[part 20 of 22: package /ComponentTypes]
AUTOSAR XML (schema 4-3-0)
package /ComponentTypes  (continued)
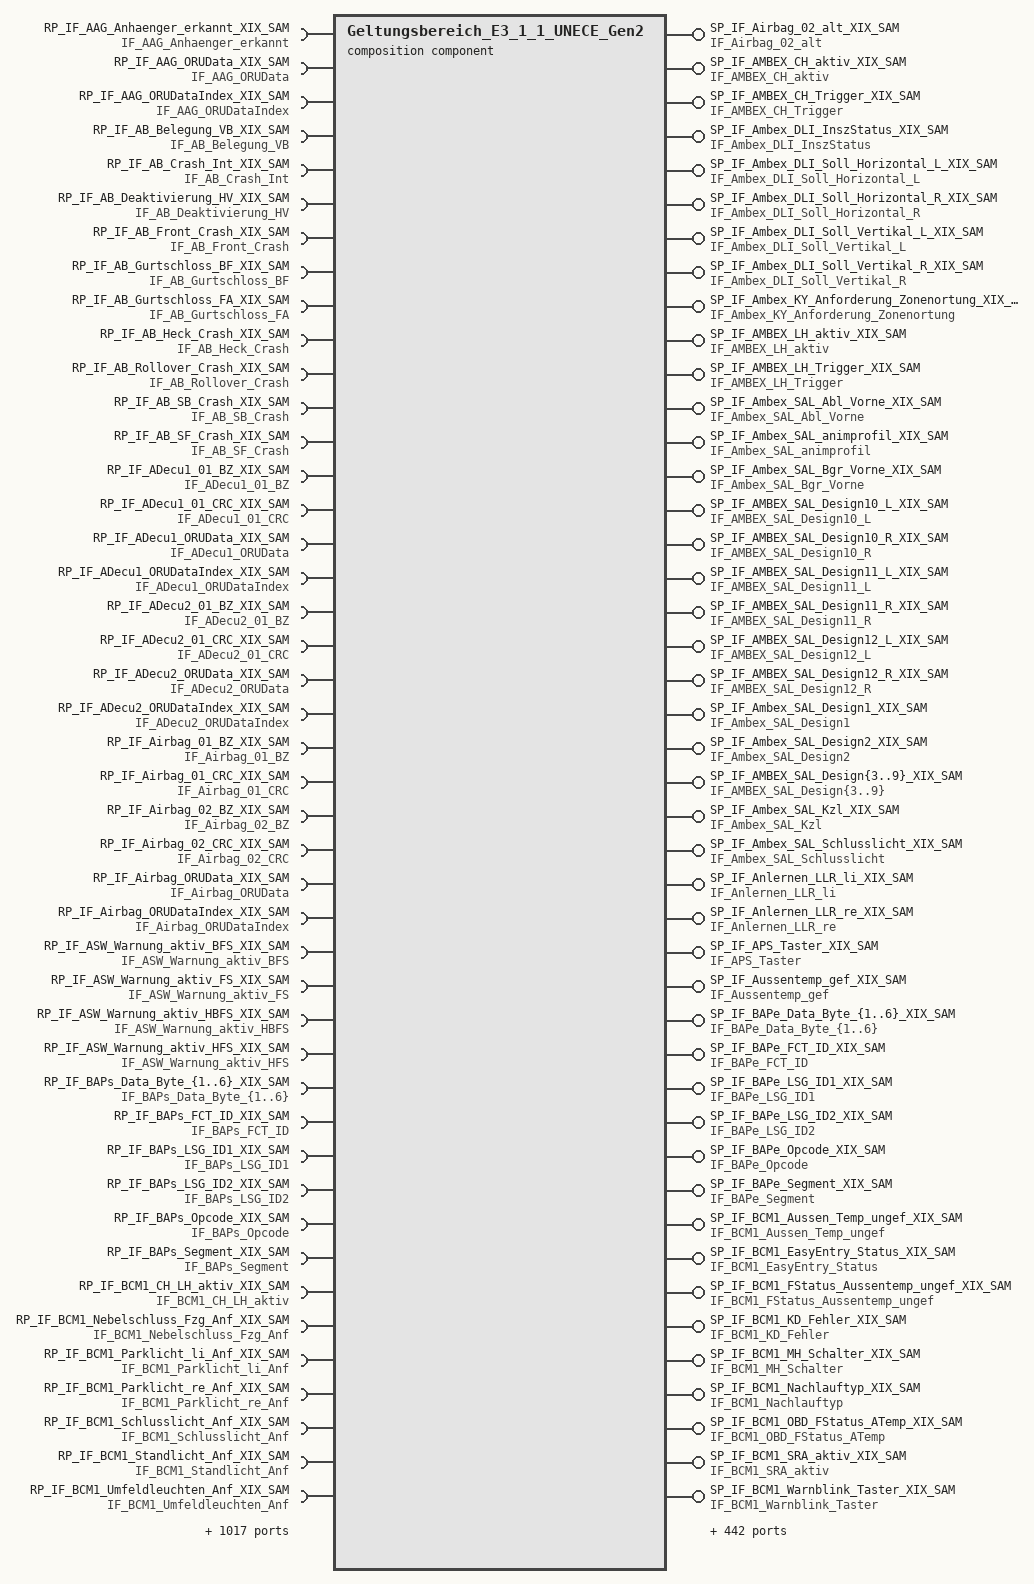
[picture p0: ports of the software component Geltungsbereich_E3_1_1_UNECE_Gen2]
  composition sw component type Geltungsbereich_E3_1_1_UNECE_Gen2
    540 x provide port:
      SP_IF_Airbag_02_alt_XIX_SAM: provided-interface=IF_Airbag_02_alt
      SP_IF_AMBEX_CH_aktiv_XIX_SAM: provided-interface=IF_AMBEX_CH_aktiv
      SP_IF_AMBEX_CH_Trigger_XIX_SAM: provided-interface=IF_AMBEX_CH_Trigger
      SP_IF_Ambex_DLI_InszStatus_XIX_SAM: provided-interface=IF_Ambex_DLI_InszStatus
      SP_IF_Ambex_DLI_Soll_Horizontal_L_XIX_SAM: provided-interface=IF_Ambex_DLI_Soll_Horizontal_L
      SP_IF_Ambex_DLI_Soll_Horizontal_R_XIX_SAM: provided-interface=IF_Ambex_DLI_Soll_Horizontal_R
      SP_IF_Ambex_DLI_Soll_Vertikal_L_XIX_SAM: provided-interface=IF_Ambex_DLI_Soll_Vertikal_L
      SP_IF_Ambex_DLI_Soll_Vertikal_R_XIX_SAM: provided-interface=IF_Ambex_DLI_Soll_Vertikal_R
      SP_IF_Ambex_KY_Anforderung_Zonenortung_XIX_SAM: provided-interface=IF_Ambex_KY_Anforderung_Zonenortung
      SP_IF_AMBEX_LH_aktiv_XIX_SAM: provided-interface=IF_AMBEX_LH_aktiv
      SP_IF_AMBEX_LH_Trigger_XIX_SAM: provided-interface=IF_AMBEX_LH_Trigger
      SP_IF_Ambex_SAL_Abl_Vorne_XIX_SAM: provided-interface=IF_Ambex_SAL_Abl_Vorne
      SP_IF_Ambex_SAL_animprofil_XIX_SAM: provided-interface=IF_Ambex_SAL_animprofil
      SP_IF_Ambex_SAL_Bgr_Vorne_XIX_SAM: provided-interface=IF_Ambex_SAL_Bgr_Vorne
      SP_IF_AMBEX_SAL_Design10_L_XIX_SAM: provided-interface=IF_AMBEX_SAL_Design10_L
      SP_IF_AMBEX_SAL_Design10_R_XIX_SAM: provided-interface=IF_AMBEX_SAL_Design10_R
      SP_IF_AMBEX_SAL_Design11_L_XIX_SAM: provided-interface=IF_AMBEX_SAL_Design11_L
      SP_IF_AMBEX_SAL_Design11_R_XIX_SAM: provided-interface=IF_AMBEX_SAL_Design11_R
      SP_IF_AMBEX_SAL_Design12_L_XIX_SAM: provided-interface=IF_AMBEX_SAL_Design12_L
      SP_IF_AMBEX_SAL_Design12_R_XIX_SAM: provided-interface=IF_AMBEX_SAL_Design12_R
      SP_IF_Ambex_SAL_Design1_XIX_SAM: provided-interface=IF_Ambex_SAL_Design1
      SP_IF_Ambex_SAL_Design2_XIX_SAM: provided-interface=IF_Ambex_SAL_Design2
      SP_IF_AMBEX_SAL_Design{3..9}_XIX_SAM: provided-interface=IF_AMBEX_SAL_Design{3..9}
      SP_IF_Ambex_SAL_Kzl_XIX_SAM: provided-interface=IF_Ambex_SAL_Kzl
      SP_IF_Ambex_SAL_Schlusslicht_XIX_SAM: provided-interface=IF_Ambex_SAL_Schlusslicht
      SP_IF_Anlernen_LLR_li_XIX_SAM: provided-interface=IF_Anlernen_LLR_li
      SP_IF_Anlernen_LLR_re_XIX_SAM: provided-interface=IF_Anlernen_LLR_re
      SP_IF_APS_Taster_XIX_SAM: provided-interface=IF_APS_Taster
      SP_IF_Aussentemp_gef_XIX_SAM: provided-interface=IF_Aussentemp_gef
      SP_IF_BAPe_Data_Byte_{1..6}_XIX_SAM: provided-interface=IF_BAPe_Data_Byte_{1..6}
      SP_IF_BAPe_FCT_ID_XIX_SAM: provided-interface=IF_BAPe_FCT_ID
      SP_IF_BAPe_LSG_ID1_XIX_SAM: provided-interface=IF_BAPe_LSG_ID1
      SP_IF_BAPe_LSG_ID2_XIX_SAM: provided-interface=IF_BAPe_LSG_ID2
      SP_IF_BAPe_Opcode_XIX_SAM: provided-interface=IF_BAPe_Opcode
      SP_IF_BAPe_Segment_XIX_SAM: provided-interface=IF_BAPe_Segment
      SP_IF_BCM1_Aussen_Temp_ungef_XIX_SAM: provided-interface=IF_BCM1_Aussen_Temp_ungef
      SP_IF_BCM1_EasyEntry_Status_XIX_SAM: provided-interface=IF_BCM1_EasyEntry_Status
      SP_IF_BCM1_FStatus_Aussentemp_ungef_XIX_SAM: provided-interface=IF_BCM1_FStatus_Aussentemp_ungef
      SP_IF_BCM1_KD_Fehler_XIX_SAM: provided-interface=IF_BCM1_KD_Fehler
      SP_IF_BCM1_MH_Schalter_XIX_SAM: provided-interface=IF_BCM1_MH_Schalter
      SP_IF_BCM1_Nachlauftyp_XIX_SAM: provided-interface=IF_BCM1_Nachlauftyp
      SP_IF_BCM1_OBD_FStatus_ATemp_XIX_SAM: provided-interface=IF_BCM1_OBD_FStatus_ATemp
      SP_IF_BCM1_SRA_aktiv_XIX_SAM: provided-interface=IF_BCM1_SRA_aktiv
      SP_IF_BCM1_Warnblink_Taster_XIX_SAM: provided-interface=IF_BCM1_Warnblink_Taster
      SP_IF_BCM_01_BZ_XIX_SAM: provided-interface=IF_BCM_01_BZ
      SP_IF_BCM_01_CRC_XIX_SAM: provided-interface=IF_BCM_01_CRC
      SP_IF_BCM_BFS_aktive_MuFu_Fkt_XIX_SAM: provided-interface=IF_BCM_BFS_aktive_MuFu_Fkt
      SP_IF_BCM_BFS_Fernsteuerung_aktiv_XIX_SAM: provided-interface=IF_BCM_BFS_Fernsteuerung_aktiv
      SP_IF_BCM_BFS_Lordose_ab_XIX_SAM: provided-interface=IF_BCM_BFS_Lordose_ab
      SP_IF_BCM_BFS_Lordose_auf_XIX_SAM: provided-interface=IF_BCM_BFS_Lordose_auf
      SP_IF_BCM_BFS_Lordose_vor_XIX_SAM: provided-interface=IF_BCM_BFS_Lordose_vor
      SP_IF_BCM_BFS_Lordose_zurueck_XIX_SAM: provided-interface=IF_BCM_BFS_Lordose_zurueck
      SP_IF_BCM_BFS_Massage_Dauer_XIX_SAM: provided-interface=IF_BCM_BFS_Massage_Dauer
      SP_IF_BCM_BFS_Massage_Intens_Lehne_XIX_SAM: provided-interface=IF_BCM_BFS_Massage_Intens_Lehne
      SP_IF_BCM_BFS_Massage_Intens_Sitz_XIX_SAM: provided-interface=IF_BCM_BFS_Massage_Intens_Sitz
      SP_IF_BCM_BFS_Massage_Intensitaet_XIX_SAM: provided-interface=IF_BCM_BFS_Massage_Intensitaet
      SP_IF_BCM_BFS_Massage_Prg_erweitert_XIX_SAM: provided-interface=IF_BCM_BFS_Massage_Prg_erweitert
      SP_IF_BCM_BFS_Massage_Prg_XIX_SAM: provided-interface=IF_BCM_BFS_Massage_Prg
      SP_IF_BCM_BFS_Massage_Taster_XIX_SAM: provided-interface=IF_BCM_BFS_Massage_Taster
      SP_IF_BCM_BFS_Memory_Abbruch_XIX_SAM: provided-interface=IF_BCM_BFS_Memory_Abbruch
      SP_IF_BCM_BFS_Memory_Pos_XIX_SAM: provided-interface=IF_BCM_BFS_Memory_Pos
      SP_IF_BCM_BFS_Memory_Save_Recall_XIX_SAM: provided-interface=IF_BCM_BFS_Memory_Save_Recall
      SP_IF_BCM_BFS_MSG_Status_XIX_SAM: provided-interface=IF_BCM_BFS_MSG_Status
      SP_IF_BCM_BFS_Multif_Taster_XIX_SAM: provided-interface=IF_BCM_BFS_Multif_Taster
      SP_IF_BCM_BFS_Pneumatik_Verstellung_XIX_SAM: provided-interface=IF_BCM_BFS_Pneumatik_Verstellung
      SP_IF_BCM_BFS_PreCrash_XIX_SAM: provided-interface=IF_BCM_BFS_PreCrash
      SP_IF_BCM_BFS_Programmwippe_XIX_SAM: provided-interface=IF_BCM_BFS_Programmwippe
      SP_IF_BCM_BFS_SW_eng_XIX_SAM: provided-interface=IF_BCM_BFS_SW_eng
      SP_IF_BCM_BFS_SW_weit_XIX_SAM: provided-interface=IF_BCM_BFS_SW_weit
      SP_IF_BCM_BFS_Wellness_Status_XIX_SAM: provided-interface=IF_BCM_BFS_Wellness_Status
      SP_IF_BCM_BFT_geoeffnet_plaus_XIX_SAM: provided-interface=IF_BCM_BFT_geoeffnet_plaus
      SP_IF_BCM_Bremsbelag_Sensor_CND_XIX_SAM: provided-interface=IF_BCM_Bremsbelag_Sensor_CND
      SP_IF_BCM_Bremsbelag_Sensor_NAR_XIX_SAM: provided-interface=IF_BCM_Bremsbelag_Sensor_NAR
      SP_IF_BCM_Bremsbelag_Sensor_Rdw_XIX_SAM: provided-interface=IF_BCM_Bremsbelag_Sensor_Rdw
      SP_IF_BCM_Bremsbelag_Sensor_XIX_SAM: provided-interface=IF_BCM_Bremsbelag_Sensor
      SP_IF_BCM_Bremsfluessigkeit_Sensor_XIX_SAM: provided-interface=IF_BCM_Bremsfluessigkeit_Sensor
      SP_IF_BCM_Drehwinkel_HL_XIX_SAM: provided-interface=IF_BCM_Drehwinkel_HL
      SP_IF_BCM_Drehwinkel_VL_XIX_SAM: provided-interface=IF_BCM_Drehwinkel_VL
      SP_IF_BCM_Drehwinkelsensortausch_HL_XIX_SAM: provided-interface=IF_BCM_Drehwinkelsensortausch_HL
      SP_IF_BCM_Drehwinkelsensortausch_VL_XIX_SAM: provided-interface=IF_BCM_Drehwinkelsensortausch_VL
      SP_IF_BCM_Eco_Charisma_Taste_XIX_SAM: provided-interface=IF_BCM_Eco_Charisma_Taste
      SP_IF_BCM_Fehlerspeicher_loeschen_XIX_SAM: provided-interface=IF_BCM_Fehlerspeicher_loeschen
      SP_IF_BCM_FH_Freigabe_XIX_SAM: provided-interface=IF_BCM_FH_Freigabe
      SP_IF_BCM_FS_aktive_MuFu_Fkt_XIX_SAM: provided-interface=IF_BCM_FS_aktive_MuFu_Fkt
      SP_IF_BCM_FS_Lordose_ab_XIX_SAM: provided-interface=IF_BCM_FS_Lordose_ab
      SP_IF_BCM_FS_Lordose_auf_XIX_SAM: provided-interface=IF_BCM_FS_Lordose_auf
      SP_IF_BCM_FS_Lordose_vor_XIX_SAM: provided-interface=IF_BCM_FS_Lordose_vor
      SP_IF_BCM_FS_Lordose_zurueck_XIX_SAM: provided-interface=IF_BCM_FS_Lordose_zurueck
      SP_IF_BCM_FS_Massage_Dauer_XIX_SAM: provided-interface=IF_BCM_FS_Massage_Dauer
      SP_IF_BCM_FS_Massage_Intens_Lehne_XIX_SAM: provided-interface=IF_BCM_FS_Massage_Intens_Lehne
      SP_IF_BCM_FS_Massage_Intens_Sitz_XIX_SAM: provided-interface=IF_BCM_FS_Massage_Intens_Sitz
      SP_IF_BCM_FS_Massage_Intensitaet_XIX_SAM: provided-interface=IF_BCM_FS_Massage_Intensitaet
      SP_IF_BCM_FS_Massage_Prg_erweitert_XIX_SAM: provided-interface=IF_BCM_FS_Massage_Prg_erweitert
      SP_IF_BCM_FS_Massage_Prg_XIX_SAM: provided-interface=IF_BCM_FS_Massage_Prg
      SP_IF_BCM_FS_Massage_Taster_XIX_SAM: provided-interface=IF_BCM_FS_Massage_Taster
      SP_IF_BCM_FS_Memory_Abbruch_XIX_SAM: provided-interface=IF_BCM_FS_Memory_Abbruch
      SP_IF_BCM_FS_Memory_Pos_XIX_SAM: provided-interface=IF_BCM_FS_Memory_Pos
      SP_IF_BCM_FS_Memory_Save_Recall_XIX_SAM: provided-interface=IF_BCM_FS_Memory_Save_Recall
      SP_IF_BCM_FS_MSG_Status_XIX_SAM: provided-interface=IF_BCM_FS_MSG_Status
      SP_IF_BCM_FS_Multif_Taster_XIX_SAM: provided-interface=IF_BCM_FS_Multif_Taster
      SP_IF_BCM_FS_Pneumatik_Verstellung_XIX_SAM: provided-interface=IF_BCM_FS_Pneumatik_Verstellung
      SP_IF_BCM_FS_PreCrash_XIX_SAM: provided-interface=IF_BCM_FS_PreCrash
      SP_IF_BCM_FS_Programmwippe_XIX_SAM: provided-interface=IF_BCM_FS_Programmwippe
      SP_IF_BCM_FS_SW_eng_XIX_SAM: provided-interface=IF_BCM_FS_SW_eng
      SP_IF_BCM_FS_SW_weit_XIX_SAM: provided-interface=IF_BCM_FS_SW_weit
      SP_IF_BCM_FS_Wellness_Status_XIX_SAM: provided-interface=IF_BCM_FS_Wellness_Status
      SP_IF_BCM_FT_geoeffnet_plaus_XIX_SAM: provided-interface=IF_BCM_FT_geoeffnet_plaus
      SP_IF_BCM_Kennung_RL_Fzg_XIX_SAM: provided-interface=IF_BCM_Kennung_RL_Fzg
      SP_IF_BCM_KiSi_Umschalt_gesperrt_XIX_SAM: provided-interface=IF_BCM_KiSi_Umschalt_gesperrt
      SP_IF_BCM_Komfortfkt_Freigabe_XIX_SAM: provided-interface=IF_BCM_Komfortfkt_Freigabe
      SP_IF_BCM_Kuehlmittel_Sensor_XIX_SAM: provided-interface=IF_BCM_Kuehlmittel_Sensor
      SP_IF_BCM_LINDa_Toggle_XIX_SAM: provided-interface=IF_BCM_LINDa_Toggle
      SP_IF_BCM_LRH_Taster_XIX_SAM: provided-interface=IF_BCM_LRH_Taster
      SP_IF_BCM_P_Mode_aktiv_XIX_SAM: provided-interface=IF_BCM_P_Mode_aktiv
      SP_IF_BCM_P_Mode_FH_Kl15_aus_aktiv_XIX_SAM: provided-interface=IF_BCM_P_Mode_FH_Kl15_aus_aktiv
      SP_IF_BCM_P_Mode_FH_Reversierschwelle_XIX_SAM: provided-interface=IF_BCM_P_Mode_FH_Reversierschwelle
      SP_IF_BCM_RACE_Mode_aktiv_XIX_SAM: provided-interface=IF_BCM_RACE_Mode_aktiv
      SP_IF_BCM_RGB_Adressierungsart_XIX_SAM: provided-interface=IF_BCM_RGB_Adressierungsart
      SP_IF_BCM_RGB_Bewertung_Dimmzeit_XIX_SAM: provided-interface=IF_BCM_RGB_Bewertung_Dimmzeit
      SP_IF_BCM_RGB_Blau_XIX_SAM: provided-interface=IF_BCM_RGB_Blau
      SP_IF_BCM_RGB_Dimmrampe_XIX_SAM: provided-interface=IF_BCM_RGB_Dimmrampe
      SP_IF_BCM_RGB_Dimmzeit_Zeitbasis_XIX_SAM: provided-interface=IF_BCM_RGB_Dimmzeit_Zeitbasis
      SP_IF_BCM_RGB_Gruen_XIX_SAM: provided-interface=IF_BCM_RGB_Gruen
      SP_IF_BCM_RGB_Gueltigkeit_XIX_SAM: provided-interface=IF_BCM_RGB_Gueltigkeit
      SP_IF_BCM_RGB_Intensitaet_XIX_SAM: provided-interface=IF_BCM_RGB_Intensitaet
      SP_IF_BCM_RGB_Normierung_Intensitaet_XIX_SAM: provided-interface=IF_BCM_RGB_Normierung_Intensitaet
      SP_IF_BCM_RGB_Rot_XIX_SAM: provided-interface=IF_BCM_RGB_Rot
      SP_IF_BCM_RGB_Slave_Adresse_XIX_SAM: provided-interface=IF_BCM_RGB_Slave_Adresse
      SP_IF_BCM_RGB_Sonderfunktion_XIX_SAM: provided-interface=IF_BCM_RGB_Sonderfunktion
      SP_IF_BCM_SBE_XIX_SAM: provided-interface=IF_BCM_SBE
      SP_IF_BCM_SGT_Pumpe_BFS_XIX_SAM: provided-interface=IF_BCM_SGT_Pumpe_BFS
      SP_IF_BCM_SGT_Pumpe_FS_XIX_SAM: provided-interface=IF_BCM_SGT_Pumpe_FS
      SP_IF_BCM_SPR_Nachregelung_Freigabe_XIX_SAM: provided-interface=IF_BCM_SPR_Nachregelung_Freigabe
      SP_IF_BCM_Systemfunkionstest_BFS_XIX_SAM: provided-interface=IF_BCM_Systemfunkionstest_BFS
      SP_IF_BCM_Systemfunkionstest_FS_XIX_SAM: provided-interface=IF_BCM_Systemfunkionstest_FS
      SP_IF_BCM_Tankklappensteller_Fehler_XIX_SAM: provided-interface=IF_BCM_Tankklappensteller_Fehler
      SP_IF_BCM_Waschwasser_Sensor_XIX_SAM: provided-interface=IF_BCM_Waschwasser_Sensor
      SP_IF_BCM_Wischer_Parklage_XIX_SAM: provided-interface=IF_BCM_Wischer_Parklage
      SP_IF_Bel_DiETa_Car_XIX_SAM: provided-interface=IF_Bel_DiETa_Car
      SP_IF_Bel_DiETa_Lock_Unlock_XIX_SAM: provided-interface=IF_Bel_DiETa_Lock_Unlock
      SP_IF_Bel_LiSi_Defrost_XIX_SAM: provided-interface=IF_Bel_LiSi_Defrost
      SP_IF_Bel_LiSi_FSH_XIX_SAM: provided-interface=IF_Bel_LiSi_FSH
      SP_IF_Bel_LiSi_HSH_XIX_SAM: provided-interface=IF_Bel_LiSi_HSH
      SP_IF_BH_Blinker_Fehler_XIX_SAM: provided-interface=IF_BH_Blinker_Fehler
      SP_IF_BH_Blinker_li_XIX_SAM: provided-interface=IF_BH_Blinker_li
      SP_IF_BH_Blinker_re_XIX_SAM: provided-interface=IF_BH_Blinker_re
      SP_IF_BH_Fernlicht_XIX_SAM: provided-interface=IF_BH_Fernlicht
      SP_IF_BH_Lichthupe_XIX_SAM: provided-interface=IF_BH_Lichthupe
      SP_IF_BRL_Bremslicht_Schalter_XIX_SAM: provided-interface=IF_BRL_Bremslicht_Schalter
      SP_IF_Deaktivierung_RS_XIX_SAM: provided-interface=IF_Deaktivierung_RS
      SP_IF_DI_KL_58xd_XIX_SAM: provided-interface=IF_DI_KL_58xd
      SP_IF_DI_KL_58xs_XIX_SAM: provided-interface=IF_DI_KL_58xs
      SP_IF_Empfindlichkeit_LS_XIX_SAM: provided-interface=IF_Empfindlichkeit_LS
      SP_IF_Empfindlichkeit_RS_XIX_SAM: provided-interface=IF_Empfindlichkeit_RS
      SP_IF_ESP_v_Signal_8Bit_XIX_SAM: provided-interface=IF_ESP_v_Signal_8Bit
      SP_IF_ESP_v_Signal_XIX_SAM: provided-interface=IF_ESP_v_Signal
      SP_IF_FAS_Profile_Taster_XIX_SAM: provided-interface=IF_FAS_Profile_Taster
      SP_IF_FAS_Taster_Fehler_XIX_SAM: provided-interface=IF_FAS_Taster_Fehler
      SP_IF_FAS_Taster_XIX_SAM: provided-interface=IF_FAS_Taster
      SP_IF_FHSG_MST_Architektur_XIX_SAM: provided-interface=IF_FHSG_MST_Architektur
      SP_IF_FHSG_MST_Aussentemp_ungefiltert_XIX_SAM: provided-interface=IF_FHSG_MST_Aussentemp_ungefiltert
      SP_IF_FHSG_MST_BT_Blockerwartung_XIX_SAM: provided-interface=IF_FHSG_MST_BT_Blockerwartung
      SP_IF_FHSG_MST_Crashfall_erkannt_XIX_SAM: provided-interface=IF_FHSG_MST_Crashfall_erkannt
      SP_IF_FHSG_MST_FH_HBFS_AutoHoch_XIX_SAM: provided-interface=IF_FHSG_MST_FH_HBFS_AutoHoch
      SP_IF_FHSG_MST_FH_HBFS_AutoTief_XIX_SAM: provided-interface=IF_FHSG_MST_FH_HBFS_AutoTief
      SP_IF_FHSG_MST_FH_HBFS_ManHoch_XIX_SAM: provided-interface=IF_FHSG_MST_FH_HBFS_ManHoch
      SP_IF_FHSG_MST_FH_HBFS_ManTief_XIX_SAM: provided-interface=IF_FHSG_MST_FH_HBFS_ManTief
      SP_IF_FHSG_MST_FH_HFS_AutoHoch_XIX_SAM: provided-interface=IF_FHSG_MST_FH_HFS_AutoHoch
      SP_IF_FHSG_MST_FH_HFS_AutoTief_XIX_SAM: provided-interface=IF_FHSG_MST_FH_HFS_AutoTief
      SP_IF_FHSG_MST_FH_HFS_ManHoch_XIX_SAM: provided-interface=IF_FHSG_MST_FH_HFS_ManHoch
      SP_IF_FHSG_MST_FH_HFS_ManTief_XIX_SAM: provided-interface=IF_FHSG_MST_FH_HFS_ManTief
      SP_IF_FHSG_MST_FH_KomfortHoch_XIX_SAM: provided-interface=IF_FHSG_MST_FH_KomfortHoch
      SP_IF_FHSG_MST_FH_Komforttief_XIX_SAM: provided-interface=IF_FHSG_MST_FH_Komforttief
      SP_IF_FHSG_MST_FT_Blockerwartung_XIX_SAM: provided-interface=IF_FHSG_MST_FT_Blockerwartung
      SP_IF_FHSG_MST_FT_FH_H_Kisi_ein_XIX_SAM: provided-interface=IF_FHSG_MST_FT_FH_H_Kisi_ein
      SP_IF_FHSG_MST_HBFS_Blockerwartung_XIX_SAM: provided-interface=IF_FHSG_MST_HBFS_Blockerwartung
      SP_IF_FHSG_MST_HFS_Blockerwartung_XIX_SAM: provided-interface=IF_FHSG_MST_HFS_Blockerwartung
      SP_IF_FHSG_MST_Lenkigkeit_XIX_SAM: provided-interface=IF_FHSG_MST_Lenkigkeit
      SP_IF_FHSG_MST_Precrash_XIX_SAM: provided-interface=IF_FHSG_MST_Precrash
      SP_IF_Fronthaube_geoeffnet_XIX_SAM: provided-interface=IF_Fronthaube_geoeffnet
      SP_IF_FS_Luftfeuchte_rel_XIX_SAM: provided-interface=IF_FS_Luftfeuchte_rel
      SP_IF_FS_ResponseError_XIX_SAM: provided-interface=IF_FS_ResponseError
      SP_IF_FS_Taupunkt_XIX_SAM: provided-interface=IF_FS_Taupunkt
      SP_IF_FS_Temp_Scheibe_XIX_SAM: provided-interface=IF_FS_Temp_Scheibe
      SP_IF_FS_Temp_Sensor_XIX_SAM: provided-interface=IF_FS_Temp_Sensor
      SP_IF_HBFS_FH_Bew_hoch_XIX_SAM: provided-interface=IF_HBFS_FH_Bew_hoch
      SP_IF_HBFS_FH_Bew_tief_XIX_SAM: provided-interface=IF_HBFS_FH_Bew_tief
      SP_IF_HBFS_FH_Block_XIX_SAM: provided-interface=IF_HBFS_FH_Block
      SP_IF_HBFS_FH_Fang_XIX_SAM: provided-interface=IF_HBFS_FH_Fang
      SP_IF_HBFS_FH_normiert_XIX_SAM: provided-interface=IF_HBFS_FH_normiert
      SP_IF_HBFS_FH_Oeffnung_XIX_SAM: provided-interface=IF_HBFS_FH_Oeffnung
      SP_IF_HBFS_FH_S_AutoHoch_XIX_SAM: provided-interface=IF_HBFS_FH_S_AutoHoch
      SP_IF_HBFS_FH_S_AutoTief_XIX_SAM: provided-interface=IF_HBFS_FH_S_AutoTief
      SP_IF_HBFS_FH_S_ManHoch_XIX_SAM: provided-interface=IF_HBFS_FH_S_ManHoch
      SP_IF_HBFS_FH_S_ManTief_XIX_SAM: provided-interface=IF_HBFS_FH_S_ManTief
      SP_IF_HBFS_FH_Thermo_XIX_SAM: provided-interface=IF_HBFS_FH_Thermo
      SP_IF_HBFS_gesafet_XIX_SAM: provided-interface=IF_HBFS_gesafet
      SP_IF_HBFS_KiSi_Fehler_XIX_SAM: provided-interface=IF_HBFS_KiSi_Fehler
      SP_IF_HBFS_Lock_Taster_inv_XIX_SAM: provided-interface=IF_HBFS_Lock_Taster_inv
      SP_IF_HBFS_Oben_Block_erw_XIX_SAM: provided-interface=IF_HBFS_Oben_Block_erw
      SP_IF_HBFS_Seitenrollo_hoch_XIX_SAM: provided-interface=IF_HBFS_Seitenrollo_hoch
      SP_IF_HBFS_Seitenrollo_tief_XIX_SAM: provided-interface=IF_HBFS_Seitenrollo_tief
      SP_IF_HBFS_SK_betaetigt_XIX_SAM: provided-interface=IF_HBFS_SK_betaetigt
      SP_IF_HBFS_Sperrklinke_XIX_SAM: provided-interface=IF_HBFS_Sperrklinke
      SP_IF_HBFS_Status_KiSi_inv_XIX_SAM: provided-interface=IF_HBFS_Status_KiSi_inv
      SP_IF_HBFS_Status_KiSi_XIX_SAM: provided-interface=IF_HBFS_Status_KiSi
      SP_IF_HBFS_TAG_betaetigt_XIX_SAM: provided-interface=IF_HBFS_TAG_betaetigt
      SP_IF_HBFS_TCR_Mode_aktiv_XIX_SAM: provided-interface=IF_HBFS_TCR_Mode_aktiv
      SP_IF_HBFS_TIG_betaetigt_oeffnen_XIX_SAM: provided-interface=IF_HBFS_TIG_betaetigt_oeffnen
      SP_IF_HBFS_TIG_betaetigt_schliessen_XIX_SAM: provided-interface=IF_HBFS_TIG_betaetigt_schliessen
      SP_IF_HBFS_TIG_betaetigt_XIX_SAM: provided-interface=IF_HBFS_TIG_betaetigt
      SP_IF_HBFS_Tuer_geoeffnet_XIX_SAM: provided-interface=IF_HBFS_Tuer_geoeffnet
      SP_IF_HBFS_Tuer_Status_XIX_SAM: provided-interface=IF_HBFS_Tuer_Status
      SP_IF_HBFS_Tuerschloss_defekt_XIX_SAM: provided-interface=IF_HBFS_Tuerschloss_defekt
      SP_IF_HBFS_UEKB_aktiviert_XIX_SAM: provided-interface=IF_HBFS_UEKB_aktiviert
      SP_IF_HBFS_Unten_Block_erw_XIX_SAM: provided-interface=IF_HBFS_Unten_Block_erw
      SP_IF_HBFS_verriegelt_XIX_SAM: provided-interface=IF_HBFS_verriegelt
      SP_IF_HBFS_Vorraste_betaetigt_XIX_SAM: provided-interface=IF_HBFS_Vorraste_betaetigt
      SP_IF_HD_Hauptraste_Auth_XIX_SAM: provided-interface=IF_HD_Hauptraste_Auth
      SP_IF_HD_Hauptraste_XIX_SAM: provided-interface=IF_HD_Hauptraste
      SP_IF_HD_Vorraste_Auth_XIX_SAM: provided-interface=IF_HD_Vorraste_Auth
      SP_IF_HD_Vorraste_XIX_SAM: provided-interface=IF_HD_Vorraste
      SP_IF_HFS_FH_Bew_hoch_XIX_SAM: provided-interface=IF_HFS_FH_Bew_hoch
      SP_IF_HFS_FH_Bew_tief_XIX_SAM: provided-interface=IF_HFS_FH_Bew_tief
      SP_IF_HFS_FH_Block_XIX_SAM: provided-interface=IF_HFS_FH_Block
      SP_IF_HFS_FH_Fang_XIX_SAM: provided-interface=IF_HFS_FH_Fang
      SP_IF_HFS_FH_normiert_XIX_SAM: provided-interface=IF_HFS_FH_normiert
      SP_IF_HFS_FH_Oeffnung_XIX_SAM: provided-interface=IF_HFS_FH_Oeffnung
      SP_IF_HFS_FH_S_AutoHoch_XIX_SAM: provided-interface=IF_HFS_FH_S_AutoHoch
      SP_IF_HFS_FH_S_AutoTief_XIX_SAM: provided-interface=IF_HFS_FH_S_AutoTief
      SP_IF_HFS_FH_S_ManHoch_XIX_SAM: provided-interface=IF_HFS_FH_S_ManHoch
      SP_IF_HFS_FH_S_ManTief_XIX_SAM: provided-interface=IF_HFS_FH_S_ManTief
      SP_IF_HFS_FH_Thermo_XIX_SAM: provided-interface=IF_HFS_FH_Thermo
      SP_IF_HFS_gesafet_XIX_SAM: provided-interface=IF_HFS_gesafet
      SP_IF_HFS_Heckrollotaster_betaetigt_XIX_SAM: provided-interface=IF_HFS_Heckrollotaster_betaetigt
      SP_IF_HFS_KiSi_Fehler_XIX_SAM: provided-interface=IF_HFS_KiSi_Fehler
      SP_IF_HFS_Lock_Taster_inv_XIX_SAM: provided-interface=IF_HFS_Lock_Taster_inv
      SP_IF_HFS_Oben_Block_erw_XIX_SAM: provided-interface=IF_HFS_Oben_Block_erw
      SP_IF_HFS_Seitenrollo_hoch_XIX_SAM: provided-interface=IF_HFS_Seitenrollo_hoch
      SP_IF_HFS_Seitenrollo_tief_XIX_SAM: provided-interface=IF_HFS_Seitenrollo_tief
      SP_IF_HFS_SK_betaetigt_XIX_SAM: provided-interface=IF_HFS_SK_betaetigt
      SP_IF_HFS_Status_KiSi_XIX_SAM: provided-interface=IF_HFS_Status_KiSi
      SP_IF_HFS_TAG_betaetigt_XIX_SAM: provided-interface=IF_HFS_TAG_betaetigt
      SP_IF_HFS_TCR_Mode_aktiv_XIX_SAM: provided-interface=IF_HFS_TCR_Mode_aktiv
      SP_IF_HFS_TIG_betaetigt_oeffnen_XIX_SAM: provided-interface=IF_HFS_TIG_betaetigt_oeffnen
      SP_IF_HFS_TIG_betaetigt_schliessen_XIX_SAM: provided-interface=IF_HFS_TIG_betaetigt_schliessen
      SP_IF_HFS_TIG_betaetigt_XIX_SAM: provided-interface=IF_HFS_TIG_betaetigt
      SP_IF_HFS_Tuer_geoeffnet_XIX_SAM: provided-interface=IF_HFS_Tuer_geoeffnet
      SP_IF_HFS_Tuer_Status_QBit_XIX_SAM: provided-interface=IF_HFS_Tuer_Status_QBit
      SP_IF_HFS_Tuer_Status_XIX_SAM: provided-interface=IF_HFS_Tuer_Status
      SP_IF_HFS_Tueroeffnen_Warnung_XIX_SAM: provided-interface=IF_HFS_Tueroeffnen_Warnung
      SP_IF_HFS_Tuerschloss_defekt_XIX_SAM: provided-interface=IF_HFS_Tuerschloss_defekt
      SP_IF_HFS_UEKB_aktiviert_XIX_SAM: provided-interface=IF_HFS_UEKB_aktiviert
      SP_IF_HFS_Unten_Block_erw_XIX_SAM: provided-interface=IF_HFS_Unten_Block_erw
      SP_IF_HFS_verriegelt_XIX_SAM: provided-interface=IF_HFS_verriegelt
      SP_IF_HFS_Vorraste_betaetigt_XIX_SAM: provided-interface=IF_HFS_Vorraste_betaetigt
      SP_IF_HLR_LRH_Freigabe_XIX_SAM: provided-interface=IF_HLR_LRH_Freigabe
      SP_IF_HSH_Status_XIX_SAM: provided-interface=IF_HSH_Status
      SP_IF_HW_Drehfalle_Tuer_HL_Auth_XIX_SAM: provided-interface=IF_HW_Drehfalle_Tuer_HL_Auth
      SP_IF_HW_Drehfalle_Tuer_HL_XIX_SAM: provided-interface=IF_HW_Drehfalle_Tuer_HL
      SP_IF_HW_Drehfalle_Tuer_HR_Auth_XIX_SAM: provided-interface=IF_HW_Drehfalle_Tuer_HR_Auth
      SP_IF_HW_Drehfalle_Tuer_HR_XIX_SAM: provided-interface=IF_HW_Drehfalle_Tuer_HR
      SP_IF_HW_HD_Taste_Innenraum_XIX_SAM: provided-interface=IF_HW_HD_Taste_Innenraum
      SP_IF_HW_HSB_erkannt_XIX_SAM: provided-interface=IF_HW_HSB_erkannt
      SP_IF_HW_Softtouch_betaetigt_XIX_SAM: provided-interface=IF_HW_Softtouch_betaetigt
      SP_IF_HW_Status_Schloss_gesafet_HL_XIX_SAM: provided-interface=IF_HW_Status_Schloss_gesafet_HL
      SP_IF_HW_Status_Schloss_gesafet_HR_XIX_SAM: provided-interface=IF_HW_Status_Schloss_gesafet_HR
      SP_IF_HW_Status_Schloss_safed_HL_Auth_XIX_SAM: provided-interface=IF_HW_Status_Schloss_safed_HL_Auth
      SP_IF_HW_Status_Schloss_safed_HR_Auth_XIX_SAM: provided-interface=IF_HW_Status_Schloss_safed_HR_Auth
      SP_IF_HW_Status_Schloss_verr_HL_Auth_XIX_SAM: provided-interface=IF_HW_Status_Schloss_verr_HL_Auth
      SP_IF_HW_Status_Schloss_verr_HR_Auth_XIX_SAM: provided-interface=IF_HW_Status_Schloss_verr_HR_Auth
      SP_IF_HW_Status_Schloss_verriegelt_HL_XIX_SAM: provided-interface=IF_HW_Status_Schloss_verriegelt_HL
      SP_IF_HW_Status_Schloss_verriegelt_HR_XIX_SAM: provided-interface=IF_HW_Status_Schloss_verriegelt_HR
      SP_IF_HW_Tankdeckel_offen_XIX_SAM: provided-interface=IF_HW_Tankdeckel_offen
      SP_IF_IL_Dachkonsole_Adressat_XIX_SAM: provided-interface=IF_IL_Dachkonsole_Adressat
      SP_IF_IL_Dachkonsole_Dimmzeit_XIX_SAM: provided-interface=IF_IL_Dachkonsole_Dimmzeit
      SP_IF_IL_Dachkonsole_Zeitbasis_XIX_SAM: provided-interface=IF_IL_Dachkonsole_Zeitbasis
      SP_IF_IL_Dachkonsole_Zielhelligkeit_XIX_SAM: provided-interface=IF_IL_Dachkonsole_Zielhelligkeit
      SP_IF_IL_Innenlicht_aktiv_XIX_SAM: provided-interface=IF_IL_Innenlicht_aktiv
      SP_IF_IL_Klemme_30G_aktiv_XIX_SAM: provided-interface=IF_IL_Klemme_30G_aktiv
      SP_IF_IL_TSG_BFS_Dimmzeit_{1..4}_XIX_SAM: provided-interface=IF_IL_TSG_BFS_Dimmzeit_{1..4}
      SP_IF_IL_TSG_BFS_Dimmzeit_Basis_{1..4}_XIX_SAM: provided-interface=IF_IL_TSG_BFS_Dimmzeit_Basis_{1..4}
      SP_IF_IL_TSG_BFS_Zielhelligkeit_{1..4}_XIX_SAM: provided-interface=IF_IL_TSG_BFS_Zielhelligkeit_{1..4}
      SP_IF_IL_TSG_FS_Dimmzeit_{1..4}_XIX_SAM: provided-interface=IF_IL_TSG_FS_Dimmzeit_{1..4}
      SP_IF_IL_TSG_FS_Dimmzeit_Basis_{1..4}_XIX_SAM: provided-interface=IF_IL_TSG_FS_Dimmzeit_Basis_{1..4}
      SP_IF_IL_TSG_FS_Zielhelligkeit_{1..4}_XIX_SAM: provided-interface=IF_IL_TSG_FS_Zielhelligkeit_{1..4}
      SP_IF_IL_TSG_HBFS_Dimmzeit_{1..4}_XIX_SAM: provided-interface=IF_IL_TSG_HBFS_Dimmzeit_{1..4}
      SP_IF_IL_TSG_HBFS_Dimmzeit_Basis_{1..4}_XIX_SAM: provided-interface=IF_IL_TSG_HBFS_Dimmzeit_Basis_{1..4}
      SP_IF_IL_TSG_HBFS_Zielhelligkeit_{1..4}_XIX_SAM: provided-interface=IF_IL_TSG_HBFS_Zielhelligkeit_{1..4}
      SP_IF_IL_TSG_HFS_Dimmzeit_{1..4}_XIX_SAM: provided-interface=IF_IL_TSG_HFS_Dimmzeit_{1..4}
      SP_IF_IL_TSG_HFS_Dimmzeit_Basis_{1..4}_XIX_SAM: provided-interface=IF_IL_TSG_HFS_Dimmzeit_Basis_{1..4}
      SP_IF_IL_TSG_HFS_Zielhelligkeit_{1..4}_XIX_SAM: provided-interface=IF_IL_TSG_HFS_Zielhelligkeit_{1..4}
      SP_IF_KL_LRH_Stufe_XIX_SAM: provided-interface=IF_KL_LRH_Stufe
      SP_IF_Klemme_15_XIX_SAM: provided-interface=IF_Klemme_15
      SP_IF_Klemme_X_WWS_XIX_SAM: provided-interface=IF_Klemme_X_WWS
      SP_IF_KN_BCM1_DiagPfad_XIX_SAM: provided-interface=IF_KN_BCM1_DiagPfad
      SP_IF_KST_BSW_Fehlermode2_XIX_SAM: provided-interface=IF_KST_BSW_Fehlermode2
      SP_IF_KST_BSW_Klemme_15_HW_Ist_XIX_SAM: provided-interface=IF_KST_BSW_Klemme_15_HW_Ist
      SP_IF_KST_BSW_Klemmenhochschalten_Sper_XIX_SAM: provided-interface=IF_KST_BSW_Klemmenhochschalten_Sper
      SP_IF_KST_BSW_Not_Taster_betaetigt_XIX_SAM: provided-interface=IF_KST_BSW_Not_Taster_betaetigt
      SP_IF_KST_BSW_ZAT_betaetigt_XIX_SAM: provided-interface=IF_KST_BSW_ZAT_betaetigt
      SP_IF_KY_UHF_aktiver_Scantyp_XIX_SAM: provided-interface=IF_KY_UHF_aktiver_Scantyp
      SP_IF_KY_UHF_Bitrate_XIX_SAM: provided-interface=IF_KY_UHF_Bitrate
      SP_IF_KY_UHF_Telegramm_CRCStatus_XIX_SAM: provided-interface=IF_KY_UHF_Telegramm_CRCStatus
      SP_IF_KY_UHF_Transceiver_Modus_XIX_SAM: provided-interface=IF_KY_UHF_Transceiver_Modus
      SP_IF_LH_S_3_Bremsl_def_XIX_SAM: provided-interface=IF_LH_S_3_Bremsl_def
      SP_IF_LH_S_Aussenlicht_def_XIX_SAM: provided-interface=IF_LH_S_Aussenlicht_def
      SP_IF_LH_S_Blinker_li_def_XIX_SAM: provided-interface=IF_LH_S_Blinker_li_def
      SP_IF_LH_S_Blinker_re_def_XIX_SAM: provided-interface=IF_LH_S_Blinker_re_def
      SP_IF_LH_S_Brems_Blk_li_def_XIX_SAM: provided-interface=IF_LH_S_Brems_Blk_li_def
      SP_IF_LH_S_Brems_Blk_re_def_XIX_SAM: provided-interface=IF_LH_S_Brems_Blk_re_def
      SP_IF_LH_S_Bremsl_li_def_XIX_SAM: provided-interface=IF_LH_S_Bremsl_li_def
      SP_IF_LH_S_Bremsl_li_ges_def_XIX_SAM: provided-interface=IF_LH_S_Bremsl_li_ges_def
      SP_IF_LH_S_Bremsl_re_def_XIX_SAM: provided-interface=IF_LH_S_Bremsl_re_def
      SP_IF_LH_S_Bremsl_re_ges_def_XIX_SAM: provided-interface=IF_LH_S_Bremsl_re_ges_def
      SP_IF_LH_S_Bremslicht_H_aktiv_XIX_SAM: provided-interface=IF_LH_S_Bremslicht_H_aktiv
      SP_IF_LH_S_Kennzl_def_XIX_SAM: provided-interface=IF_LH_S_Kennzl_def
      SP_IF_LH_S_Nebel_li_def_XIX_SAM: provided-interface=IF_LH_S_Nebel_li_def
      SP_IF_LH_S_Nebel_mi_def_XIX_SAM: provided-interface=IF_LH_S_Nebel_mi_def
      SP_IF_LH_S_Nebel_re_def_XIX_SAM: provided-interface=IF_LH_S_Nebel_re_def
      SP_IF_LH_S_Rueckf_li_def_XIX_SAM: provided-interface=IF_LH_S_Rueckf_li_def
      SP_IF_LH_S_Rueckf_mi_def_XIX_SAM: provided-interface=IF_LH_S_Rueckf_mi_def
      SP_IF_LH_S_Rueckf_re_def_XIX_SAM: provided-interface=IF_LH_S_Rueckf_re_def
      SP_IF_LH_S_Schluss_Brems_li_def_XIX_SAM: provided-interface=IF_LH_S_Schluss_Brems_li_def
      SP_IF_LH_S_Schluss_Brems_mi_def_XIX_SAM: provided-interface=IF_LH_S_Schluss_Brems_mi_def
      SP_IF_LH_S_Schluss_Brems_Nebel_li_def_XIX_SAM: provided-interface=IF_LH_S_Schluss_Brems_Nebel_li_def
      SP_IF_LH_S_Schluss_Brems_Nebel_re_def_XIX_SAM: provided-interface=IF_LH_S_Schluss_Brems_Nebel_re_def
      SP_IF_LH_S_Schluss_Brems_re_def_XIX_SAM: provided-interface=IF_LH_S_Schluss_Brems_re_def
      SP_IF_LH_S_Schluss_Nebel_li_def_XIX_SAM: provided-interface=IF_LH_S_Schluss_Nebel_li_def
      SP_IF_LH_S_Schluss_Nebel_re_def_XIX_SAM: provided-interface=IF_LH_S_Schluss_Nebel_re_def
      SP_IF_LH_S_Schlusslicht_li_def_XIX_SAM: provided-interface=IF_LH_S_Schlusslicht_li_def
      SP_IF_LH_S_Schlusslicht_mi_def_XIX_SAM: provided-interface=IF_LH_S_Schlusslicht_mi_def
      SP_IF_LH_S_Schlusslicht_re_def_XIX_SAM: provided-interface=IF_LH_S_Schlusslicht_re_def
      SP_IF_LH_S_SL_BRL_BLK_li_def_XIX_SAM: provided-interface=IF_LH_S_SL_BRL_BLK_li_def
      SP_IF_LH_S_SL_BRL_BLK_re_def_XIX_SAM: provided-interface=IF_LH_S_SL_BRL_BLK_re_def
      SP_IF_LIM_P_Mode_XIX_SAM: provided-interface=IF_LIM_P_Mode
      SP_IF_LIM_S_Rollo_vo_XIX_SAM: provided-interface=IF_LIM_S_Rollo_vo
      SP_IF_LR_HZG_01_alt_XIX_SAM: provided-interface=IF_LR_HZG_01_alt
      SP_IF_LR_HZG_Konfiguration_XIX_SAM: provided-interface=IF_LR_HZG_Konfiguration
      SP_IF_LR_HZG_Temp_Sensor_XIX_SAM: provided-interface=IF_LR_HZG_Temp_Sensor
      SP_IF_LRH_aktiv_XIX_SAM: provided-interface=IF_LRH_aktiv
      SP_IF_LRH_On_Off_XIX_SAM: provided-interface=IF_LRH_On_Off
      SP_IF_LS_defekt_XIX_SAM: provided-interface=IF_LS_defekt
      SP_IF_LS_Dunkel_XIX_SAM: provided-interface=IF_LS_Dunkel
      SP_IF_LS_Error_XIX_SAM: provided-interface=IF_LS_Error
      SP_IF_LS_Helligkeit_FW_XIX_SAM: provided-interface=IF_LS_Helligkeit_FW
      SP_IF_LS_Helligkeit_IR_XIX_SAM: provided-interface=IF_LS_Helligkeit_IR
      SP_IF_LS_Licht_ein_invers_XIX_SAM: provided-interface=IF_LS_Licht_ein_invers
      SP_IF_LS_Licht_ein_XIX_SAM: provided-interface=IF_LS_Licht_ein
      SP_IF_LS_TFL_mit_SL_ein_XIX_SAM: provided-interface=IF_LS_TFL_mit_SL_ein
      SP_IF_LS_Verbau_XIX_SAM: provided-interface=IF_LS_Verbau
      SP_IF_LSS_Tastencode_XIX_SAM: provided-interface=IF_LSS_Tastencode
      SP_IF_Master_Zaehler_XIX_SAM: provided-interface=IF_Master_Zaehler
      SP_IF_MO_Kl_75_XIX_SAM: provided-interface=IF_MO_Kl_75
      SP_IF_NM_BCM1_CAB_V15_XIX_SAM: provided-interface=IF_NM_BCM1_CAB_V15
      SP_IF_NM_BCM1_Car_Wakeup_XIX_SAM: provided-interface=IF_NM_BCM1_Car_Wakeup
      SP_IF_NM_BCM1_CBV_AWB_XIX_SAM: provided-interface=IF_NM_BCM1_CBV_AWB
      SP_IF_NM_BCM1_CBV_CRI_XIX_SAM: provided-interface=IF_NM_BCM1_CBV_CRI
      SP_IF_NM_BCM1_NM_State_XIX_SAM: provided-interface=IF_NM_BCM1_NM_State
      SP_IF_ORU_0009_BZ_XIX_SAM: provided-interface=IF_ORU_0009_BZ
      SP_IF_ORU_0009_CRC_XIX_SAM: provided-interface=IF_ORU_0009_CRC
      SP_IF_ORUG02_01_BZ_XIX_SAM: provided-interface=IF_ORUG02_01_BZ
      SP_IF_ORUG02_01_CRC_XIX_SAM: provided-interface=IF_ORUG02_01_CRC
      SP_IF_ORUG2_GuardInfo_XIX_SAM: provided-interface=IF_ORUG2_GuardInfo
      SP_IF_ORUG2_GuardState_XIX_SAM: provided-interface=IF_ORUG2_GuardState
      SP_IF_ORUG2_TargetRelease_XIX_SAM: provided-interface=IF_ORUG2_TargetRelease
      SP_IF_ORUG2_TorqueLock_XIX_SAM: provided-interface=IF_ORUG2_TorqueLock
      SP_IF_PAO_OFF_Anf_invers_XIX_SAM: provided-interface=IF_PAO_OFF_Anf_invers
      SP_IF_PAO_ON_Anf_invers_XIX_SAM: provided-interface=IF_PAO_ON_Anf_invers
      SP_IF_RLS_02_BZ_XIX_SAM: provided-interface=IF_RLS_02_BZ
      SP_IF_RLS_02_CRC_XIX_SAM: provided-interface=IF_RLS_02_CRC
      SP_IF_RLS_Qualifizierungsbit_XIX_SAM: provided-interface=IF_RLS_Qualifizierungsbit
      SP_IF_RLS_ResponseError_XIX_SAM: provided-interface=IF_RLS_ResponseError
      SP_IF_RLS_Vorfeldhelligkeit_Boost_XIX_SAM: provided-interface=IF_RLS_Vorfeldhelligkeit_Boost
      SP_IF_RS_AdaptierungError_XIX_SAM: provided-interface=IF_RS_AdaptierungError
      SP_IF_RS_defekt_XIX_SAM: provided-interface=IF_RS_defekt
      SP_IF_RS_Error_XIX_SAM: provided-interface=IF_RS_Error
      SP_IF_RS_Regenfahrlicht_XIX_SAM: provided-interface=IF_RS_Regenfahrlicht
      SP_IF_RS_Regenmenge_XIX_SAM: provided-interface=IF_RS_Regenmenge
      SP_IF_RS_Schwall_XIX_SAM: provided-interface=IF_RS_Schwall
      SP_IF_RS_Verbau_XIX_SAM: provided-interface=IF_RS_Verbau
      SP_IF_RS_Verglasung_schliessen_XIX_SAM: provided-interface=IF_RS_Verglasung_schliessen
      SP_IF_RS_versParklage_Wischer_XIX_SAM: provided-interface=IF_RS_versParklage_Wischer
      SP_IF_RS_Wischergeschwindigkeit_XIX_SAM: provided-interface=IF_RS_Wischergeschwindigkeit
      SP_IF_SAL_li1_Blinker_Status_XIX_SAM: provided-interface=IF_SAL_li1_Blinker_Status
      SP_IF_SAL_re1_Blinker_Status_XIX_SAM: provided-interface=IF_SAL_re1_Blinker_Status
      SP_IF_SAM_01_BZ_XIX_SAM: provided-interface=IF_SAM_01_BZ
      SP_IF_SAM_01_CRC_XIX_SAM: provided-interface=IF_SAM_01_CRC
      SP_IF_SAM_Fehler_DC_LWR_XIX_SAM: provided-interface=IF_SAM_Fehler_DC_LWR
      SP_IF_SAM_ORUData_XIX_SAM: provided-interface=IF_SAM_ORUData
      SP_IF_SAM_ORUDataIndex_XIX_SAM: provided-interface=IF_SAM_ORUDataIndex
      SP_IF_SC_PAO_OFF_Anf_XIX_SAM: provided-interface=IF_SC_PAO_OFF_Anf
      SP_IF_SC_PAO_ON_Anf_XIX_SAM: provided-interface=IF_SC_PAO_ON_Anf
      SP_IF_Schluesselnr_Personalisierung_XIX_SAM: provided-interface=IF_Schluesselnr_Personalisierung
      SP_IF_Servicestellung_Wischer_XIX_SAM: provided-interface=IF_Servicestellung_Wischer
      SP_IF_SIL_Stufe_LED_li_XIX_SAM: provided-interface=IF_SIL_Stufe_LED_li
      SP_IF_SIL_Stufe_LED_re_XIX_SAM: provided-interface=IF_SIL_Stufe_LED_re
      SP_IF_SMLS_01_BZ_XIX_SAM: provided-interface=IF_SMLS_01_BZ
      SP_IF_SMLS_01_CRC_XIX_SAM: provided-interface=IF_SMLS_01_CRC
      SP_IF_SMLS_alt_XIX_SAM: provided-interface=IF_SMLS_alt
      SP_IF_SMLS_Hupe_XIX_SAM: provided-interface=IF_SMLS_Hupe
      SP_IF_SOK_FoD_BCM1_Req_Challenge_XIX_SAM: provided-interface=IF_SOK_FoD_BCM1_Req_Challenge
      SP_IF_SOK_KST_Challenge_XIX_SAM: provided-interface=IF_SOK_KST_Challenge
      SP_IF_SOK_ZV_HBFS_Challenge_XIX_SAM: provided-interface=IF_SOK_ZV_HBFS_Challenge
      SP_IF_SOK_ZV_HFS_Challenge_XIX_SAM: provided-interface=IF_SOK_ZV_HFS_Challenge
      SP_IF_SOK_ZV_HW_Challenge_XIX_SAM: provided-interface=IF_SOK_ZV_HW_Challenge
      SP_IF_Soll_Lehne_LLR_li_1_XIX_SAM: provided-interface=IF_Soll_Lehne_LLR_li_1
      SP_IF_Soll_Lehne_LLR_li_2_XIX_SAM: provided-interface=IF_Soll_Lehne_LLR_li_2
      SP_IF_Soll_Lehne_LLR_re_1_XIX_SAM: provided-interface=IF_Soll_Lehne_LLR_re_1
      SP_IF_Soll_Lehne_LLR_re_2_XIX_SAM: provided-interface=IF_Soll_Lehne_LLR_re_2
      SP_IF_Soll_Sitz_LLR_li_1_XIX_SAM: provided-interface=IF_Soll_Sitz_LLR_li_1
      SP_IF_Soll_Sitz_LLR_li_2_XIX_SAM: provided-interface=IF_Soll_Sitz_LLR_li_2
      SP_IF_Soll_Sitz_LLR_re_1_XIX_SAM: provided-interface=IF_Soll_Sitz_LLR_re_1
      SP_IF_Soll_Sitz_LLR_re_2_XIX_SAM: provided-interface=IF_Soll_Sitz_LLR_re_2
      SP_IF_SPR_Abschaltstufe_XIX_SAM: provided-interface=IF_SPR_Abschaltstufe
      SP_IF_SRA_Sequenz_Status_XIX_SAM: provided-interface=IF_SRA_Sequenz_Status
      SP_IF_Stellgliedtest_LRH_XIX_SAM: provided-interface=IF_Stellgliedtest_LRH
      SP_IF_TSG_FHSG_MST_Jahr_k_XIX_SAM: provided-interface=IF_TSG_FHSG_MST_Jahr_k
      SP_IF_TSG_FHSG_MST_KM_Stand_1_XIX_SAM: provided-interface=IF_TSG_FHSG_MST_KM_Stand_1
      SP_IF_TSG_FHSG_MST_KM_Stand_2_XIX_SAM: provided-interface=IF_TSG_FHSG_MST_KM_Stand_2
      SP_IF_TSG_FHSG_MST_Minute_k_XIX_SAM: provided-interface=IF_TSG_FHSG_MST_Minute_k
      SP_IF_TSG_FHSG_MST_Monat_k_XIX_SAM: provided-interface=IF_TSG_FHSG_MST_Monat_k
      SP_IF_TSG_FHSG_MST_Sekunde_k_XIX_SAM: provided-interface=IF_TSG_FHSG_MST_Sekunde_k
      SP_IF_TSG_FHSG_MST_Stunde_k_XIX_SAM: provided-interface=IF_TSG_FHSG_MST_Stunde_k
      SP_IF_TSG_FHSG_MST_Tag_k_XIX_SAM: provided-interface=IF_TSG_FHSG_MST_Tag_k
      SP_IF_TSG_FHSG_MST_Time_Indication_Bit_XIX_SAM: provided-interface=IF_TSG_FHSG_MST_Time_Indication_Bit
      SP_IF_TSG_FHSG_MST_TSG_Seite_XIX_SAM: provided-interface=IF_TSG_FHSG_MST_TSG_Seite
      SP_IF_TSG_FHSG_MST_Verlernzaehler_k_XIX_SAM: provided-interface=IF_TSG_FHSG_MST_Verlernzaehler_k
      SP_IF_TSG_HBFS_02_BZ_XIX_SAM: provided-interface=IF_TSG_HBFS_02_BZ
      SP_IF_TSG_HBFS_02_CRC_XIX_SAM: provided-interface=IF_TSG_HBFS_02_CRC
      SP_IF_TSG_HFS_02_BZ_XIX_SAM: provided-interface=IF_TSG_HFS_02_BZ
      SP_IF_TSG_HFS_02_CRC_XIX_SAM: provided-interface=IF_TSG_HFS_02_CRC
      SP_IF_Tuerkontakt_Innenlicht_Status_XIX_SAM: provided-interface=IF_Tuerkontakt_Innenlicht_Status
      SP_IF_UGDO_Buttons_XIX_SAM: provided-interface=IF_UGDO_Buttons
      SP_IF_UGDO_Switchboard_XIX_SAM: provided-interface=IF_UGDO_Switchboard
      SP_IF_UHF_Sensor_01_Data_XIX_SAM: provided-interface=IF_UHF_Sensor_01_Data
      SP_IF_UHF_Sensor_01_Datenlaenge_XIX_SAM: provided-interface=IF_UHF_Sensor_01_Datenlaenge
      SP_IF_UHF_Sensor_01_Status_XIX_SAM: provided-interface=IF_UHF_Sensor_01_Status
      SP_IF_UHF_Sensor_01_Typ_XIX_SAM: provided-interface=IF_UHF_Sensor_01_Typ
      SP_IF_UHF_Sensor_01_Zaehler_XIX_SAM: provided-interface=IF_UHF_Sensor_01_Zaehler
      SP_IF_UHF_Sensor_02_Data_XIX_SAM: provided-interface=IF_UHF_Sensor_02_Data
      SP_IF_UHF_Sensor_02_Zaehler_XIX_SAM: provided-interface=IF_UHF_Sensor_02_Zaehler
      SP_IF_UHF_Sensor_03_Data_XIX_SAM: provided-interface=IF_UHF_Sensor_03_Data
      SP_IF_UHF_Sensor_03_Zaehler_XIX_SAM: provided-interface=IF_UHF_Sensor_03_Zaehler
      SP_IF_UHF_Sensor_04_Data_XIX_SAM: provided-interface=IF_UHF_Sensor_04_Data
      SP_IF_UHF_Sensor_04_Zaehler_XIX_SAM: provided-interface=IF_UHF_Sensor_04_Zaehler
      SP_IF_UHF_Sensor_05_Data_XIX_SAM: provided-interface=IF_UHF_Sensor_05_Data
      SP_IF_UHF_Sensor_05_Zaehler_XIX_SAM: provided-interface=IF_UHF_Sensor_05_Zaehler
      SP_IF_UHF_Sensor_06_Data_XIX_SAM: provided-interface=IF_UHF_Sensor_06_Data
      SP_IF_UHF_Sensor_06_Zaehler_XIX_SAM: provided-interface=IF_UHF_Sensor_06_Zaehler
      SP_IF_UHF_Sensor_07_Data_XIX_SAM: provided-interface=IF_UHF_Sensor_07_Data
      SP_IF_UHF_Sensor_07_Zaehler_XIX_SAM: provided-interface=IF_UHF_Sensor_07_Zaehler
      SP_IF_UHF_Sensor_08_Data_XIX_SAM: provided-interface=IF_UHF_Sensor_08_Data
      SP_IF_UHF_Sensor_08_Zaehler_XIX_SAM: provided-interface=IF_UHF_Sensor_08_Zaehler
      SP_IF_UHF_Sensor_RSSI_Wert_IDGeber{1..8}_XIX_SAM: provided-interface=IF_UHF_Sensor_RSSI_Wert_IDGeber{1..8}
      SP_IF_Verbauposition_LLR_li_XIX_SAM: provided-interface=IF_Verbauposition_LLR_li
      SP_IF_Verbauposition_LLR_re_XIX_SAM: provided-interface=IF_Verbauposition_LLR_re
      SP_IF_Verglasung_offen_XIX_SAM: provided-interface=IF_Verglasung_offen
      SP_IF_Waschen_vorne_aktiv_XIX_SAM: provided-interface=IF_Waschen_vorne_aktiv
      SP_IF_Wendelage_oben_Wischer_XIX_SAM: provided-interface=IF_Wendelage_oben_Wischer
      SP_IF_Wendelage_unten_Wischer_XIX_SAM: provided-interface=IF_Wendelage_unten_Wischer
      SP_IF_WH_Frontwaschen_XIX_SAM: provided-interface=IF_WH_Frontwaschen
      SP_IF_WH_Heckintervall_XIX_SAM: provided-interface=IF_WH_Heckintervall
      SP_IF_WH_Heckwaschen_XIX_SAM: provided-interface=IF_WH_Heckwaschen
      SP_IF_WH_Intervall_XIX_SAM: provided-interface=IF_WH_Intervall
      SP_IF_WH_Intervallstufen_XIX_SAM: provided-interface=IF_WH_Intervallstufen
      SP_IF_WH_Tippwischen_XIX_SAM: provided-interface=IF_WH_Tippwischen
      SP_IF_WH_Tipwischen_XIX_SAM: provided-interface=IF_WH_Tipwischen
      SP_IF_WH_Wischer_Fehler_XIX_SAM: provided-interface=IF_WH_Wischer_Fehler
      SP_IF_WH_WischerStufe1_XIX_SAM: provided-interface=IF_WH_WischerStufe1
      SP_IF_WH_WischerStufe2_XIX_SAM: provided-interface=IF_WH_WischerStufe2
      SP_IF_Wischer1_Wischgeschwindigkeit_XIX_SAM: provided-interface=IF_Wischer1_Wischgeschwindigkeit
      SP_IF_Wischer_vorne_aktiv_XIX_SAM: provided-interface=IF_Wischer_vorne_aktiv
      SP_IF_Wischer_vorne_blockiert_XIX_SAM: provided-interface=IF_Wischer_vorne_blockiert
      SP_IF_Wischer_vorne_defekt_XIX_SAM: provided-interface=IF_Wischer_vorne_defekt
      SP_IF_Wischer_vorne_Normal_XIX_SAM: provided-interface=IF_Wischer_vorne_Normal
      SP_IF_Wischer_vorne_Parklage_XIX_SAM: provided-interface=IF_Wischer_vorne_Parklage
      SP_IF_Wischer_vorne_Schnell_XIX_SAM: provided-interface=IF_Wischer_vorne_Schnell
      SP_IF_Wischer_WH_PopUp_Anf_XIX_SAM: provided-interface=IF_Wischer_WH_PopUp_Anf
      SP_IF_Wischer_WH_Typ_XIX_SAM: provided-interface=IF_Wischer_WH_Typ
      SP_IF_WWS_Produktionsmodus_XIX_SAM: provided-interface=IF_WWS_Produktionsmodus
      SP_IF_WWSs_01_alt_XIX_SAM: provided-interface=IF_WWSs_01_alt
      SP_IF_ZAS_Kl_15_XIX_SAM: provided-interface=IF_ZAS_Kl_15
      SP_IF_ZAS_Kl_S_XIX_SAM: provided-interface=IF_ZAS_Kl_S
      SP_IF_ZV_Ladeklappe_VerEntriegeln_XIX_SAM: provided-interface=IF_ZV_Ladeklappe_VerEntriegeln
      SP_IF_ZV_LadeklappenStatus_XIX_SAM: provided-interface=IF_ZV_LadeklappenStatus
    1118 x require port:
      RP_IF_AAG_Anhaenger_erkannt_XIX_SAM: required-interface=IF_AAG_Anhaenger_erkannt
      RP_IF_AAG_ORUData_XIX_SAM: required-interface=IF_AAG_ORUData
      RP_IF_AAG_ORUDataIndex_XIX_SAM: required-interface=IF_AAG_ORUDataIndex
      RP_IF_AB_Belegung_VB_XIX_SAM: required-interface=IF_AB_Belegung_VB
      RP_IF_AB_Crash_Int_XIX_SAM: required-interface=IF_AB_Crash_Int
      RP_IF_AB_Deaktivierung_HV_XIX_SAM: required-interface=IF_AB_Deaktivierung_HV
      RP_IF_AB_Front_Crash_XIX_SAM: required-interface=IF_AB_Front_Crash
      RP_IF_AB_Gurtschloss_BF_XIX_SAM: required-interface=IF_AB_Gurtschloss_BF
      RP_IF_AB_Gurtschloss_FA_XIX_SAM: required-interface=IF_AB_Gurtschloss_FA
      RP_IF_AB_Heck_Crash_XIX_SAM: required-interface=IF_AB_Heck_Crash
      RP_IF_AB_Rollover_Crash_XIX_SAM: required-interface=IF_AB_Rollover_Crash
      RP_IF_AB_SB_Crash_XIX_SAM: required-interface=IF_AB_SB_Crash
      RP_IF_AB_SF_Crash_XIX_SAM: required-interface=IF_AB_SF_Crash
      RP_IF_ADecu1_01_BZ_XIX_SAM: required-interface=IF_ADecu1_01_BZ
      RP_IF_ADecu1_01_CRC_XIX_SAM: required-interface=IF_ADecu1_01_CRC
      RP_IF_ADecu1_ORUData_XIX_SAM: required-interface=IF_ADecu1_ORUData
      RP_IF_ADecu1_ORUDataIndex_XIX_SAM: required-interface=IF_ADecu1_ORUDataIndex
      RP_IF_ADecu2_01_BZ_XIX_SAM: required-interface=IF_ADecu2_01_BZ
      RP_IF_ADecu2_01_CRC_XIX_SAM: required-interface=IF_ADecu2_01_CRC
      RP_IF_ADecu2_ORUData_XIX_SAM: required-interface=IF_ADecu2_ORUData
      RP_IF_ADecu2_ORUDataIndex_XIX_SAM: required-interface=IF_ADecu2_ORUDataIndex
      RP_IF_Airbag_01_BZ_XIX_SAM: required-interface=IF_Airbag_01_BZ
      RP_IF_Airbag_01_CRC_XIX_SAM: required-interface=IF_Airbag_01_CRC
      RP_IF_Airbag_02_BZ_XIX_SAM: required-interface=IF_Airbag_02_BZ
      RP_IF_Airbag_02_CRC_XIX_SAM: required-interface=IF_Airbag_02_CRC
      RP_IF_Airbag_ORUData_XIX_SAM: required-interface=IF_Airbag_ORUData
      RP_IF_Airbag_ORUDataIndex_XIX_SAM: required-interface=IF_Airbag_ORUDataIndex
      RP_IF_ASW_Warnung_aktiv_BFS_XIX_SAM: required-interface=IF_ASW_Warnung_aktiv_BFS
      RP_IF_ASW_Warnung_aktiv_FS_XIX_SAM: required-interface=IF_ASW_Warnung_aktiv_FS
      RP_IF_ASW_Warnung_aktiv_HBFS_XIX_SAM: required-interface=IF_ASW_Warnung_aktiv_HBFS
      RP_IF_ASW_Warnung_aktiv_HFS_XIX_SAM: required-interface=IF_ASW_Warnung_aktiv_HFS
      RP_IF_BAPs_Data_Byte_{1..6}_XIX_SAM: required-interface=IF_BAPs_Data_Byte_{1..6}
      RP_IF_BAPs_FCT_ID_XIX_SAM: required-interface=IF_BAPs_FCT_ID
      RP_IF_BAPs_LSG_ID1_XIX_SAM: required-interface=IF_BAPs_LSG_ID1
      RP_IF_BAPs_LSG_ID2_XIX_SAM: required-interface=IF_BAPs_LSG_ID2
      RP_IF_BAPs_Opcode_XIX_SAM: required-interface=IF_BAPs_Opcode
      RP_IF_BAPs_Segment_XIX_SAM: required-interface=IF_BAPs_Segment
      RP_IF_BCM1_CH_LH_aktiv_XIX_SAM: required-interface=IF_BCM1_CH_LH_aktiv
      RP_IF_BCM1_Nebelschluss_Fzg_Anf_XIX_SAM: required-interface=IF_BCM1_Nebelschluss_Fzg_Anf
      RP_IF_BCM1_Parklicht_li_Anf_XIX_SAM: required-interface=IF_BCM1_Parklicht_li_Anf
      RP_IF_BCM1_Parklicht_re_Anf_XIX_SAM: required-interface=IF_BCM1_Parklicht_re_Anf
      RP_IF_BCM1_Schlusslicht_Anf_XIX_SAM: required-interface=IF_BCM1_Schlusslicht_Anf
      RP_IF_BCM1_Standlicht_Anf_XIX_SAM: required-interface=IF_BCM1_Standlicht_Anf
      RP_IF_BCM1_Umfeldleuchten_Anf_XIX_SAM: required-interface=IF_BCM1_Umfeldleuchten_Anf
      RP_IF_BCM_FH_Freigabe_XIX_SAM: required-interface=IF_BCM_FH_Freigabe
      RP_IF_BCM_Komfortfkt_Freigabe_XIX_SAM: required-interface=IF_BCM_Komfortfkt_Freigabe
      RP_IF_BCM_Rueckfahrlicht_Anf_XIX_SAM: required-interface=IF_BCM_Rueckfahrlicht_Anf
      RP_IF_Bel_DiETa_Mode_XIX_SAM: required-interface=IF_Bel_DiETa_Mode
      RP_IF_Bel_DiETa_Warnblinken_XIX_SAM: required-interface=IF_Bel_DiETa_Warnblinken
      RP_IF_BFS_MMB_glob_stop_XIX_SAM: required-interface=IF_BFS_MMB_glob_stop
      RP_IF_BFS_MMB_storage_XIX_SAM: required-interface=IF_BFS_MMB_storage
      RP_IF_BFS_MMB_tast_XIX_SAM: required-interface=IF_BFS_MMB_tast
      RP_IF_BFS_MMB_tipp_XIX_SAM: required-interface=IF_BFS_MMB_tipp
      RP_IF_BH_Blinker_Fehler_XIX_SAM: required-interface=IF_BH_Blinker_Fehler
      RP_IF_BH_Blinker_li_invers_XIX_SAM: required-interface=IF_BH_Blinker_li_invers
      RP_IF_BH_Blinker_li_XIX_SAM: required-interface=IF_BH_Blinker_li
      RP_IF_BH_Blinker_re_invers_XIX_SAM: required-interface=IF_BH_Blinker_re_invers
      RP_IF_BH_Blinker_re_XIX_SAM: required-interface=IF_BH_Blinker_re
      RP_IF_BH_Fernlicht_XIX_SAM: required-interface=IF_BH_Fernlicht
      RP_IF_BH_Lichthupe_XIX_SAM: required-interface=IF_BH_Lichthupe
      RP_IF_BM_Warnblinken_XIX_SAM: required-interface=IF_BM_Warnblinken
      RP_IF_BM_WBT_Beleuchtung_XIX_SAM: required-interface=IF_BM_WBT_Beleuchtung
      RP_IF_BM_ZV_auf_XIX_SAM: required-interface=IF_BM_ZV_auf
      RP_IF_BM_ZV_zu_XIX_SAM: required-interface=IF_BM_ZV_zu
      RP_IF_BMCe_ORUData_XIX_SAM: required-interface=IF_BMCe_ORUData
      RP_IF_BMCe_ORUDataIndex_XIX_SAM: required-interface=IF_BMCe_ORUDataIndex
      RP_IF_BMS_KundenWarnung_XIX_SAM: required-interface=IF_BMS_KundenWarnung
      RP_IF_BT_FH_Bew_hoch_XIX_SAM: required-interface=IF_BT_FH_Bew_hoch
      RP_IF_BT_FH_Bew_tief_XIX_SAM: required-interface=IF_BT_FH_Bew_tief
      RP_IF_BT_Oben_Block_erw_XIX_SAM: required-interface=IF_BT_Oben_Block_erw
      RP_IF_BT_Sp_Blk_def_XIX_SAM: required-interface=IF_BT_Sp_Blk_def
      RP_IF_BT_Tuer_geoeffnet_XIX_SAM: required-interface=IF_BT_Tuer_geoeffnet
      RP_IF_BT_Unten_Block_erw_XIX_SAM: required-interface=IF_BT_Unten_Block_erw
      RP_IF_CHA_Fahrer_Umschaltung_XIX_SAM: required-interface=IF_CHA_Fahrer_Umschaltung
      RP_IF_CHA_Ziel_FahrPr_AMB_XIX_SAM: required-interface=IF_CHA_Ziel_FahrPr_AMB
      RP_IF_CPDFct_FlashAndHonk_XIX_SAM: required-interface=IF_CPDFct_FlashAndHonk
      RP_IF_DCDC_HR_ORUData_XIX_SAM: required-interface=IF_DCDC_HR_ORUData
      RP_IF_DCDC_HR_ORUDataIndex_XIX_SAM: required-interface=IF_DCDC_HR_ORUDataIndex
      RP_IF_DCDC_NV_ORUDataIndex_XIX_SAM: required-interface=IF_DCDC_NV_ORUDataIndex
      RP_IF_DCDC_ORUData_XIX_SAM: required-interface=IF_DCDC_ORUData
      RP_IF_DGN_Verlernzaehler_XIX_SAM: required-interface=IF_DGN_Verlernzaehler
      RP_IF_DI_KL_58xd_XIX_SAM: required-interface=IF_DI_KL_58xd
      RP_IF_DI_KL_58xs_XIX_SAM: required-interface=IF_DI_KL_58xs
      RP_IF_DI_KL_58xt_XIX_SAM: required-interface=IF_DI_KL_58xt
      RP_IF_DiETa_Car_XIX_SAM: required-interface=IF_DiETa_Car
      RP_IF_DiETa_Defrost_Taste_XIX_SAM: required-interface=IF_DiETa_Defrost_Taste
      RP_IF_DiETa_FAS_Stufe_XIX_SAM: required-interface=IF_DiETa_FAS_Stufe
      RP_IF_DiETa_FSH_Taste_XIX_SAM: required-interface=IF_DiETa_FSH_Taste
      RP_IF_DiETa_HSH_Taste_XIX_SAM: required-interface=IF_DiETa_HSH_Taste
      RP_IF_DiETa_Klima_XIX_SAM: required-interface=IF_DiETa_Klima
      RP_IF_DiETa_Lock_Unlock_Taste_XIX_SAM: required-interface=IF_DiETa_Lock_Unlock_Taste
      RP_IF_DiETa_Mode_XIX_SAM: required-interface=IF_DiETa_Mode
      RP_IF_DiETa_Parken_XIX_SAM: required-interface=IF_DiETa_Parken
      RP_IF_DiETa_ResponseError_XIX_SAM: required-interface=IF_DiETa_ResponseError
      RP_IF_DiETa_Status_XIX_SAM: required-interface=IF_DiETa_Status
      RP_IF_DiETa_Warnblink_Taste_XIX_SAM: required-interface=IF_DiETa_Warnblink_Taste
      RP_IF_DLI_Ambex_RefStatus_XIX_SAM: required-interface=IF_DLI_Ambex_RefStatus
      RP_IF_DRB1_01_BZ_XIX_SAM: required-interface=IF_DRB1_01_BZ
      RP_IF_DRB1_01_CRC_XIX_SAM: required-interface=IF_DRB1_01_CRC
      RP_IF_DRB1_ORUData_XIX_SAM: required-interface=IF_DRB1_ORUData
      RP_IF_DRB1_ORUDataIndex_XIX_SAM: required-interface=IF_DRB1_ORUDataIndex
      RP_IF_DRB2_01_BZ_XIX_SAM: required-interface=IF_DRB2_01_BZ
      RP_IF_DRB2_01_CRC_XIX_SAM: required-interface=IF_DRB2_01_CRC
      RP_IF_DRB2_ORUData_XIX_SAM: required-interface=IF_DRB2_ORUData
      RP_IF_DRB2_ORUDataIndex_XIX_SAM: required-interface=IF_DRB2_ORUDataIndex
      RP_IF_EA_Fahrzeughupe_Anf_XIX_SAM: required-interface=IF_EA_Fahrzeughupe_Anf
      RP_IF_EA_Innenraumlicht_Anf_XIX_SAM: required-interface=IF_EA_Innenraumlicht_Anf
      RP_IF_EBKV_2Box_ORUDataIndex_XIX_SAM: required-interface=IF_EBKV_2Box_ORUDataIndex
      RP_IF_EBKV_ORUData_XIX_SAM: required-interface=IF_EBKV_ORUData
      RP_IF_eFuse1_ORUData_XIX_SAM: required-interface=IF_eFuse1_ORUData
      RP_IF_eFuse1_ORUDataIndex_XIX_SAM: required-interface=IF_eFuse1_ORUDataIndex
      RP_IF_eFuse3_ORUData_XIX_SAM: required-interface=IF_eFuse3_ORUData
      RP_IF_eFuse3_ORUDataIndex_XIX_SAM: required-interface=IF_eFuse3_ORUDataIndex
      RP_IF_EM1_HYB_13_BZ_XIX_SAM: required-interface=IF_EM1_HYB_13_BZ
      RP_IF_EM1_HYB_13_CRC_XIX_SAM: required-interface=IF_EM1_HYB_13_CRC
      RP_IF_EM2_HYB_13_BZ_XIX_SAM: required-interface=IF_EM2_HYB_13_BZ
      RP_IF_EM2_HYB_13_CRC_XIX_SAM: required-interface=IF_EM2_HYB_13_CRC
      RP_IF_EPB_Status_02_XIX_SAM: required-interface=IF_EPB_Status_02
      RP_IF_EPH_ORUData_XIX_SAM: required-interface=IF_EPH_ORUData
      RP_IF_EPH_ORUDataIndex_XIX_SAM: required-interface=IF_EPH_ORUDataIndex
      RP_IF_eRWK_AD_oeffnen_Anf_XIX_SAM: required-interface=IF_eRWK_AD_oeffnen_Anf
      RP_IF_eRWK_AD_schliessen_Anf_XIX_SAM: required-interface=IF_eRWK_AD_schliessen_Anf
      RP_IF_ESC_Bremsfluessigkeits_Sensor_XIX_SAM: required-interface=IF_ESC_Bremsfluessigkeits_Sensor
      RP_IF_ESC_ORUData_XIX_SAM: required-interface=IF_ESC_ORUData
      RP_IF_ESC_ORUDataIndex_XIX_SAM: required-interface=IF_ESC_ORUDataIndex
      RP_IF_ESC_v_Signal_Qualifier_High_Low_XIX_SAM: required-interface=IF_ESC_v_Signal_Qualifier_High_Low
      RP_IF_ESP_21_BZ_XIX_SAM: required-interface=IF_ESP_21_BZ
      RP_IF_ESP_21_CRC_XIX_SAM: required-interface=IF_ESP_21_CRC
      RP_IF_ESP_Laengsbeschl_XIX_SAM: required-interface=IF_ESP_Laengsbeschl
      RP_IF_ESP_m_Raddrehz_XIX_SAM: required-interface=IF_ESP_m_Raddrehz
      RP_IF_ESP_QBit_v_Signal_XIX_SAM: required-interface=IF_ESP_QBit_v_Signal
      RP_IF_ESP_Querbeschleunigung_XIX_SAM: required-interface=IF_ESP_Querbeschleunigung
      RP_IF_ESP_Status_Bremsentemp_02_XIX_SAM: required-interface=IF_ESP_Status_Bremsentemp_02
      RP_IF_ESP_v_Signal_XIX_SAM: required-interface=IF_ESP_v_Signal
      RP_IF_Fahrerdisplay_Kombi_ORUData_XIX_SAM: required-interface=IF_Fahrerdisplay_Kombi_ORUData
      RP_IF_Fahrerdisplay_Kombi_ORUDataIndex_XIX_SAM: required-interface=IF_Fahrerdisplay_Kombi_ORUDataIndex
      RP_IF_FAS_Taster_Fehler_XIX_SAM: required-interface=IF_FAS_Taster_Fehler
      RP_IF_FAS_Taster_XIX_SAM: required-interface=IF_FAS_Taster
      RP_IF_FASFrontradar_ORUData_XIX_SAM: required-interface=IF_FASFrontradar_ORUData
      RP_IF_FASFrontradar_ORUDataIndex_XIX_SAM: required-interface=IF_FASFrontradar_ORUDataIndex
      RP_IF_FFB_HDF_Taste_XIX_SAM: required-interface=IF_FFB_HDF_Taste
      RP_IF_FH_HBFS_hoch_XIX_SAM: required-interface=IF_FH_HBFS_hoch
      RP_IF_FH_HBFS_tief_XIX_SAM: required-interface=IF_FH_HBFS_tief
      RP_IF_FH_HFS_hoch_XIX_SAM: required-interface=IF_FH_HFS_hoch
      RP_IF_FH_HFS_tief_XIX_SAM: required-interface=IF_FH_HFS_tief
      RP_IF_FoD_Transmission_Info_XIX_SAM: required-interface=IF_FoD_Transmission_Info
      RP_IF_FS_Luftfeuchte_rel_XIX_SAM: required-interface=IF_FS_Luftfeuchte_rel
      RP_IF_FS_MMB_glob_stop_XIX_SAM: required-interface=IF_FS_MMB_glob_stop
      RP_IF_FS_MMB_storage_XIX_SAM: required-interface=IF_FS_MMB_storage
      RP_IF_FS_MMB_tast_XIX_SAM: required-interface=IF_FS_MMB_tast
      RP_IF_FS_MMB_tipp_XIX_SAM: required-interface=IF_FS_MMB_tipp
      RP_IF_FS_ResponseError_XIX_SAM: required-interface=IF_FS_ResponseError
      RP_IF_FS_Taupunkt_XIX_SAM: required-interface=IF_FS_Taupunkt
      RP_IF_FS_Temp_Scheibe_XIX_SAM: required-interface=IF_FS_Temp_Scheibe
      RP_IF_FS_Temp_Sensor_XIX_SAM: required-interface=IF_FS_Temp_Sensor
      RP_IF_FT_FH_Bew_hoch_XIX_SAM: required-interface=IF_FT_FH_Bew_hoch
      RP_IF_FT_FH_Bew_tief_XIX_SAM: required-interface=IF_FT_FH_Bew_tief
      RP_IF_FT_Kisi_li_aktiv_XIX_SAM: required-interface=IF_FT_Kisi_li_aktiv
      RP_IF_FT_Kisi_re_aktiv_XIX_SAM: required-interface=IF_FT_Kisi_re_aktiv
      RP_IF_FT_Kisi_Taster_li_02_XIX_SAM: required-interface=IF_FT_Kisi_Taster_li_02
      RP_IF_FT_Kisi_Taster_li_XIX_SAM: required-interface=IF_FT_Kisi_Taster_li
      RP_IF_FT_Kisi_Taster_re_02_XIX_SAM: required-interface=IF_FT_Kisi_Taster_re_02
      RP_IF_FT_Kisi_Taster_re_XIX_SAM: required-interface=IF_FT_Kisi_Taster_re
      RP_IF_FT_Oben_Block_erw_XIX_SAM: required-interface=IF_FT_Oben_Block_erw
      RP_IF_FT_Sp_Blk_def_XIX_SAM: required-interface=IF_FT_Sp_Blk_def
      RP_IF_FT_Tuer_geoeffnet_XIX_SAM: required-interface=IF_FT_Tuer_geoeffnet
      RP_IF_FT_Unten_Block_erw_XIX_SAM: required-interface=IF_FT_Unten_Block_erw
      RP_IF_GE_Fahrstufe_XIX_SAM: required-interface=IF_GE_Fahrstufe
      RP_IF_HBFS_Fehler_Beleuchtung_XIX_SAM: required-interface=IF_HBFS_Fehler_Beleuchtung
      RP_IF_HBFS_Fehler_FH_Normierung_XIX_SAM: required-interface=IF_HBFS_Fehler_FH_Normierung
      RP_IF_HBFS_Fehler_FH_Schalter_XIX_SAM: required-interface=IF_HBFS_Fehler_FH_Schalter
      RP_IF_HBFS_Fehler_Hallsensor_XIX_SAM: required-interface=IF_HBFS_Fehler_Hallsensor
      RP_IF_HBFS_Fehler_Kodierdaten_XIX_SAM: required-interface=IF_HBFS_Fehler_Kodierdaten
      RP_IF_HBFS_Fehler_Parameter_XIX_SAM: required-interface=IF_HBFS_Fehler_Parameter
      RP_IF_HBFS_Fehler_SG_XIX_SAM: required-interface=IF_HBFS_Fehler_SG
      RP_IF_HBFS_FH_Bew_hoch_XIX_SAM: required-interface=IF_HBFS_FH_Bew_hoch
      RP_IF_HBFS_FH_Bew_tief_XIX_SAM: required-interface=IF_HBFS_FH_Bew_tief
      RP_IF_HBFS_FH_Block_XIX_SAM: required-interface=IF_HBFS_FH_Block
      RP_IF_HBFS_FH_Fang_XIX_SAM: required-interface=IF_HBFS_FH_Fang
      RP_IF_HBFS_FH_normiert_XIX_SAM: required-interface=IF_HBFS_FH_normiert
      RP_IF_HBFS_FH_Oeffnung_XIX_SAM: required-interface=IF_HBFS_FH_Oeffnung
      RP_IF_HBFS_FH_S_AutoHoch_XIX_SAM: required-interface=IF_HBFS_FH_S_AutoHoch
      RP_IF_HBFS_FH_S_AutoTief_XIX_SAM: required-interface=IF_HBFS_FH_S_AutoTief
      RP_IF_HBFS_FH_S_ManHoch_XIX_SAM: required-interface=IF_HBFS_FH_S_ManHoch
      RP_IF_HBFS_FH_S_ManTief_XIX_SAM: required-interface=IF_HBFS_FH_S_ManTief
      RP_IF_HBFS_FH_Thermo_XIX_SAM: required-interface=IF_HBFS_FH_Thermo
      RP_IF_HBFS_FH_Ueberspannung_XIX_SAM: required-interface=IF_HBFS_FH_Ueberspannung
      RP_IF_HBFS_FH_Unterspannung_XIX_SAM: required-interface=IF_HBFS_FH_Unterspannung
      RP_IF_HBFS_Oben_Block_erw_XIX_SAM: required-interface=IF_HBFS_Oben_Block_erw
      RP_IF_HBFS_RelaisFehler_XIX_SAM: required-interface=IF_HBFS_RelaisFehler
      RP_IF_HBFS_ResponseError_XIX_SAM: required-interface=IF_HBFS_ResponseError
      RP_IF_HBFS_SleepIndication_XIX_SAM: required-interface=IF_HBFS_SleepIndication
      RP_IF_HBFS_Status_KiSi_XIX_SAM: required-interface=IF_HBFS_Status_KiSi
      RP_IF_HBFS_Status_Routine_XIX_SAM: required-interface=IF_HBFS_Status_Routine
      RP_IF_HBFS_Status_Stellgliedtest_XIX_SAM: required-interface=IF_HBFS_Status_Stellgliedtest
      RP_IF_HBFS_TIG_betaetigt_XIX_SAM: required-interface=IF_HBFS_TIG_betaetigt
      RP_IF_HBFS_Tuer_geoeffnet_XIX_SAM: required-interface=IF_HBFS_Tuer_geoeffnet
      RP_IF_HBFS_UEKB_aktiviert_XIX_SAM: required-interface=IF_HBFS_UEKB_aktiviert
      RP_IF_HBFS_Unten_Block_erw_XIX_SAM: required-interface=IF_HBFS_Unten_Block_erw
      RP_IF_HFS_Fehler_Beleuchtung_XIX_SAM: required-interface=IF_HFS_Fehler_Beleuchtung
      RP_IF_HFS_Fehler_FH_Normierung_XIX_SAM: required-interface=IF_HFS_Fehler_FH_Normierung
      RP_IF_HFS_Fehler_FH_Schalter_XIX_SAM: required-interface=IF_HFS_Fehler_FH_Schalter
      RP_IF_HFS_Fehler_Hallsensor_XIX_SAM: required-interface=IF_HFS_Fehler_Hallsensor
      RP_IF_HFS_Fehler_Kodierdaten_XIX_SAM: required-interface=IF_HFS_Fehler_Kodierdaten
      RP_IF_HFS_Fehler_Parameter_XIX_SAM: required-interface=IF_HFS_Fehler_Parameter
      RP_IF_HFS_Fehler_SG_XIX_SAM: required-interface=IF_HFS_Fehler_SG
      RP_IF_HFS_FH_Bew_hoch_XIX_SAM: required-interface=IF_HFS_FH_Bew_hoch
      RP_IF_HFS_FH_Bew_tief_XIX_SAM: required-interface=IF_HFS_FH_Bew_tief
      RP_IF_HFS_FH_Block_XIX_SAM: required-interface=IF_HFS_FH_Block
      RP_IF_HFS_FH_Fang_XIX_SAM: required-interface=IF_HFS_FH_Fang
      RP_IF_HFS_FH_normiert_XIX_SAM: required-interface=IF_HFS_FH_normiert
      RP_IF_HFS_FH_Oeffnung_XIX_SAM: required-interface=IF_HFS_FH_Oeffnung
      RP_IF_HFS_FH_S_AutoHoch_XIX_SAM: required-interface=IF_HFS_FH_S_AutoHoch
      RP_IF_HFS_FH_S_AutoTief_XIX_SAM: required-interface=IF_HFS_FH_S_AutoTief
      RP_IF_HFS_FH_S_ManHoch_XIX_SAM: required-interface=IF_HFS_FH_S_ManHoch
      RP_IF_HFS_FH_S_ManTief_XIX_SAM: required-interface=IF_HFS_FH_S_ManTief
      RP_IF_HFS_FH_Thermo_XIX_SAM: required-interface=IF_HFS_FH_Thermo
      RP_IF_HFS_FH_Ueberspannung_XIX_SAM: required-interface=IF_HFS_FH_Ueberspannung
      RP_IF_HFS_FH_Unterspannung_XIX_SAM: required-interface=IF_HFS_FH_Unterspannung
      RP_IF_HFS_Oben_Block_erw_XIX_SAM: required-interface=IF_HFS_Oben_Block_erw
      RP_IF_HFS_RelaisFehler_XIX_SAM: required-interface=IF_HFS_RelaisFehler
      RP_IF_HFS_ResponseError_XIX_SAM: required-interface=IF_HFS_ResponseError
      RP_IF_HFS_SleepIndication_XIX_SAM: required-interface=IF_HFS_SleepIndication
      RP_IF_HFS_Status_KiSi_XIX_SAM: required-interface=IF_HFS_Status_KiSi
      RP_IF_HFS_Status_Routine_XIX_SAM: required-interface=IF_HFS_Status_Routine
      RP_IF_HFS_Status_Stellgliedtest_XIX_SAM: required-interface=IF_HFS_Status_Stellgliedtest
      RP_IF_HFS_TIG_betaetigt_XIX_SAM: required-interface=IF_HFS_TIG_betaetigt
      RP_IF_HFS_Tuer_geoeffnet_XIX_SAM: required-interface=IF_HFS_Tuer_geoeffnet
      RP_IF_HFS_UEKB_aktiviert_XIX_SAM: required-interface=IF_HFS_UEKB_aktiviert
      RP_IF_HFS_Unten_Block_erw_XIX_SAM: required-interface=IF_HFS_Unten_Block_erw
      RP_IF_HLR_LRH_Freigabe_XIX_SAM: required-interface=IF_HLR_LRH_Freigabe
      RP_IF_HMS_aktives_System_XIX_SAM: required-interface=IF_HMS_aktives_System
      RP_IF_HMS_Fehlerstatus_XIX_SAM: required-interface=IF_HMS_Fehlerstatus
      RP_IF_HMS_parken_nicht_verfuegbar_XIX_SAM: required-interface=IF_HMS_parken_nicht_verfuegbar
      RP_IF_HMS_Stillstand_XIX_SAM: required-interface=IF_HMS_Stillstand
      RP_IF_HMS_Systemstatus_XIX_SAM: required-interface=IF_HMS_Systemstatus
      RP_IF_HSH_Relais_Anf_XIX_SAM: required-interface=IF_HSH_Relais_Anf
      RP_IF_HUD_ORUData_XIX_SAM: required-interface=IF_HUD_ORUData
      RP_IF_HUD_ORUDataIndex_XIX_SAM: required-interface=IF_HUD_ORUDataIndex
      RP_IF_HVL_01_BZ_XIX_SAM: required-interface=IF_HVL_01_BZ
      RP_IF_HVL_01_CRC_XIX_SAM: required-interface=IF_HVL_01_CRC
      RP_IF_HVL_Steckerstatus_XIX_SAM: required-interface=IF_HVL_Steckerstatus
      RP_IF_HVLS_Steckerstatus_SG1_XIX_SAM: required-interface=IF_HVLS_Steckerstatus_SG1
      RP_IF_HVLS_Steckerstatus_SG2_XIX_SAM: required-interface=IF_HVLS_Steckerstatus_SG2
      RP_IF_ICAS1_X_ORUData_XIX_SAM: required-interface=IF_ICAS1_X_ORUData
      RP_IF_ICAS1_X_ORUDataIndex_XIX_SAM: required-interface=IF_ICAS1_X_ORUDataIndex
      RP_IF_ICC_eKiSi_Unterdrueck_XIX_SAM: required-interface=IF_ICC_eKiSi_Unterdrueck
      RP_IF_ICC_Fernbed_ein_XIX_SAM: required-interface=IF_ICC_Fernbed_ein
      RP_IF_ICC_Innenraumbel_Unterdrueck_XIX_SAM: required-interface=IF_ICC_Innenraumbel_Unterdrueck
      RP_IF_KBI_Aussen_Temp_gef_XIX_SAM: required-interface=IF_KBI_Aussen_Temp_gef
      RP_IF_KBI_Kilometerstand_XIX_SAM: required-interface=IF_KBI_Kilometerstand
      RP_IF_KFG_ORUData_XIX_SAM: required-interface=IF_KFG_ORUData
      RP_IF_KFG_ORUDataIndex_XIX_SAM: required-interface=IF_KFG_ORUDataIndex
      RP_IF_KL_AL_HL_Anf_XIX_SAM: required-interface=IF_KL_AL_HL_Anf
      RP_IF_KL_AL_HR_Anf_XIX_SAM: required-interface=IF_KL_AL_HR_Anf
      RP_IF_KL_AL_VL_Anf_XIX_SAM: required-interface=IF_KL_AL_VL_Anf
      RP_IF_KL_AL_VR_Anf_XIX_SAM: required-interface=IF_KL_AL_VR_Anf
      RP_IF_KL_Defrost_LED_XIX_SAM: required-interface=IF_KL_Defrost_LED
      RP_IF_KL_FSH_LED_XIX_SAM: required-interface=IF_KL_FSH_LED
      RP_IF_KL_HSH_LED_XIX_SAM: required-interface=IF_KL_HSH_LED
      RP_IF_KL_LRH_Stufe_XIX_SAM: required-interface=IF_KL_LRH_Stufe
      RP_IF_KL_LRH_Taster_XIX_SAM: required-interface=IF_KL_LRH_Taster
      RP_IF_KL_SIL_Soll_li_XIX_SAM: required-interface=IF_KL_SIL_Soll_li
      RP_IF_KL_SIL_Soll_re_XIX_SAM: required-interface=IF_KL_SIL_Soll_re
      RP_IF_Klemmen_Status_01_BZ_XIX_SAM: required-interface=IF_Klemmen_Status_01_BZ
      RP_IF_Klemmen_Status_01_CRC_XIX_SAM: required-interface=IF_Klemmen_Status_01_CRC
      RP_IF_Klemmen_Steuerung_01_BZ_XIX_SAM: required-interface=IF_Klemmen_Steuerung_01_BZ
      RP_IF_Klemmen_Steuerung_01_CRC_XIX_SAM: required-interface=IF_Klemmen_Steuerung_01_CRC
      RP_IF_KST_Anf_Klemme_15_Auth_XIX_SAM: required-interface=IF_KST_Anf_Klemme_15_Auth
      RP_IF_KST_Anf_Klemme_S_XIX_SAM: required-interface=IF_KST_Anf_Klemme_S
      RP_IF_KST_KL15LockStatus_XIX_SAM: required-interface=IF_KST_KL15LockStatus
      RP_IF_KST_Sonderzustand_Anforderung_XIX_SAM: required-interface=IF_KST_Sonderzustand_Anforderung
      RP_IF_KST_Sonderzustand_Status_XIX_SAM: required-interface=IF_KST_Sonderzustand_Status
      RP_IF_KY_Ambex_Entfernung_Delta_IDG_{01..08}_XIX_SAM: required-interface=IF_KY_Ambex_Entfernung_Delta_IDG_{01..08}
      RP_IF_KY_Ambex_Entfernung_IDG_{01..08}_XIX_SAM: required-interface=IF_KY_Ambex_Entfernung_IDG_{01..08}
      RP_IF_KY_Ambex_Richtung_Delta_IDG_{01..08}_XIX_SAM: required-interface=IF_KY_Ambex_Richtung_Delta_IDG_{01..08}
      RP_IF_KY_Ambex_Richtung_IDG_{01..08}_XIX_SAM: required-interface=IF_KY_Ambex_Richtung_IDG_{01..08}
      RP_IF_LE1_ORUData_XIX_SAM: required-interface=IF_LE1_ORUData
      RP_IF_LE1_ORUDataIndex_XIX_SAM: required-interface=IF_LE1_ORUDataIndex
      RP_IF_LE1_TorqueLockStatus_XIX_SAM: required-interface=IF_LE1_TorqueLockStatus
      RP_IF_LE2_ORUData_XIX_SAM: required-interface=IF_LE2_ORUData
      RP_IF_LE2_ORUDataIndex_XIX_SAM: required-interface=IF_LE2_ORUDataIndex
      RP_IF_LE2_TorqueLockStatus_XIX_SAM: required-interface=IF_LE2_TorqueLockStatus
      RP_IF_Lenkhilfe_EPS_ORUData_XIX_SAM: required-interface=IF_Lenkhilfe_EPS_ORUData
      RP_IF_Lenkhilfe_EPS_ORUDataIndex_XIX_SAM: required-interface=IF_Lenkhilfe_EPS_ORUDataIndex
      RP_IF_Leselicht_hi_li_LED_defekt_XIX_SAM: required-interface=IF_Leselicht_hi_li_LED_defekt
      RP_IF_Leselicht_hi_li_SR3_LED_defekt_XIX_SAM: required-interface=IF_Leselicht_hi_li_SR3_LED_defekt
      RP_IF_Leselicht_hi_li_SR3_Taste_defekt_XIX_SAM: required-interface=IF_Leselicht_hi_li_SR3_Taste_defekt
      RP_IF_Leselicht_hi_li_Taste_defekt_XIX_SAM: required-interface=IF_Leselicht_hi_li_Taste_defekt
      RP_IF_Leselicht_hi_re_LED_defekt_XIX_SAM: required-interface=IF_Leselicht_hi_re_LED_defekt
      RP_IF_Leselicht_hi_re_SR3_LED_defekt_XIX_SAM: required-interface=IF_Leselicht_hi_re_SR3_LED_defekt
      RP_IF_Leselicht_hi_re_SR3_Taste_defekt_XIX_SAM: required-interface=IF_Leselicht_hi_re_SR3_Taste_defekt
      RP_IF_Leselicht_hi_re_Taste_defekt_XIX_SAM: required-interface=IF_Leselicht_hi_re_Taste_defekt
      RP_IF_Leselicht_vo_defekt_XIX_SAM: required-interface=IF_Leselicht_vo_defekt
      RP_IF_LIM_Tasten_Innenlicht_V_def_XIX_SAM: required-interface=IF_LIM_Tasten_Innenlicht_V_def
      RP_IF_LIN_SMLS_ECU_defekt_XIX_SAM: required-interface=IF_LIN_SMLS_ECU_defekt
      RP_IF_LIN_SMLS_elektrischer_Fehler_XIX_SAM: required-interface=IF_LIN_SMLS_elektrischer_Fehler
      RP_IF_LIN_SMLS_mechanischer_Fehler_XIX_SAM: required-interface=IF_LIN_SMLS_mechanischer_Fehler
      RP_IF_LIN_SMLS_RAM_ROM_Fehler_XIX_SAM: required-interface=IF_LIN_SMLS_RAM_ROM_Fehler
      RP_IF_LIN_SMLS_ResponseError_XIX_SAM: required-interface=IF_LIN_SMLS_ResponseError
      RP_IF_LIN_SMLS_Ueberspannung_XIX_SAM: required-interface=IF_LIN_SMLS_Ueberspannung
      RP_IF_LIN_SMLS_Unterspannung_XIX_SAM: required-interface=IF_LIN_SMLS_Unterspannung
      RP_IF_LIN_SMLS_Zaehler_XIX_SAM: required-interface=IF_LIN_SMLS_Zaehler
      RP_IF_LINDa_defekt_XIX_SAM: required-interface=IF_LINDa_defekt
      RP_IF_LINDa_ResponseError_XIX_SAM: required-interface=IF_LINDa_ResponseError
      RP_IF_LINDa_S_Rollo_vo_XIX_SAM: required-interface=IF_LINDa_S_Rollo_vo
      RP_IF_LLP_L_ORUData_XIX_SAM: required-interface=IF_LLP_L_ORUData
      RP_IF_LLP_L_ORUDataIndex_XIX_SAM: required-interface=IF_LLP_L_ORUDataIndex
      RP_IF_LLP_R_ORUData_XIX_SAM: required-interface=IF_LLP_R_ORUData
      RP_IF_LLP_R_ORUDataIndex_XIX_SAM: required-interface=IF_LLP_R_ORUDataIndex
      RP_IF_LLR_LL1_Blockierung_XIX_SAM: required-interface=IF_LLR_LL1_Blockierung
      RP_IF_LLR_LL1_CodierPinError_XIX_SAM: required-interface=IF_LLR_LL1_CodierPinError
      RP_IF_LLR_LL1_Ist_Drehzahl_XIX_SAM: required-interface=IF_LLR_LL1_Ist_Drehzahl
      RP_IF_LLR_LL1_Lokalaktiv_XIX_SAM: required-interface=IF_LLR_LL1_Lokalaktiv
      RP_IF_LLR_LL1_Luefter_defekt_XIX_SAM: required-interface=IF_LLR_LL1_Luefter_defekt
      RP_IF_LLR_LL1_ResponseError_XIX_SAM: required-interface=IF_LLR_LL1_ResponseError
      RP_IF_LLR_LL1_Ueberspannung_XIX_SAM: required-interface=IF_LLR_LL1_Ueberspannung
      RP_IF_LLR_LL1_Uebertemperatur_XIX_SAM: required-interface=IF_LLR_LL1_Uebertemperatur
      RP_IF_LLR_LL1_Unterspannung_XIX_SAM: required-interface=IF_LLR_LL1_Unterspannung
      RP_IF_LLR_LS1_Blockierung_XIX_SAM: required-interface=IF_LLR_LS1_Blockierung
      RP_IF_LLR_LS1_CodierPinError_XIX_SAM: required-interface=IF_LLR_LS1_CodierPinError
      RP_IF_LLR_LS1_Ist_Drehzahl_XIX_SAM: required-interface=IF_LLR_LS1_Ist_Drehzahl
      RP_IF_LLR_LS1_Lokalaktiv_XIX_SAM: required-interface=IF_LLR_LS1_Lokalaktiv
      RP_IF_LLR_LS1_Luefter_defekt_XIX_SAM: required-interface=IF_LLR_LS1_Luefter_defekt
      RP_IF_LLR_LS1_ResponseError_XIX_SAM: required-interface=IF_LLR_LS1_ResponseError
      RP_IF_LLR_LS1_Ueberspannung_XIX_SAM: required-interface=IF_LLR_LS1_Ueberspannung
      RP_IF_LLR_LS1_Uebertemperatur_XIX_SAM: required-interface=IF_LLR_LS1_Uebertemperatur
      RP_IF_LLR_LS1_Unterspannung_XIX_SAM: required-interface=IF_LLR_LS1_Unterspannung
      RP_IF_LLR_RL1_Blockierung_XIX_SAM: required-interface=IF_LLR_RL1_Blockierung
      RP_IF_LLR_RL1_CodierPinError_XIX_SAM: required-interface=IF_LLR_RL1_CodierPinError
      RP_IF_LLR_RL1_Ist_Drehzahl_XIX_SAM: required-interface=IF_LLR_RL1_Ist_Drehzahl
      RP_IF_LLR_RL1_Lokalaktiv_XIX_SAM: required-interface=IF_LLR_RL1_Lokalaktiv
      RP_IF_LLR_RL1_Luefter_defekt_XIX_SAM: required-interface=IF_LLR_RL1_Luefter_defekt
      RP_IF_LLR_RL1_ResponseError_XIX_SAM: required-interface=IF_LLR_RL1_ResponseError
      RP_IF_LLR_RL1_Ueberspannung_XIX_SAM: required-interface=IF_LLR_RL1_Ueberspannung
      RP_IF_LLR_RL1_Uebertemperatur_XIX_SAM: required-interface=IF_LLR_RL1_Uebertemperatur
      RP_IF_LLR_RL1_Unterspannung_XIX_SAM: required-interface=IF_LLR_RL1_Unterspannung
      RP_IF_LLR_RS1_Blockierung_XIX_SAM: required-interface=IF_LLR_RS1_Blockierung
      RP_IF_LLR_RS1_CodierPinError_XIX_SAM: required-interface=IF_LLR_RS1_CodierPinError
      RP_IF_LLR_RS1_Ist_Drehzahl_XIX_SAM: required-interface=IF_LLR_RS1_Ist_Drehzahl
      RP_IF_LLR_RS1_Lokalaktiv_XIX_SAM: required-interface=IF_LLR_RS1_Lokalaktiv
      RP_IF_LLR_RS1_Luefter_defekt_XIX_SAM: required-interface=IF_LLR_RS1_Luefter_defekt
      RP_IF_LLR_RS1_ResponseError_XIX_SAM: required-interface=IF_LLR_RS1_ResponseError
      RP_IF_LLR_RS1_Ueberspannung_XIX_SAM: required-interface=IF_LLR_RS1_Ueberspannung
      RP_IF_LLR_RS1_Uebertemperatur_XIX_SAM: required-interface=IF_LLR_RS1_Uebertemperatur
      RP_IF_LLR_RS1_Unterspannung_XIX_SAM: required-interface=IF_LLR_RS1_Unterspannung
      RP_IF_LnchCtl_StReq_XIX_SAM: required-interface=IF_LnchCtl_StReq
      RP_IF_LR_HZG_Konfiguration_XIX_SAM: required-interface=IF_LR_HZG_Konfiguration
      RP_IF_LR_HZG_Taster_on_off_XIX_SAM: required-interface=IF_LR_HZG_Taster_on_off
      RP_IF_LR_HZG_Temp_Sensor_XIX_SAM: required-interface=IF_LR_HZG_Temp_Sensor
      RP_IF_LRH_aktiv_XIX_SAM: required-interface=IF_LRH_aktiv
      RP_IF_LRH_On_Off_XIX_SAM: required-interface=IF_LRH_On_Off
      RP_IF_LRH_Stellglied_aktiv_XIX_SAM: required-interface=IF_LRH_Stellglied_aktiv
      RP_IF_LRL1_ORUData_XIX_SAM: required-interface=IF_LRL1_ORUData
      RP_IF_LRL1_ORUDataIndex_XIX_SAM: required-interface=IF_LRL1_ORUDataIndex
      RP_IF_LRL2_ORUData_XIX_SAM: required-interface=IF_LRL2_ORUData
      RP_IF_LRL2_ORUDataIndex_XIX_SAM: required-interface=IF_LRL2_ORUDataIndex
      RP_IF_LRL3_ORUData_XIX_SAM: required-interface=IF_LRL3_ORUData
      RP_IF_LRL3_ORUDataIndex_XIX_SAM: required-interface=IF_LRL3_ORUDataIndex
      RP_IF_LRL_L_01_BZ_XIX_SAM: required-interface=IF_LRL_L_01_BZ
      RP_IF_LRL_L_01_CRC_XIX_SAM: required-interface=IF_LRL_L_01_CRC
      RP_IF_LRL_M_01_BZ_XIX_SAM: required-interface=IF_LRL_M_01_BZ
      RP_IF_LRL_M_01_CRC_XIX_SAM: required-interface=IF_LRL_M_01_CRC
      RP_IF_LRL_R_01_BZ_XIX_SAM: required-interface=IF_LRL_R_01_BZ
      RP_IF_LRL_R_01_CRC_XIX_SAM: required-interface=IF_LRL_R_01_CRC
      RP_IF_LS_Dunkel_XIX_SAM: required-interface=IF_LS_Dunkel
      RP_IF_LS_Error_XIX_SAM: required-interface=IF_LS_Error
      RP_IF_LS_Helligkeit_FW_XIX_SAM: required-interface=IF_LS_Helligkeit_FW
      RP_IF_LS_Helligkeit_IR_XIX_SAM: required-interface=IF_LS_Helligkeit_IR
      RP_IF_LS_Licht_ein_invers_XIX_SAM: required-interface=IF_LS_Licht_ein_invers
      RP_IF_LS_Licht_ein_XIX_SAM: required-interface=IF_LS_Licht_ein
      RP_IF_LS_TFL_mit_SL_ein_XIX_SAM: required-interface=IF_LS_TFL_mit_SL_ein
      RP_IF_LSS_Tastencode_XIX_SAM: required-interface=IF_LSS_Tastencode
      RP_IF_LTM_ResponseError_XIX_SAM: required-interface=IF_LTM_ResponseError
      RP_IF_LTM_StatusLichttastenmodul_XIX_SAM: required-interface=IF_LTM_StatusLichttastenmodul
      RP_IF_LV_Abblendlicht_Anzeige_XIX_SAM: required-interface=IF_LV_Abblendlicht_Anzeige
      RP_IF_LWR_SollDC_XIX_SAM: required-interface=IF_LWR_SollDC
      RP_IF_MaaSBladeMyc_ORUData_XIX_SAM: required-interface=IF_MaaSBladeMyc_ORUData
      RP_IF_MaaSBladeMyc_ORUDataIndex_XIX_SAM: required-interface=IF_MaaSBladeMyc_ORUDataIndex
      RP_IF_MainBlade_ORUData_XIX_SAM: required-interface=IF_MainBlade_ORUData
      RP_IF_MainBlade_ORUDataIndex_XIX_SAM: required-interface=IF_MainBlade_ORUDataIndex
      RP_IF_MF_DCDC_Istmodus_XIX_SAM: required-interface=IF_MF_DCDC_Istmodus
      RP_IF_MF_Fahrlicht_XIX_SAM: required-interface=IF_MF_Fahrlicht
      RP_IF_MF_Fernbed_ein_XIX_SAM: required-interface=IF_MF_Fernbed_ein
      RP_IF_MF_Frontintervall_XIX_SAM: required-interface=IF_MF_Frontintervall
      RP_IF_MF_Frontwaschen_XIX_SAM: required-interface=IF_MF_Frontwaschen
      RP_IF_MF_Fussraumbel_XIX_SAM: required-interface=IF_MF_Fussraumbel
      RP_IF_MF_Heckintervall_XIX_SAM: required-interface=IF_MF_Heckintervall
      RP_IF_MF_Heckwaschen_XIX_SAM: required-interface=IF_MF_Heckwaschen
      RP_IF_MF_Innenraumbel_Unterdrueck_XIX_SAM: required-interface=IF_MF_Innenraumbel_Unterdrueck
      RP_IF_MF_Innenraumbel_XIX_SAM: required-interface=IF_MF_Innenraumbel
      RP_IF_MF_Motorweiterlauf_XIX_SAM: required-interface=IF_MF_Motorweiterlauf
      RP_IF_MF_Signalhorn_XIX_SAM: required-interface=IF_MF_Signalhorn
      RP_IF_MF_Tippwischen_XIX_SAM: required-interface=IF_MF_Tippwischen
      RP_IF_MF_Variante_XIX_SAM: required-interface=IF_MF_Variante
      RP_IF_MF_Wischerstufe_1_XIX_SAM: required-interface=IF_MF_Wischerstufe_1
      RP_IF_MF_Wischerstufe_2_XIX_SAM: required-interface=IF_MF_Wischerstufe_2
      RP_IF_MFG_01_BZ_XIX_SAM: required-interface=IF_MFG_01_BZ
      RP_IF_MFG_01_CRC_XIX_SAM: required-interface=IF_MFG_01_CRC
      RP_IF_MFK_ORUData_XIX_SAM: required-interface=IF_MFK_ORUData
      RP_IF_MFK_ORUDataIndex_XIX_SAM: required-interface=IF_MFK_ORUDataIndex
      RP_IF_MFL_CAN_ORUData_XIX_SAM: required-interface=IF_MFL_CAN_ORUData
      RP_IF_MFL_CAN_ORUDataIndex_XIX_SAM: required-interface=IF_MFL_CAN_ORUDataIndex
      RP_IF_MFL_Signalhorn_XIX_SAM: required-interface=IF_MFL_Signalhorn
      RP_IF_MO_Fahrbereitschaft_XIX_SAM: required-interface=IF_MO_Fahrbereitschaft
      RP_IF_MO_Fahrpedalrohwert_01_XIX_SAM: required-interface=IF_MO_Fahrpedalrohwert_01
      RP_IF_MO_HYB_Fahrbereitschaft_XIX_SAM: required-interface=IF_MO_HYB_Fahrbereitschaft
      RP_IF_Motor_BEV_ORUData_XIX_SAM: required-interface=IF_Motor_BEV_ORUData
      RP_IF_Motor_BEV_ORUDataIndex_XIX_SAM: required-interface=IF_Motor_BEV_ORUDataIndex
      RP_IF_NM_eCall_NM_State_XIX_SAM: required-interface=IF_NM_eCall_NM_State
      RP_IF_NM_ELV_NM_State_XIX_SAM: required-interface=IF_NM_ELV_NM_State
      RP_IF_NM_Gateway_NM_State_XIX_SAM: required-interface=IF_NM_Gateway_NM_State
      RP_IF_NM_Kessy2_NM_State_XIX_SAM: required-interface=IF_NM_Kessy2_NM_State
      RP_IF_NM_Kessy_NM_State_XIX_SAM: required-interface=IF_NM_Kessy_NM_State
      RP_IF_NM_MFG_NM_State_XIX_SAM: required-interface=IF_NM_MFG_NM_State
      RP_IF_NM_NFC_TGS_NM_State_XIX_SAM: required-interface=IF_NM_NFC_TGS_NM_State
      RP_IF_NM_RSAD_HL_NM_State_XIX_SAM: required-interface=IF_NM_RSAD_HL_NM_State
      RP_IF_NM_RSAD_HR_NM_State_XIX_SAM: required-interface=IF_NM_RSAD_HR_NM_State
      RP_IF_NM_RSAD_IN_NM_State_XIX_SAM: required-interface=IF_NM_RSAD_IN_NM_State
      RP_IF_NM_RSAD_VL_NM_State_XIX_SAM: required-interface=IF_NM_RSAD_VL_NM_State
      RP_IF_NM_RSAD_VR_NM_State_XIX_SAM: required-interface=IF_NM_RSAD_VR_NM_State
      RP_IF_NM_WLC1_NM_State_XIX_SAM: required-interface=IF_NM_WLC1_NM_State
      RP_IF_NR1_ORUData_XIX_SAM: required-interface=IF_NR1_ORUData
      RP_IF_NR1_ORUDataIndex_XIX_SAM: required-interface=IF_NR1_ORUDataIndex
      RP_IF_NR2_ORUData_XIX_SAM: required-interface=IF_NR2_ORUData
      RP_IF_NR2_ORUDataIndex_XIX_SAM: required-interface=IF_NR2_ORUDataIndex
      RP_IF_NR3_ORUData_XIX_SAM: required-interface=IF_NR3_ORUData
      RP_IF_NR3_ORUDataIndex_XIX_SAM: required-interface=IF_NR3_ORUDataIndex
      RP_IF_NR4_ORUData_XIX_SAM: required-interface=IF_NR4_ORUData
      RP_IF_NR4_ORUDataIndex_XIX_SAM: required-interface=IF_NR4_ORUDataIndex
      RP_IF_NVEM_Abschaltstufe_XIX_SAM: required-interface=IF_NVEM_Abschaltstufe
      RP_IF_OBD_Driving_Cycle_XIX_SAM: required-interface=IF_OBD_Driving_Cycle
      RP_IF_OBD_Warm_Up_Cycle_XIX_SAM: required-interface=IF_OBD_Warm_Up_Cycle
      RP_IF_OCC_ORUData_XIX_SAM: required-interface=IF_OCC_ORUData
      RP_IF_OCC_ORUDataIndex_XIX_SAM: required-interface=IF_OCC_ORUDataIndex
      RP_IF_OPS_ComfortReadyStatus_XIX_SAM: required-interface=IF_OPS_ComfortReadyStatus
      RP_IF_OPS_DriverPresenceStatus_XIX_SAM: required-interface=IF_OPS_DriverPresenceStatus
      RP_IF_ORU_0001_BZ_XIX_SAM: required-interface=IF_ORU_0001_BZ
      RP_IF_ORU_0001_CRC_XIX_SAM: required-interface=IF_ORU_0001_CRC
      RP_IF_ORU_0003_BZ_XIX_SAM: required-interface=IF_ORU_0003_BZ
      RP_IF_ORU_0003_CRC_XIX_SAM: required-interface=IF_ORU_0003_CRC
      RP_IF_ORU_0006_BZ_XIX_SAM: required-interface=IF_ORU_0006_BZ
      RP_IF_ORU_0006_CRC_XIX_SAM: required-interface=IF_ORU_0006_CRC
      RP_IF_ORU_0013_BZ_XIX_SAM: required-interface=IF_ORU_0013_BZ
      RP_IF_ORU_0013_CRC_XIX_SAM: required-interface=IF_ORU_0013_CRC
      RP_IF_ORU_0015_BZ_XIX_SAM: required-interface=IF_ORU_0015_BZ
      RP_IF_ORU_0015_CRC_XIX_SAM: required-interface=IF_ORU_0015_CRC
      RP_IF_ORU_0016_BZ_XIX_SAM: required-interface=IF_ORU_0016_BZ
      RP_IF_ORU_0016_CRC_XIX_SAM: required-interface=IF_ORU_0016_CRC
      RP_IF_ORU_0019_BZ_XIX_SAM: required-interface=IF_ORU_0019_BZ
      RP_IF_ORU_0019_CRC_XIX_SAM: required-interface=IF_ORU_0019_CRC
      RP_IF_ORU_0023_BZ_XIX_SAM: required-interface=IF_ORU_0023_BZ
      RP_IF_ORU_0023_CRC_XIX_SAM: required-interface=IF_ORU_0023_CRC
      RP_IF_ORU_0036_BZ_XIX_SAM: required-interface=IF_ORU_0036_BZ
      RP_IF_ORU_0036_CRC_XIX_SAM: required-interface=IF_ORU_0036_CRC
      RP_IF_ORU_003D_BZ_XIX_SAM: required-interface=IF_ORU_003D_BZ
      RP_IF_ORU_003D_CRC_XIX_SAM: required-interface=IF_ORU_003D_CRC
      RP_IF_ORU_0042_BZ_XIX_SAM: required-interface=IF_ORU_0042_BZ
      RP_IF_ORU_0042_CRC_XIX_SAM: required-interface=IF_ORU_0042_CRC
      RP_IF_ORU_0044_BZ_XIX_SAM: required-interface=IF_ORU_0044_BZ
      RP_IF_ORU_0044_CRC_XIX_SAM: required-interface=IF_ORU_0044_CRC
      RP_IF_ORU_0048_BZ_XIX_SAM: required-interface=IF_ORU_0048_BZ
      RP_IF_ORU_0048_CRC_XIX_SAM: required-interface=IF_ORU_0048_CRC
      RP_IF_ORU_0051_BZ_XIX_SAM: required-interface=IF_ORU_0051_BZ
      RP_IF_ORU_0051_CRC_XIX_SAM: required-interface=IF_ORU_0051_CRC
      RP_IF_ORU_0052_BZ_XIX_SAM: required-interface=IF_ORU_0052_BZ
      RP_IF_ORU_0052_CRC_XIX_SAM: required-interface=IF_ORU_0052_CRC
      RP_IF_ORU_005B_BZ_XIX_SAM: required-interface=IF_ORU_005B_BZ
      RP_IF_ORU_005B_CRC_XIX_SAM: required-interface=IF_ORU_005B_CRC
      RP_IF_ORU_0069_BZ_XIX_SAM: required-interface=IF_ORU_0069_BZ
      RP_IF_ORU_0069_CRC_XIX_SAM: required-interface=IF_ORU_0069_CRC
      RP_IF_ORU_006A_BZ_XIX_SAM: required-interface=IF_ORU_006A_BZ
      RP_IF_ORU_006A_CRC_XIX_SAM: required-interface=IF_ORU_006A_CRC
      RP_IF_ORU_0076_BZ_XIX_SAM: required-interface=IF_ORU_0076_BZ
      RP_IF_ORU_0076_CRC_XIX_SAM: required-interface=IF_ORU_0076_CRC
      RP_IF_ORU_007A_BZ_XIX_SAM: required-interface=IF_ORU_007A_BZ
      RP_IF_ORU_007A_CRC_XIX_SAM: required-interface=IF_ORU_007A_CRC
      RP_IF_ORU_007E_BZ_XIX_SAM: required-interface=IF_ORU_007E_BZ
      RP_IF_ORU_007E_CRC_XIX_SAM: required-interface=IF_ORU_007E_CRC
      RP_IF_ORU_0082_BZ_XIX_SAM: required-interface=IF_ORU_0082_BZ
      RP_IF_ORU_0082_CRC_XIX_SAM: required-interface=IF_ORU_0082_CRC
      RP_IF_ORU_008C_BZ_XIX_SAM: required-interface=IF_ORU_008C_BZ
      RP_IF_ORU_008C_CRC_XIX_SAM: required-interface=IF_ORU_008C_CRC
      RP_IF_ORU_00A5_BZ_XIX_SAM: required-interface=IF_ORU_00A5_BZ
      RP_IF_ORU_00A5_CRC_XIX_SAM: required-interface=IF_ORU_00A5_CRC
      RP_IF_ORU_00BB_BZ_XIX_SAM: required-interface=IF_ORU_00BB_BZ
      RP_IF_ORU_00BB_CRC_XIX_SAM: required-interface=IF_ORU_00BB_CRC
      RP_IF_ORU_00BC_BZ_XIX_SAM: required-interface=IF_ORU_00BC_BZ
      RP_IF_ORU_00BC_CRC_XIX_SAM: required-interface=IF_ORU_00BC_CRC
      RP_IF_ORU_00C6_BZ_XIX_SAM: required-interface=IF_ORU_00C6_BZ
      RP_IF_ORU_00C6_CRC_XIX_SAM: required-interface=IF_ORU_00C6_CRC
      RP_IF_ORU_00CE_BZ_XIX_SAM: required-interface=IF_ORU_00CE_BZ
      RP_IF_ORU_00CE_CRC_XIX_SAM: required-interface=IF_ORU_00CE_CRC
      RP_IF_ORU_00D6_BZ_XIX_SAM: required-interface=IF_ORU_00D6_BZ
      RP_IF_ORU_00D6_CRC_XIX_SAM: required-interface=IF_ORU_00D6_CRC
      RP_IF_ORU_00D7_BZ_XIX_SAM: required-interface=IF_ORU_00D7_BZ
      RP_IF_ORU_00D7_CRC_XIX_SAM: required-interface=IF_ORU_00D7_CRC
      RP_IF_ORU_0631_BZ_XIX_SAM: required-interface=IF_ORU_0631_BZ
      RP_IF_ORU_0631_CRC_XIX_SAM: required-interface=IF_ORU_0631_CRC
      RP_IF_ORU_8105_BZ_XIX_SAM: required-interface=IF_ORU_8105_BZ
      RP_IF_ORU_8105_CRC_XIX_SAM: required-interface=IF_ORU_8105_CRC
      RP_IF_ORU_8109_BZ_XIX_SAM: required-interface=IF_ORU_8109_BZ
      RP_IF_ORU_8109_CRC_XIX_SAM: required-interface=IF_ORU_8109_CRC
      RP_IF_ORU_810A_BZ_XIX_SAM: required-interface=IF_ORU_810A_BZ
      RP_IF_ORU_810A_CRC_XIX_SAM: required-interface=IF_ORU_810A_CRC
      RP_IF_ORU_810B_BZ_XIX_SAM: required-interface=IF_ORU_810B_BZ
      RP_IF_ORU_810B_CRC_XIX_SAM: required-interface=IF_ORU_810B_CRC
      RP_IF_ORU_810C_BZ_XIX_SAM: required-interface=IF_ORU_810C_BZ
      RP_IF_ORU_810C_CRC_XIX_SAM: required-interface=IF_ORU_810C_CRC
      RP_IF_ORU_8133_BZ_XIX_SAM: required-interface=IF_ORU_8133_BZ
      RP_IF_ORU_8133_CRC_XIX_SAM: required-interface=IF_ORU_8133_CRC
      RP_IF_ORU_8134_BZ_XIX_SAM: required-interface=IF_ORU_8134_BZ
      RP_IF_ORU_8134_CRC_XIX_SAM: required-interface=IF_ORU_8134_CRC
      RP_IF_ORU_8179_BZ_XIX_SAM: required-interface=IF_ORU_8179_BZ
      RP_IF_ORU_8179_CRC_XIX_SAM: required-interface=IF_ORU_8179_CRC
      RP_IF_ORU_817B_BZ_XIX_SAM: required-interface=IF_ORU_817B_BZ
      RP_IF_ORU_817B_CRC_XIX_SAM: required-interface=IF_ORU_817B_CRC
      RP_IF_ORU_8181_BZ_XIX_SAM: required-interface=IF_ORU_8181_BZ
      RP_IF_ORU_8181_CRC_XIX_SAM: required-interface=IF_ORU_8181_CRC
      RP_IF_ORU_AP_Mode_XIX_SAM: required-interface=IF_ORU_AP_Mode
      RP_IF_ORU_DiagAddress_XIX_SAM: required-interface=IF_ORU_DiagAddress
      RP_IF_ORU_Status_XIX_SAM: required-interface=IF_ORU_Status
      RP_IF_ORUG01_01_BZ_XIX_SAM: required-interface=IF_ORUG01_01_BZ
      RP_IF_ORUG01_01_CRC_XIX_SAM: required-interface=IF_ORUG01_01_CRC
      RP_IF_ORUG1_HVReleased_XIX_SAM: required-interface=IF_ORUG1_HVReleased
      RP_IF_ORUG1_TargetRelease_XIX_SAM: required-interface=IF_ORUG1_TargetRelease
      RP_IF_Parken_aktives_System_02_XIX_SAM: required-interface=IF_Parken_aktives_System_02
      RP_IF_Perso_Kontonummer_XIX_SAM: required-interface=IF_Perso_Kontonummer
      RP_IF_Perso_Status_XIX_SAM: required-interface=IF_Perso_Status
      RP_IF_Perso_Steuerung_XIX_SAM: required-interface=IF_Perso_Steuerung
      RP_IF_Perso_Steuerungsparameter_XIX_SAM: required-interface=IF_Perso_Steuerungsparameter
      RP_IF_PreCrash_BFS_Pneumatik_ansteuern_XIX_SAM: required-interface=IF_PreCrash_BFS_Pneumatik_ansteuern
      RP_IF_PreCrash_Fenster_schliessen_XIX_SAM: required-interface=IF_PreCrash_Fenster_schliessen
      RP_IF_PreCrash_FS_Pneumatik_ansteuern_XIX_SAM: required-interface=IF_PreCrash_FS_Pneumatik_ansteuern
      RP_IF_RCTA_Kritikalitaetslevel_links_XIX_SAM: required-interface=IF_RCTA_Kritikalitaetslevel_links
      RP_IF_RCTA_Kritikalitaetslevel_rechts_XIX_SAM: required-interface=IF_RCTA_Kritikalitaetslevel_rechts
      RP_IF_RGB_Slave_01_IntErrorNvm_XIX_SAM: required-interface=IF_RGB_Slave_01_IntErrorNvm
      RP_IF_RGB_Slave_01_IntErrorRam_XIX_SAM: required-interface=IF_RGB_Slave_01_IntErrorRam
      RP_IF_RGB_Slave_01_IntErrorRom_XIX_SAM: required-interface=IF_RGB_Slave_01_IntErrorRom
      RP_IF_RGB_Slave_01_LedBlauOl_XIX_SAM: required-interface=IF_RGB_Slave_01_LedBlauOl
      RP_IF_RGB_Slave_01_LedBlauStg_XIX_SAM: required-interface=IF_RGB_Slave_01_LedBlauStg
      RP_IF_RGB_Slave_01_LedGruenOl_XIX_SAM: required-interface=IF_RGB_Slave_01_LedGruenOl
      RP_IF_RGB_Slave_01_LedGruenStg_XIX_SAM: required-interface=IF_RGB_Slave_01_LedGruenStg
      RP_IF_RGB_Slave_01_LedRotOl_XIX_SAM: required-interface=IF_RGB_Slave_01_LedRotOl
      RP_IF_RGB_Slave_01_LedRotStg_XIX_SAM: required-interface=IF_RGB_Slave_01_LedRotStg
      RP_IF_RGB_Slave_01_ResponseError_XIX_SAM: required-interface=IF_RGB_Slave_01_ResponseError
      RP_IF_RGB_Slave_01_TempState_XIX_SAM: required-interface=IF_RGB_Slave_01_TempState
      RP_IF_RGB_Slave_02_IntErrorNvm_XIX_SAM: required-interface=IF_RGB_Slave_02_IntErrorNvm
      RP_IF_RGB_Slave_02_IntErrorRam_XIX_SAM: required-interface=IF_RGB_Slave_02_IntErrorRam
      RP_IF_RGB_Slave_02_IntErrorRom_XIX_SAM: required-interface=IF_RGB_Slave_02_IntErrorRom
      RP_IF_RGB_Slave_02_LedBlauOl_XIX_SAM: required-interface=IF_RGB_Slave_02_LedBlauOl
      RP_IF_RGB_Slave_02_LedBlauStg_XIX_SAM: required-interface=IF_RGB_Slave_02_LedBlauStg
      RP_IF_RGB_Slave_02_LedGruenOl_XIX_SAM: required-interface=IF_RGB_Slave_02_LedGruenOl
      RP_IF_RGB_Slave_02_LedGruenStg_XIX_SAM: required-interface=IF_RGB_Slave_02_LedGruenStg
      RP_IF_RGB_Slave_02_LedRotOl_XIX_SAM: required-interface=IF_RGB_Slave_02_LedRotOl
      RP_IF_RGB_Slave_02_LedRotStg_XIX_SAM: required-interface=IF_RGB_Slave_02_LedRotStg
      RP_IF_RGB_Slave_02_ResponseError_XIX_SAM: required-interface=IF_RGB_Slave_02_ResponseError
      RP_IF_RGB_Slave_02_TempState_XIX_SAM: required-interface=IF_RGB_Slave_02_TempState
      RP_IF_RGB_Slave_03_IntErrorNvm_XIX_SAM: required-interface=IF_RGB_Slave_03_IntErrorNvm
      RP_IF_RGB_Slave_03_IntErrorRam_XIX_SAM: required-interface=IF_RGB_Slave_03_IntErrorRam
      RP_IF_RGB_Slave_03_IntErrorRom_XIX_SAM: required-interface=IF_RGB_Slave_03_IntErrorRom
      RP_IF_RGB_Slave_03_LedBlauOl_XIX_SAM: required-interface=IF_RGB_Slave_03_LedBlauOl
      RP_IF_RGB_Slave_03_LedBlauStg_XIX_SAM: required-interface=IF_RGB_Slave_03_LedBlauStg
      RP_IF_RGB_Slave_03_LedGruenOl_XIX_SAM: required-interface=IF_RGB_Slave_03_LedGruenOl
      RP_IF_RGB_Slave_03_LedGruenStg_XIX_SAM: required-interface=IF_RGB_Slave_03_LedGruenStg
      RP_IF_RGB_Slave_03_LedRotOl_XIX_SAM: required-interface=IF_RGB_Slave_03_LedRotOl
      RP_IF_RGB_Slave_03_LedRotStg_XIX_SAM: required-interface=IF_RGB_Slave_03_LedRotStg
      RP_IF_RGB_Slave_03_ResponseError_XIX_SAM: required-interface=IF_RGB_Slave_03_ResponseError
      RP_IF_RGB_Slave_03_TempState_XIX_SAM: required-interface=IF_RGB_Slave_03_TempState
      RP_IF_RGB_Slave_04_IntErrorNvm_XIX_SAM: required-interface=IF_RGB_Slave_04_IntErrorNvm
      RP_IF_RGB_Slave_04_IntErrorRam_XIX_SAM: required-interface=IF_RGB_Slave_04_IntErrorRam
      RP_IF_RGB_Slave_04_IntErrorRom_XIX_SAM: required-interface=IF_RGB_Slave_04_IntErrorRom
      RP_IF_RGB_Slave_04_LedBlauOl_XIX_SAM: required-interface=IF_RGB_Slave_04_LedBlauOl
      RP_IF_RGB_Slave_04_LedBlauStg_XIX_SAM: required-interface=IF_RGB_Slave_04_LedBlauStg
      RP_IF_RGB_Slave_04_LedGruenOl_XIX_SAM: required-interface=IF_RGB_Slave_04_LedGruenOl
      RP_IF_RGB_Slave_04_LedGruenStg_XIX_SAM: required-interface=IF_RGB_Slave_04_LedGruenStg
      RP_IF_RGB_Slave_04_LedRotOl_XIX_SAM: required-interface=IF_RGB_Slave_04_LedRotOl
      RP_IF_RGB_Slave_04_LedRotStg_XIX_SAM: required-interface=IF_RGB_Slave_04_LedRotStg
      RP_IF_RGB_Slave_04_ResponseError_XIX_SAM: required-interface=IF_RGB_Slave_04_ResponseError
      RP_IF_RGB_Slave_04_TempState_XIX_SAM: required-interface=IF_RGB_Slave_04_TempState
      RP_IF_RGB_Slave_05_IntErrorNvm_XIX_SAM: required-interface=IF_RGB_Slave_05_IntErrorNvm
      RP_IF_RGB_Slave_05_IntErrorRam_XIX_SAM: required-interface=IF_RGB_Slave_05_IntErrorRam
      RP_IF_RGB_Slave_05_IntErrorRom_XIX_SAM: required-interface=IF_RGB_Slave_05_IntErrorRom
      RP_IF_RGB_Slave_05_LedBlauOl_XIX_SAM: required-interface=IF_RGB_Slave_05_LedBlauOl
      RP_IF_RGB_Slave_05_LedBlauStg_XIX_SAM: required-interface=IF_RGB_Slave_05_LedBlauStg
      RP_IF_RGB_Slave_05_LedGruenOl_XIX_SAM: required-interface=IF_RGB_Slave_05_LedGruenOl
      RP_IF_RGB_Slave_05_LedGruenStg_XIX_SAM: required-interface=IF_RGB_Slave_05_LedGruenStg
      RP_IF_RGB_Slave_05_LedRotOl_XIX_SAM: required-interface=IF_RGB_Slave_05_LedRotOl
      RP_IF_RGB_Slave_05_LedRotStg_XIX_SAM: required-interface=IF_RGB_Slave_05_LedRotStg
      RP_IF_RGB_Slave_05_ResponseError_XIX_SAM: required-interface=IF_RGB_Slave_05_ResponseError
      RP_IF_RGB_Slave_05_TempState_XIX_SAM: required-interface=IF_RGB_Slave_05_TempState
      RP_IF_RGB_Slave_06_IntErrorNvm_XIX_SAM: required-interface=IF_RGB_Slave_06_IntErrorNvm
      RP_IF_RGB_Slave_06_IntErrorRam_XIX_SAM: required-interface=IF_RGB_Slave_06_IntErrorRam
      RP_IF_RGB_Slave_06_IntErrorRom_XIX_SAM: required-interface=IF_RGB_Slave_06_IntErrorRom
      RP_IF_RGB_Slave_06_LedBlauOl_XIX_SAM: required-interface=IF_RGB_Slave_06_LedBlauOl
      RP_IF_RGB_Slave_06_LedBlauStg_XIX_SAM: required-interface=IF_RGB_Slave_06_LedBlauStg
      RP_IF_RGB_Slave_06_LedGruenOl_XIX_SAM: required-interface=IF_RGB_Slave_06_LedGruenOl
      RP_IF_RGB_Slave_06_LedGruenStg_XIX_SAM: required-interface=IF_RGB_Slave_06_LedGruenStg
      RP_IF_RGB_Slave_06_LedRotOl_XIX_SAM: required-interface=IF_RGB_Slave_06_LedRotOl
      RP_IF_RGB_Slave_06_LedRotStg_XIX_SAM: required-interface=IF_RGB_Slave_06_LedRotStg
      RP_IF_RGB_Slave_06_ResponseError_XIX_SAM: required-interface=IF_RGB_Slave_06_ResponseError
      RP_IF_RGB_Slave_06_TempState_XIX_SAM: required-interface=IF_RGB_Slave_06_TempState
      RP_IF_RGB_Slave_07_IntErrorNvm_XIX_SAM: required-interface=IF_RGB_Slave_07_IntErrorNvm
      RP_IF_RGB_Slave_07_IntErrorRam_XIX_SAM: required-interface=IF_RGB_Slave_07_IntErrorRam
      RP_IF_RGB_Slave_07_IntErrorRom_XIX_SAM: required-interface=IF_RGB_Slave_07_IntErrorRom
      RP_IF_RGB_Slave_07_LedBlauOl_XIX_SAM: required-interface=IF_RGB_Slave_07_LedBlauOl
      RP_IF_RGB_Slave_07_LedBlauStg_XIX_SAM: required-interface=IF_RGB_Slave_07_LedBlauStg
      RP_IF_RGB_Slave_07_LedGruenOl_XIX_SAM: required-interface=IF_RGB_Slave_07_LedGruenOl
      RP_IF_RGB_Slave_07_LedGruenStg_XIX_SAM: required-interface=IF_RGB_Slave_07_LedGruenStg
      RP_IF_RGB_Slave_07_LedRotOl_XIX_SAM: required-interface=IF_RGB_Slave_07_LedRotOl
      RP_IF_RGB_Slave_07_LedRotStg_XIX_SAM: required-interface=IF_RGB_Slave_07_LedRotStg
      RP_IF_RGB_Slave_07_ResponseError_XIX_SAM: required-interface=IF_RGB_Slave_07_ResponseError
      RP_IF_RGB_Slave_07_TempState_XIX_SAM: required-interface=IF_RGB_Slave_07_TempState
      RP_IF_RGB_Slave_08_IntErrorNvm_XIX_SAM: required-interface=IF_RGB_Slave_08_IntErrorNvm
      RP_IF_RGB_Slave_08_IntErrorRam_XIX_SAM: required-interface=IF_RGB_Slave_08_IntErrorRam
      RP_IF_RGB_Slave_08_IntErrorRom_XIX_SAM: required-interface=IF_RGB_Slave_08_IntErrorRom
      RP_IF_RGB_Slave_08_LedBlauOl_XIX_SAM: required-interface=IF_RGB_Slave_08_LedBlauOl
      RP_IF_RGB_Slave_08_LedBlauStg_XIX_SAM: required-interface=IF_RGB_Slave_08_LedBlauStg
      RP_IF_RGB_Slave_08_LedGruenOl_XIX_SAM: required-interface=IF_RGB_Slave_08_LedGruenOl
      RP_IF_RGB_Slave_08_LedGruenStg_XIX_SAM: required-interface=IF_RGB_Slave_08_LedGruenStg
      RP_IF_RGB_Slave_08_LedRotOl_XIX_SAM: required-interface=IF_RGB_Slave_08_LedRotOl
      RP_IF_RGB_Slave_08_LedRotStg_XIX_SAM: required-interface=IF_RGB_Slave_08_LedRotStg
      RP_IF_RGB_Slave_08_ResponseError_XIX_SAM: required-interface=IF_RGB_Slave_08_ResponseError
      RP_IF_RGB_Slave_08_TempState_XIX_SAM: required-interface=IF_RGB_Slave_08_TempState
      RP_IF_RGB_Slave_09_IntErrorNvm_XIX_SAM: required-interface=IF_RGB_Slave_09_IntErrorNvm
      RP_IF_RGB_Slave_09_IntErrorRam_XIX_SAM: required-interface=IF_RGB_Slave_09_IntErrorRam
      RP_IF_RGB_Slave_09_IntErrorRom_XIX_SAM: required-interface=IF_RGB_Slave_09_IntErrorRom
      RP_IF_RGB_Slave_09_LedBlauOl_XIX_SAM: required-interface=IF_RGB_Slave_09_LedBlauOl
      RP_IF_RGB_Slave_09_LedBlauStg_XIX_SAM: required-interface=IF_RGB_Slave_09_LedBlauStg
      RP_IF_RGB_Slave_09_LedGruenOl_XIX_SAM: required-interface=IF_RGB_Slave_09_LedGruenOl
      RP_IF_RGB_Slave_09_LedGruenStg_XIX_SAM: required-interface=IF_RGB_Slave_09_LedGruenStg
      RP_IF_RGB_Slave_09_LedRotOl_XIX_SAM: required-interface=IF_RGB_Slave_09_LedRotOl
      RP_IF_RGB_Slave_09_LedRotStg_XIX_SAM: required-interface=IF_RGB_Slave_09_LedRotStg
      RP_IF_RGB_Slave_09_ResponseError_XIX_SAM: required-interface=IF_RGB_Slave_09_ResponseError
      RP_IF_RGB_Slave_09_TempState_XIX_SAM: required-interface=IF_RGB_Slave_09_TempState
      RP_IF_RGB_Slave_10_IntErrorNvm_XIX_SAM: required-interface=IF_RGB_Slave_10_IntErrorNvm
      RP_IF_RGB_Slave_10_IntErrorRam_XIX_SAM: required-interface=IF_RGB_Slave_10_IntErrorRam
      RP_IF_RGB_Slave_10_IntErrorRom_XIX_SAM: required-interface=IF_RGB_Slave_10_IntErrorRom
      RP_IF_RGB_Slave_10_LedBlauOl_XIX_SAM: required-interface=IF_RGB_Slave_10_LedBlauOl
      RP_IF_RGB_Slave_10_LedBlauStg_XIX_SAM: required-interface=IF_RGB_Slave_10_LedBlauStg
      RP_IF_RGB_Slave_10_LedGruenOl_XIX_SAM: required-interface=IF_RGB_Slave_10_LedGruenOl
      RP_IF_RGB_Slave_10_LedGruenStg_XIX_SAM: required-interface=IF_RGB_Slave_10_LedGruenStg
      RP_IF_RGB_Slave_10_LedRotOl_XIX_SAM: required-interface=IF_RGB_Slave_10_LedRotOl
      RP_IF_RGB_Slave_10_LedRotStg_XIX_SAM: required-interface=IF_RGB_Slave_10_LedRotStg
      RP_IF_RGB_Slave_10_ResponseError_XIX_SAM: required-interface=IF_RGB_Slave_10_ResponseError
      RP_IF_RGB_Slave_10_TempState_XIX_SAM: required-interface=IF_RGB_Slave_10_TempState
      RP_IF_RGB_Slave_11_IntErrorNvm_XIX_SAM: required-interface=IF_RGB_Slave_11_IntErrorNvm
      RP_IF_RGB_Slave_11_IntErrorRam_XIX_SAM: required-interface=IF_RGB_Slave_11_IntErrorRam
      RP_IF_RGB_Slave_11_IntErrorRom_XIX_SAM: required-interface=IF_RGB_Slave_11_IntErrorRom
      RP_IF_RGB_Slave_11_LedBlauOl_XIX_SAM: required-interface=IF_RGB_Slave_11_LedBlauOl
      RP_IF_RGB_Slave_11_LedBlauStg_XIX_SAM: required-interface=IF_RGB_Slave_11_LedBlauStg
      RP_IF_RGB_Slave_11_LedGruenOl_XIX_SAM: required-interface=IF_RGB_Slave_11_LedGruenOl
      RP_IF_RGB_Slave_11_LedGruenStg_XIX_SAM: required-interface=IF_RGB_Slave_11_LedGruenStg
      RP_IF_RGB_Slave_11_LedRotOl_XIX_SAM: required-interface=IF_RGB_Slave_11_LedRotOl
      RP_IF_RGB_Slave_11_LedRotStg_XIX_SAM: required-interface=IF_RGB_Slave_11_LedRotStg
      RP_IF_RGB_Slave_11_ResponseError_XIX_SAM: required-interface=IF_RGB_Slave_11_ResponseError
      RP_IF_RGB_Slave_11_TempState_XIX_SAM: required-interface=IF_RGB_Slave_11_TempState
      RP_IF_RGB_Slave_12_IntErrorNvm_XIX_SAM: required-interface=IF_RGB_Slave_12_IntErrorNvm
      RP_IF_RGB_Slave_12_IntErrorRam_XIX_SAM: required-interface=IF_RGB_Slave_12_IntErrorRam
      RP_IF_RGB_Slave_12_IntErrorRom_XIX_SAM: required-interface=IF_RGB_Slave_12_IntErrorRom
      RP_IF_RGB_Slave_12_LedBlauOl_XIX_SAM: required-interface=IF_RGB_Slave_12_LedBlauOl
      RP_IF_RGB_Slave_12_LedBlauStg_XIX_SAM: required-interface=IF_RGB_Slave_12_LedBlauStg
      RP_IF_RGB_Slave_12_LedGruenOl_XIX_SAM: required-interface=IF_RGB_Slave_12_LedGruenOl
      RP_IF_RGB_Slave_12_LedGruenStg_XIX_SAM: required-interface=IF_RGB_Slave_12_LedGruenStg
      RP_IF_RGB_Slave_12_LedRotOl_XIX_SAM: required-interface=IF_RGB_Slave_12_LedRotOl
      RP_IF_RGB_Slave_12_LedRotStg_XIX_SAM: required-interface=IF_RGB_Slave_12_LedRotStg
      RP_IF_RGB_Slave_12_ResponseError_XIX_SAM: required-interface=IF_RGB_Slave_12_ResponseError
      RP_IF_RGB_Slave_12_TempState_XIX_SAM: required-interface=IF_RGB_Slave_12_TempState
      RP_IF_RGB_Slave_13_IntErrorNvm_XIX_SAM: required-interface=IF_RGB_Slave_13_IntErrorNvm
      RP_IF_RGB_Slave_13_IntErrorRam_XIX_SAM: required-interface=IF_RGB_Slave_13_IntErrorRam
      RP_IF_RGB_Slave_13_IntErrorRom_XIX_SAM: required-interface=IF_RGB_Slave_13_IntErrorRom
      RP_IF_RGB_Slave_13_LedBlauOl_XIX_SAM: required-interface=IF_RGB_Slave_13_LedBlauOl
      RP_IF_RGB_Slave_13_LedBlauStg_XIX_SAM: required-interface=IF_RGB_Slave_13_LedBlauStg
      RP_IF_RGB_Slave_13_LedGruenOl_XIX_SAM: required-interface=IF_RGB_Slave_13_LedGruenOl
      RP_IF_RGB_Slave_13_LedGruenStg_XIX_SAM: required-interface=IF_RGB_Slave_13_LedGruenStg
      RP_IF_RGB_Slave_13_LedRotOl_XIX_SAM: required-interface=IF_RGB_Slave_13_LedRotOl
      RP_IF_RGB_Slave_13_LedRotStg_XIX_SAM: required-interface=IF_RGB_Slave_13_LedRotStg
      RP_IF_RGB_Slave_13_ResponseError_XIX_SAM: required-interface=IF_RGB_Slave_13_ResponseError
      RP_IF_RGB_Slave_13_TempState_XIX_SAM: required-interface=IF_RGB_Slave_13_TempState
      RP_IF_RGB_Slave_14_IntErrorNvm_XIX_SAM: required-interface=IF_RGB_Slave_14_IntErrorNvm
      RP_IF_RGB_Slave_14_IntErrorRam_XIX_SAM: required-interface=IF_RGB_Slave_14_IntErrorRam
      RP_IF_RGB_Slave_14_IntErrorRom_XIX_SAM: required-interface=IF_RGB_Slave_14_IntErrorRom
      RP_IF_RGB_Slave_14_LedBlauOl_XIX_SAM: required-interface=IF_RGB_Slave_14_LedBlauOl
      RP_IF_RGB_Slave_14_LedBlauStg_XIX_SAM: required-interface=IF_RGB_Slave_14_LedBlauStg
      RP_IF_RGB_Slave_14_LedGruenOl_XIX_SAM: required-interface=IF_RGB_Slave_14_LedGruenOl
      RP_IF_RGB_Slave_14_LedGruenStg_XIX_SAM: required-interface=IF_RGB_Slave_14_LedGruenStg
      RP_IF_RGB_Slave_14_LedRotOl_XIX_SAM: required-interface=IF_RGB_Slave_14_LedRotOl
      RP_IF_RGB_Slave_14_LedRotStg_XIX_SAM: required-interface=IF_RGB_Slave_14_LedRotStg
      RP_IF_RGB_Slave_14_ResponseError_XIX_SAM: required-interface=IF_RGB_Slave_14_ResponseError
      RP_IF_RGB_Slave_14_TempState_XIX_SAM: required-interface=IF_RGB_Slave_14_TempState
      RP_IF_RGB_Slave_15_IntErrorNvm_XIX_SAM: required-interface=IF_RGB_Slave_15_IntErrorNvm
      RP_IF_RGB_Slave_15_IntErrorRam_XIX_SAM: required-interface=IF_RGB_Slave_15_IntErrorRam
      RP_IF_RGB_Slave_15_IntErrorRom_XIX_SAM: required-interface=IF_RGB_Slave_15_IntErrorRom
      RP_IF_RGB_Slave_15_LedBlauOl_XIX_SAM: required-interface=IF_RGB_Slave_15_LedBlauOl
      RP_IF_RGB_Slave_15_LedBlauStg_XIX_SAM: required-interface=IF_RGB_Slave_15_LedBlauStg
      RP_IF_RGB_Slave_15_LedGruenOl_XIX_SAM: required-interface=IF_RGB_Slave_15_LedGruenOl
      RP_IF_RGB_Slave_15_LedGruenStg_XIX_SAM: required-interface=IF_RGB_Slave_15_LedGruenStg
      RP_IF_RGB_Slave_15_LedRotOl_XIX_SAM: required-interface=IF_RGB_Slave_15_LedRotOl
      RP_IF_RGB_Slave_15_LedRotStg_XIX_SAM: required-interface=IF_RGB_Slave_15_LedRotStg
      RP_IF_RGB_Slave_15_ResponseError_XIX_SAM: required-interface=IF_RGB_Slave_15_ResponseError
      RP_IF_RGB_Slave_15_TempState_XIX_SAM: required-interface=IF_RGB_Slave_15_TempState
      RP_IF_RHP_Fahrzeughupe_Anf_XIX_SAM: required-interface=IF_RHP_Fahrzeughupe_Anf
      RP_IF_RLS_CRC_XIX_SAM: required-interface=IF_RLS_CRC
      RP_IF_RLS_Qualifizierungsbit_XIX_SAM: required-interface=IF_RLS_Qualifizierungsbit
      RP_IF_RLS_ResponseError_XIX_SAM: required-interface=IF_RLS_ResponseError
      RP_IF_RLS_Vorfeldhelligkeit_Boost_XIX_SAM: required-interface=IF_RLS_Vorfeldhelligkeit_Boost
      RP_IF_RLS_Zaehler_XIX_SAM: required-interface=IF_RLS_Zaehler
      RP_IF_RS_AdaptierungError_XIX_SAM: required-interface=IF_RS_AdaptierungError
      RP_IF_RS_Error_XIX_SAM: required-interface=IF_RS_Error
      RP_IF_RS_Regenfahrlicht_XIX_SAM: required-interface=IF_RS_Regenfahrlicht
      RP_IF_RS_Regenmenge_XIX_SAM: required-interface=IF_RS_Regenmenge
      RP_IF_RS_Schwall_XIX_SAM: required-interface=IF_RS_Schwall
      RP_IF_RS_Verglasung_schliessen_XIX_SAM: required-interface=IF_RS_Verglasung_schliessen
      RP_IF_RS_versParklage_Wischer_XIX_SAM: required-interface=IF_RS_versParklage_Wischer
      RP_IF_RS_Wischergeschwindigkeit_XIX_SAM: required-interface=IF_RS_Wischergeschwindigkeit
      RP_IF_RV_Reinigung_Anf_XIX_SAM: required-interface=IF_RV_Reinigung_Anf
      RP_IF_SAL_01_BZ_XIX_SAM: required-interface=IF_SAL_01_BZ
      RP_IF_SAL_01_CRC_XIX_SAM: required-interface=IF_SAL_01_CRC
      RP_IF_SAL_Ambex_CH_state_XIX_SAM: required-interface=IF_SAL_Ambex_CH_state
      RP_IF_SAL_Ambex_CH_time_XIX_SAM: required-interface=IF_SAL_Ambex_CH_time
      RP_IF_SAL_Ambex_LH_state_XIX_SAM: required-interface=IF_SAL_Ambex_LH_state
      RP_IF_SAL_Ambex_LH_time_XIX_SAM: required-interface=IF_SAL_Ambex_LH_time
      RP_IF_SAL_Ambex_Lichtsensor_ch_lh_ein_XIX_SAM: required-interface=IF_SAL_Ambex_Lichtsensor_ch_lh_ein
      RP_IF_SAL_Blinkerzyklus_L_XIX_SAM: required-interface=IF_SAL_Blinkerzyklus_L
      RP_IF_SAL_Blinkerzyklus_R_XIX_SAM: required-interface=IF_SAL_Blinkerzyklus_R
      RP_IF_SAL_BLK_L_Anf_XIX_SAM: required-interface=IF_SAL_BLK_L_Anf
      RP_IF_SAL_BLK_R_Anf_XIX_SAM: required-interface=IF_SAL_BLK_R_Anf
      RP_IF_SAL_Bremszyklus_XIX_SAM: required-interface=IF_SAL_Bremszyklus
      RP_IF_SAL_BRL_Anf_XIX_SAM: required-interface=IF_SAL_BRL_Anf
      RP_IF_SAL_CH_Anf_XIX_SAM: required-interface=IF_SAL_CH_Anf
      RP_IF_SAL_HGB_Anf_XIX_SAM: required-interface=IF_SAL_HGB_Anf
      RP_IF_SAL_Kl_15_vFzg_S_XIX_SAM: required-interface=IF_SAL_Kl_15_vFzg_S
      RP_IF_SAL_Kl_15_vFzg_XIX_SAM: required-interface=IF_SAL_Kl_15_vFzg
      RP_IF_SAL_Kl_15_XIX_SAM: required-interface=IF_SAL_Kl_15
      RP_IF_SAL_KL_50_5s_XIX_SAM: required-interface=IF_SAL_KL_50_5s
      RP_IF_SAL_KL_50_XIX_SAM: required-interface=IF_SAL_KL_50
      RP_IF_SAL_KL_75_vFzg_XIX_SAM: required-interface=IF_SAL_KL_75_vFzg
      RP_IF_SAL_Kl_75_XIX_SAM: required-interface=IF_SAL_Kl_75
      RP_IF_SAL_KL_75a_vFzg_XIX_SAM: required-interface=IF_SAL_KL_75a_vFzg
      RP_IF_SAL_KL_75a_XIX_SAM: required-interface=IF_SAL_KL_75a
      RP_IF_SAL_KZL_Anf_XIX_SAM: required-interface=IF_SAL_KZL_Anf
      RP_IF_SAL_LDS_Abblendlicht_Anf_XIX_SAM: required-interface=IF_SAL_LDS_Abblendlicht_Anf
      RP_IF_SAL_LDS_Assistenzfahrlicht_Anf_XIX_SAM: required-interface=IF_SAL_LDS_Assistenzfahrlicht_Anf
      RP_IF_SAL_LDS_Nullstellung_Anf_XIX_SAM: required-interface=IF_SAL_LDS_Nullstellung_Anf
      RP_IF_SAL_LDS_Standlicht_Anf_XIX_SAM: required-interface=IF_SAL_LDS_Standlicht_Anf
      RP_IF_SAL_LH_Anf_XIX_SAM: required-interface=IF_SAL_LH_Anf
      RP_IF_SAL_NSL_Anf_XIX_SAM: required-interface=IF_SAL_NSL_Anf
      RP_IF_SAL_PL_L_Anf_XIX_SAM: required-interface=IF_SAL_PL_L_Anf
      RP_IF_SAL_PL_R_Anf_XIX_SAM: required-interface=IF_SAL_PL_R_Anf
      RP_IF_SAL_RFL_Anf_XIX_SAM: required-interface=IF_SAL_RFL_Anf
      RP_IF_SAL_SL_Anf_XIX_SAM: required-interface=IF_SAL_SL_Anf
      RP_IF_SAL_WBT_Bel_XIX_SAM: required-interface=IF_SAL_WBT_Bel
      RP_IF_SC_PAO_OFF_Anf_XIX_SAM: required-interface=IF_SC_PAO_OFF_Anf
      RP_IF_SC_PAO_ON_Anf_XIX_SAM: required-interface=IF_SC_PAO_ON_Anf
      RP_IF_SI_BUS_{01..03}_XIX_SAM: required-interface=IF_SI_BUS_{01..03}
      RP_IF_SI_BUS_05_XIX_SAM: required-interface=IF_SI_BUS_05
      RP_IF_SI_BUS_06_XIX_SAM: required-interface=IF_SI_BUS_06
      RP_IF_SI_BUS_09_XIX_SAM: required-interface=IF_SI_BUS_09
      RP_IF_SI_BUS_10_XIX_SAM: required-interface=IF_SI_BUS_10
      RP_IF_SI_BUS_13_XIX_SAM: required-interface=IF_SI_BUS_13
      RP_IF_SI_BUS_14_XIX_SAM: required-interface=IF_SI_BUS_14
      RP_IF_SI_Bus_Identifikation_XIX_SAM: required-interface=IF_SI_Bus_Identifikation
      RP_IF_SI_NWDF_gueltig_XIX_SAM: required-interface=IF_SI_NWDF_gueltig
      RP_IF_SI_NWDF_XIX_SAM: required-interface=IF_SI_NWDF
      RP_IF_SI_P_Mode_gueltig_XIX_SAM: required-interface=IF_SI_P_Mode_gueltig
      RP_IF_SI_P_Mode_XIX_SAM: required-interface=IF_SI_P_Mode
      RP_IF_SI_QRS_Mode_XIX_SAM: required-interface=IF_SI_QRS_Mode
      RP_IF_SI_T_Mode_XIX_SAM: required-interface=IF_SI_T_Mode
      RP_IF_SI_T_Schutz_XIX_SAM: required-interface=IF_SI_T_Schutz
      RP_IF_SitzMem_HBFS_ORUData_XIX_SAM: required-interface=IF_SitzMem_HBFS_ORUData
      RP_IF_SitzMem_HBFS_ORUDataIndex_XIX_SAM: required-interface=IF_SitzMem_HBFS_ORUDataIndex
      RP_IF_SitzMem_HFS_ORUData_XIX_SAM: required-interface=IF_SitzMem_HFS_ORUData
      RP_IF_SitzMem_HFS_ORUDataIndex_XIX_SAM: required-interface=IF_SitzMem_HFS_ORUDataIndex
      RP_IF_SitzMemo_BFS_ORUData_XIX_SAM: required-interface=IF_SitzMemo_BFS_ORUData
      RP_IF_SitzMemo_BFS_ORUDataIndex_XIX_SAM: required-interface=IF_SitzMemo_BFS_ORUDataIndex
      RP_IF_SitzMemo_FS_ORUData_XIX_SAM: required-interface=IF_SitzMemo_FS_ORUData
      RP_IF_SitzMemo_FS_ORUDataIndex_XIX_SAM: required-interface=IF_SitzMemo_FS_ORUDataIndex
      RP_IF_SL2_APS_Taster_XIX_SAM: required-interface=IF_SL2_APS_Taster
      RP_IF_SL2_FAS_Profile_Taster_XIX_SAM: required-interface=IF_SL2_FAS_Profile_Taster
      RP_IF_SL2_ResponseError_XIX_SAM: required-interface=IF_SL2_ResponseError
      RP_IF_SL2_StatusSchalterleiste_XIX_SAM: required-interface=IF_SL2_StatusSchalterleiste
      RP_IF_SMLS_01_BZ_XIX_SAM: required-interface=IF_SMLS_01_BZ
      RP_IF_SMLS_01_CRC_XIX_SAM: required-interface=IF_SMLS_01_CRC
      RP_IF_SMLS_Hupe_XIX_SAM: required-interface=IF_SMLS_Hupe
      RP_IF_SMLS_ORUData_XIX_SAM: required-interface=IF_SMLS_ORUData
      RP_IF_SMLS_ORUDataIndex_XIX_SAM: required-interface=IF_SMLS_ORUDataIndex
      RP_IF_SOK_FoD_BCM1_Resp_Challenge_XIX_SAM: required-interface=IF_SOK_FoD_BCM1_Resp_Challenge
      RP_IF_SOK_ungeschuetzte_Zeit_XIX_SAM: required-interface=IF_SOK_ungeschuetzte_Zeit
      RP_IF_SOK_ZV_Rueck_HW_Challenge_XIX_SAM: required-interface=IF_SOK_ZV_Rueck_HW_Challenge
      RP_IF_SoSe_SunInt_2D_Li_XIX_SAM: required-interface=IF_SoSe_SunInt_2D_Li
      RP_IF_SoSe_SunInt_2D_Re_XIX_SAM: required-interface=IF_SoSe_SunInt_2D_Re
      RP_IF_SPR_BFS_CodierPinError_XIX_SAM: required-interface=IF_SPR_BFS_CodierPinError
      RP_IF_SPR_BFS_Kompressor_elFehler_XIX_SAM: required-interface=IF_SPR_BFS_Kompressor_elFehler
      RP_IF_SPR_BFS_Leck_erkannt_XIX_SAM: required-interface=IF_SPR_BFS_Leck_erkannt
      RP_IF_SPR_BFS_Lokal_aktiv_XIX_SAM: required-interface=IF_SPR_BFS_Lokal_aktiv
      RP_IF_SPR_BFS_Lordose_hoch_XIX_SAM: required-interface=IF_SPR_BFS_Lordose_hoch
      RP_IF_SPR_BFS_Lordose_runter_XIX_SAM: required-interface=IF_SPR_BFS_Lordose_runter
      RP_IF_SPR_BFS_Lordose_vor_XIX_SAM: required-interface=IF_SPR_BFS_Lordose_vor
      RP_IF_SPR_BFS_Lordose_zurueck_XIX_SAM: required-interface=IF_SPR_BFS_Lordose_zurueck
      RP_IF_SPR_BFS_Massage_Dauer_XIX_SAM: required-interface=IF_SPR_BFS_Massage_Dauer
      RP_IF_SPR_BFS_Massage_Int_XIX_SAM: required-interface=IF_SPR_BFS_Massage_Int
      RP_IF_SPR_BFS_Massage_Intens_Lehne_XIX_SAM: required-interface=IF_SPR_BFS_Massage_Intens_Lehne
      RP_IF_SPR_BFS_Massage_Intens_Sitz_XIX_SAM: required-interface=IF_SPR_BFS_Massage_Intens_Sitz
      RP_IF_SPR_BFS_Massage_Prg_erweitert_XIX_SAM: required-interface=IF_SPR_BFS_Massage_Prg_erweitert
      RP_IF_SPR_BFS_Massage_Prg_XIX_SAM: required-interface=IF_SPR_BFS_Massage_Prg
      RP_IF_SPR_BFS_MassageStatus_XIX_SAM: required-interface=IF_SPR_BFS_MassageStatus
      RP_IF_SPR_BFS_Massagetaster_inv_XIX_SAM: required-interface=IF_SPR_BFS_Massagetaster_inv
      RP_IF_SPR_BFS_MuFu_Fkt_vor_XIX_SAM: required-interface=IF_SPR_BFS_MuFu_Fkt_vor
      RP_IF_SPR_BFS_MuFu_Fkt_zurueck_XIX_SAM: required-interface=IF_SPR_BFS_MuFu_Fkt_zurueck
      RP_IF_SPR_BFS_PopUp_Request_XIX_SAM: required-interface=IF_SPR_BFS_PopUp_Request
      RP_IF_SPR_BFS_ResponseError_XIX_SAM: required-interface=IF_SPR_BFS_ResponseError
      RP_IF_SPR_BFS_SG_defekt_XIX_SAM: required-interface=IF_SPR_BFS_SG_defekt
      RP_IF_SPR_BFS_SWL_vor_XIX_SAM: required-interface=IF_SPR_BFS_SWL_vor
      RP_IF_SPR_BFS_SWL_zurueck_XIX_SAM: required-interface=IF_SPR_BFS_SWL_zurueck
      RP_IF_SPR_BFS_Systemtest_Status_XIX_SAM: required-interface=IF_SPR_BFS_Systemtest_Status
      RP_IF_SPR_BFS_Tasterfehler_Massage_XIX_SAM: required-interface=IF_SPR_BFS_Tasterfehler_Massage
      RP_IF_SPR_BFS_Tasterfehler_Mufu_auf_ab_XIX_SAM: required-interface=IF_SPR_BFS_Tasterfehler_Mufu_auf_ab
      RP_IF_SPR_BFS_Tasterfehler_Mufu_Ring_XIX_SAM: required-interface=IF_SPR_BFS_Tasterfehler_Mufu_Ring
      RP_IF_SPR_BFS_Tasterfehler_Mufu_v_z_XIX_SAM: required-interface=IF_SPR_BFS_Tasterfehler_Mufu_v_z
      RP_IF_SPR_BFS_Teller_inv_XIX_SAM: required-interface=IF_SPR_BFS_Teller_inv
      RP_IF_SPR_BFS_Ueberspannung_XIX_SAM: required-interface=IF_SPR_BFS_Ueberspannung
      RP_IF_SPR_BFS_Unterspannung_XIX_SAM: required-interface=IF_SPR_BFS_Unterspannung
      RP_IF_SPR_BFS_Verstellung_aktiv_XIX_SAM: required-interface=IF_SPR_BFS_Verstellung_aktiv
      RP_IF_SPR_BFS_Wellness_Status_XIX_SAM: required-interface=IF_SPR_BFS_Wellness_Status
      RP_IF_SPR_BFS_Wippe_inv_XIX_SAM: required-interface=IF_SPR_BFS_Wippe_inv
      RP_IF_SPR_FS_CodierPinError_XIX_SAM: required-interface=IF_SPR_FS_CodierPinError
      RP_IF_SPR_FS_Kompressor_elFehler_XIX_SAM: required-interface=IF_SPR_FS_Kompressor_elFehler
      RP_IF_SPR_FS_Leck_erkannt_XIX_SAM: required-interface=IF_SPR_FS_Leck_erkannt
      RP_IF_SPR_FS_Lokal_aktiv_XIX_SAM: required-interface=IF_SPR_FS_Lokal_aktiv
      RP_IF_SPR_FS_Lordose_hoch_XIX_SAM: required-interface=IF_SPR_FS_Lordose_hoch
      RP_IF_SPR_FS_Lordose_runter_XIX_SAM: required-interface=IF_SPR_FS_Lordose_runter
      RP_IF_SPR_FS_Lordose_vor_XIX_SAM: required-interface=IF_SPR_FS_Lordose_vor
      RP_IF_SPR_FS_Lordose_zurueck_XIX_SAM: required-interface=IF_SPR_FS_Lordose_zurueck
      RP_IF_SPR_FS_Massage_Dauer_XIX_SAM: required-interface=IF_SPR_FS_Massage_Dauer
      RP_IF_SPR_FS_Massage_Int_XIX_SAM: required-interface=IF_SPR_FS_Massage_Int
      RP_IF_SPR_FS_Massage_Intens_Lehne_XIX_SAM: required-interface=IF_SPR_FS_Massage_Intens_Lehne
      RP_IF_SPR_FS_Massage_Intens_Sitz_XIX_SAM: required-interface=IF_SPR_FS_Massage_Intens_Sitz
      RP_IF_SPR_FS_Massage_Prg_erweitert_XIX_SAM: required-interface=IF_SPR_FS_Massage_Prg_erweitert
      RP_IF_SPR_FS_Massage_Prg_XIX_SAM: required-interface=IF_SPR_FS_Massage_Prg
      RP_IF_SPR_FS_MassageStatus_XIX_SAM: required-interface=IF_SPR_FS_MassageStatus
      RP_IF_SPR_FS_Massagetaster_inv_XIX_SAM: required-interface=IF_SPR_FS_Massagetaster_inv
      RP_IF_SPR_FS_MuFu_Fkt_vor_XIX_SAM: required-interface=IF_SPR_FS_MuFu_Fkt_vor
      RP_IF_SPR_FS_MuFu_Fkt_zurueck_XIX_SAM: required-interface=IF_SPR_FS_MuFu_Fkt_zurueck
      RP_IF_SPR_FS_PopUp_Request_XIX_SAM: required-interface=IF_SPR_FS_PopUp_Request
      RP_IF_SPR_FS_ResponseError_XIX_SAM: required-interface=IF_SPR_FS_ResponseError
      RP_IF_SPR_FS_SG_defekt_XIX_SAM: required-interface=IF_SPR_FS_SG_defekt
      RP_IF_SPR_FS_SWL_vor_XIX_SAM: required-interface=IF_SPR_FS_SWL_vor
      RP_IF_SPR_FS_SWL_zurueck_XIX_SAM: required-interface=IF_SPR_FS_SWL_zurueck
      RP_IF_SPR_FS_Systemtest_Status_XIX_SAM: required-interface=IF_SPR_FS_Systemtest_Status
      RP_IF_SPR_FS_Tasterfehler_Massage_XIX_SAM: required-interface=IF_SPR_FS_Tasterfehler_Massage
      RP_IF_SPR_FS_Tasterfehler_Mufu_auf_ab_XIX_SAM: required-interface=IF_SPR_FS_Tasterfehler_Mufu_auf_ab
      RP_IF_SPR_FS_Tasterfehler_Mufu_Ring_XIX_SAM: required-interface=IF_SPR_FS_Tasterfehler_Mufu_Ring
      RP_IF_SPR_FS_Tasterfehler_Mufu_v_z_XIX_SAM: required-interface=IF_SPR_FS_Tasterfehler_Mufu_v_z
      RP_IF_SPR_FS_Teller_inv_XIX_SAM: required-interface=IF_SPR_FS_Teller_inv
      RP_IF_SPR_FS_Ueberspannung_XIX_SAM: required-interface=IF_SPR_FS_Ueberspannung
      RP_IF_SPR_FS_Unterspannung_XIX_SAM: required-interface=IF_SPR_FS_Unterspannung
      RP_IF_SPR_FS_Verstellung_aktiv_XIX_SAM: required-interface=IF_SPR_FS_Verstellung_aktiv
      RP_IF_SPR_FS_Wellness_Status_XIX_SAM: required-interface=IF_SPR_FS_Wellness_Status
      RP_IF_SPR_FS_Wippe_inv_XIX_SAM: required-interface=IF_SPR_FS_Wippe_inv
      RP_IF_SRL1_ORUData_XIX_SAM: required-interface=IF_SRL1_ORUData
      RP_IF_SRL1_ORUDataIndex_XIX_SAM: required-interface=IF_SRL1_ORUDataIndex
      RP_IF_SRL2_ORUData_XIX_SAM: required-interface=IF_SRL2_ORUData
      RP_IF_SRL2_ORUDataIndex_XIX_SAM: required-interface=IF_SRL2_ORUDataIndex
      RP_IF_SRL3_ORUData_XIX_SAM: required-interface=IF_SRL3_ORUData
      RP_IF_SRL3_ORUDataIndex_XIX_SAM: required-interface=IF_SRL3_ORUDataIndex
      RP_IF_SRL4_ORUData_XIX_SAM: required-interface=IF_SRL4_ORUData
      RP_IF_SRL4_ORUDataIndex_XIX_SAM: required-interface=IF_SRL4_ORUDataIndex
      RP_IF_SRL5_ORUData_XIX_SAM: required-interface=IF_SRL5_ORUData
      RP_IF_SRL5_ORUDataIndex_XIX_SAM: required-interface=IF_SRL5_ORUDataIndex
      RP_IF_SRL6_ORUData_XIX_SAM: required-interface=IF_SRL6_ORUData
      RP_IF_SRL6_ORUDataIndex_XIX_SAM: required-interface=IF_SRL6_ORUDataIndex
      RP_IF_SRL_HL_01_BZ_XIX_SAM: required-interface=IF_SRL_HL_01_BZ
      RP_IF_SRL_HL_01_CRC_XIX_SAM: required-interface=IF_SRL_HL_01_CRC
      RP_IF_SRL_HR_01_BZ_XIX_SAM: required-interface=IF_SRL_HR_01_BZ
      RP_IF_SRL_HR_01_CRC_XIX_SAM: required-interface=IF_SRL_HR_01_CRC
      RP_IF_SRL_SL_01_BZ_XIX_SAM: required-interface=IF_SRL_SL_01_BZ
      RP_IF_SRL_SL_01_CRC_XIX_SAM: required-interface=IF_SRL_SL_01_CRC
      RP_IF_SRL_SR_01_BZ_XIX_SAM: required-interface=IF_SRL_SR_01_BZ
      RP_IF_SRL_SR_01_CRC_XIX_SAM: required-interface=IF_SRL_SR_01_CRC
      RP_IF_SRL_VL_01_BZ_XIX_SAM: required-interface=IF_SRL_VL_01_BZ
      RP_IF_SRL_VL_01_CRC_XIX_SAM: required-interface=IF_SRL_VL_01_CRC
      RP_IF_SRL_VR_01_BZ_XIX_SAM: required-interface=IF_SRL_VR_01_BZ
      RP_IF_SRL_VR_01_CRC_XIX_SAM: required-interface=IF_SRL_VR_01_CRC
      RP_IF_STSG_HBFS_AD_oeffnen_Anf_XIX_SAM: required-interface=IF_STSG_HBFS_AD_oeffnen_Anf
      RP_IF_STSG_HBFS_Bew_auf_XIX_SAM: required-interface=IF_STSG_HBFS_Bew_auf
      RP_IF_STSG_HBFS_Bew_zu_XIX_SAM: required-interface=IF_STSG_HBFS_Bew_zu
      RP_IF_STSG_HBFS_BTF_XIX_SAM: required-interface=IF_STSG_HBFS_BTF
      RP_IF_STSG_HBFS_entriegeln_anfordern_XIX_SAM: required-interface=IF_STSG_HBFS_entriegeln_anfordern
      RP_IF_STSG_HBFS_LKKS_Bereich_XIX_SAM: required-interface=IF_STSG_HBFS_LKKS_Bereich
      RP_IF_STSG_HBFS_ORUData_XIX_SAM: required-interface=IF_STSG_HBFS_ORUData
      RP_IF_STSG_HBFS_ORUDataIndex_XIX_SAM: required-interface=IF_STSG_HBFS_ORUDataIndex
      RP_IF_STSG_HBFS_ST_deaktivieren_XIX_SAM: required-interface=IF_STSG_HBFS_ST_deaktivieren
      RP_IF_STSG_HBFS_TAT_XIX_SAM: required-interface=IF_STSG_HBFS_TAT
      RP_IF_STSG_HFS_AD_oeffnen_Anf_XIX_SAM: required-interface=IF_STSG_HFS_AD_oeffnen_Anf
      RP_IF_STSG_HFS_Bew_auf_XIX_SAM: required-interface=IF_STSG_HFS_Bew_auf
      RP_IF_STSG_HFS_Bew_zu_XIX_SAM: required-interface=IF_STSG_HFS_Bew_zu
      RP_IF_STSG_HFS_BTF_XIX_SAM: required-interface=IF_STSG_HFS_BTF
      RP_IF_STSG_HFS_entriegeln_anforderen_XIX_SAM: required-interface=IF_STSG_HFS_entriegeln_anforderen
      RP_IF_STSG_HFS_LKKS_Bereich_XIX_SAM: required-interface=IF_STSG_HFS_LKKS_Bereich
      RP_IF_STSG_HFS_ORUData_XIX_SAM: required-interface=IF_STSG_HFS_ORUData
      RP_IF_STSG_HFS_ORUDataIndex_XIX_SAM: required-interface=IF_STSG_HFS_ORUDataIndex
      RP_IF_STSG_HFS_ST_deaktivieren_XIX_SAM: required-interface=IF_STSG_HFS_ST_deaktivieren
      RP_IF_STSG_HFS_TAT_XIX_SAM: required-interface=IF_STSG_HFS_TAT
      RP_IF_TSG_BFS_ORUData_XIX_SAM: required-interface=IF_TSG_BFS_ORUData
      RP_IF_TSG_BFS_ORUDataIndex_XIX_SAM: required-interface=IF_TSG_BFS_ORUDataIndex
      RP_IF_TSG_FS_ORUData_XIX_SAM: required-interface=IF_TSG_FS_ORUData
      RP_IF_TSG_FS_ORUDataIndex_XIX_SAM: required-interface=IF_TSG_FS_ORUDataIndex
      RP_IF_TSG_FT_02_BZ_XIX_SAM: required-interface=IF_TSG_FT_02_BZ
      RP_IF_TSG_FT_02_CRC_XIX_SAM: required-interface=IF_TSG_FT_02_CRC
      RP_IF_TSG_HBFS_ORUData_XIX_SAM: required-interface=IF_TSG_HBFS_ORUData
      RP_IF_TSG_HBFS_ORUDataIndex_XIX_SAM: required-interface=IF_TSG_HBFS_ORUDataIndex
      RP_IF_TSG_HFS_ORUData_XIX_SAM: required-interface=IF_TSG_HFS_ORUData
      RP_IF_TSG_HFS_ORUDataIndex_XIX_SAM: required-interface=IF_TSG_HFS_ORUDataIndex
      RP_IF_Tuerkontakt_Innenlicht_Taste_XIX_SAM: required-interface=IF_Tuerkontakt_Innenlicht_Taste
      RP_IF_UGDO_Failure_Antenne_XIX_SAM: required-interface=IF_UGDO_Failure_Antenne
      RP_IF_UGDO_Failure_Codierung_XIX_SAM: required-interface=IF_UGDO_Failure_Codierung
      RP_IF_UGDO_Failure_Hardware_XIX_SAM: required-interface=IF_UGDO_Failure_Hardware
      RP_IF_UGDO_Function_01_XIX_SAM: required-interface=IF_UGDO_Function_01
      RP_IF_UGDO_LED_Code_01_XIX_SAM: required-interface=IF_UGDO_LED_Code_01
      RP_IF_UGDO_ResponseError_XIX_SAM: required-interface=IF_UGDO_ResponseError
      RP_IF_UH_Jahr_XIX_SAM: required-interface=IF_UH_Jahr
      RP_IF_UH_Minute_XIX_SAM: required-interface=IF_UH_Minute
      RP_IF_UH_Monat_XIX_SAM: required-interface=IF_UH_Monat
      RP_IF_UH_Sekunde_XIX_SAM: required-interface=IF_UH_Sekunde
      RP_IF_UH_Stunde_XIX_SAM: required-interface=IF_UH_Stunde
      RP_IF_UH_Tag_XIX_SAM: required-interface=IF_UH_Tag
      RP_IF_UHF_01_Data_XIX_SAM: required-interface=IF_UHF_01_Data
      RP_IF_UHF_01_Datenlaenge_XIX_SAM: required-interface=IF_UHF_01_Datenlaenge
      RP_IF_UHF_01_Status_XIX_SAM: required-interface=IF_UHF_01_Status
      RP_IF_UHF_01_Typ_XIX_SAM: required-interface=IF_UHF_01_Typ
      RP_IF_UHF_01_Zaehler_XIX_SAM: required-interface=IF_UHF_01_Zaehler
      RP_IF_UHF_02_Data_XIX_SAM: required-interface=IF_UHF_02_Data
      RP_IF_UHF_02_Zaehler_XIX_SAM: required-interface=IF_UHF_02_Zaehler
      RP_IF_UHF_03_Data_XIX_SAM: required-interface=IF_UHF_03_Data
      RP_IF_UHF_03_Zaehler_XIX_SAM: required-interface=IF_UHF_03_Zaehler
      RP_IF_UHF_04_Data_XIX_SAM: required-interface=IF_UHF_04_Data
      RP_IF_UHF_04_Zaehler_XIX_SAM: required-interface=IF_UHF_04_Zaehler
      RP_IF_UHF_05_Data_XIX_SAM: required-interface=IF_UHF_05_Data
      RP_IF_UHF_05_Zaehler_XIX_SAM: required-interface=IF_UHF_05_Zaehler
      RP_IF_UHF_06_Data_XIX_SAM: required-interface=IF_UHF_06_Data
      RP_IF_UHF_06_Zaehler_XIX_SAM: required-interface=IF_UHF_06_Zaehler
      RP_IF_UHF_07_Data_XIX_SAM: required-interface=IF_UHF_07_Data
      RP_IF_UHF_07_Zaehler_XIX_SAM: required-interface=IF_UHF_07_Zaehler
      RP_IF_UHF_08_Data_XIX_SAM: required-interface=IF_UHF_08_Data
      RP_IF_UHF_08_Zaehler_XIX_SAM: required-interface=IF_UHF_08_Zaehler
      RP_IF_UHF_FFB_Funkschluesseltyp_XIX_SAM: required-interface=IF_UHF_FFB_Funkschluesseltyp
      RP_IF_UHF_FFB_SKC_anlernen_XIX_SAM: required-interface=IF_UHF_FFB_SKC_anlernen
      RP_IF_UHF_Konfig_Auswahl_Kanal_XIX_SAM: required-interface=IF_UHF_Konfig_Auswahl_Kanal
      RP_IF_UHF_Konfig_Auswahl_Kessymodus_XIX_SAM: required-interface=IF_UHF_Konfig_Auswahl_Kessymodus
      RP_IF_UHF_Konfig_Auswahl_naechst_Kanal_XIX_SAM: required-interface=IF_UHF_Konfig_Auswahl_naechst_Kanal
      RP_IF_UHF_Konfig_FFB_Freigabe_XIX_SAM: required-interface=IF_UHF_Konfig_FFB_Freigabe
      RP_IF_UHF_Konfig_Kanal_Umschaltzeit_XIX_SAM: required-interface=IF_UHF_Konfig_Kanal_Umschaltzeit
      RP_IF_UHF_Konfig_Praeambellaenge_XIX_SAM: required-interface=IF_UHF_Konfig_Praeambellaenge
      RP_IF_UHF_Konfig_Zaehler_XIX_SAM: required-interface=IF_UHF_Konfig_Zaehler
      RP_IF_UHF_TranspID_{01..08}_XIX_SAM: required-interface=IF_UHF_TranspID_{01..08}
      RP_IF_VIN_01_MUX_XIX_SAM: required-interface=IF_VIN_01_MUX
      RP_IF_VIN_{10..17}_XIX_SAM: required-interface=IF_VIN_{10..17}
      RP_IF_VIN_{1..9}_XIX_SAM: required-interface=IF_VIN_{1..9}
      RP_IF_VIP_Sensor_betaetigt_XIX_SAM: required-interface=IF_VIP_Sensor_betaetigt
      RP_IF_VIP_Sensor_STSG_HBFS_betaetigt_XIX_SAM: required-interface=IF_VIP_Sensor_STSG_HBFS_betaetigt
      RP_IF_VIP_Sensor_STSG_HFS_betaetigt_XIX_SAM: required-interface=IF_VIP_Sensor_STSG_HFS_betaetigt
      RP_IF_VMM_02_BZ_XIX_SAM: required-interface=IF_VMM_02_BZ
      RP_IF_VMM_02_CRC_XIX_SAM: required-interface=IF_VMM_02_CRC
      RP_IF_WFS_ID_Geb_autorisiert_in_Kl15_XIX_SAM: required-interface=IF_WFS_ID_Geb_autorisiert_in_Kl15
      RP_IF_WFS_Schluessel_Fahrberecht_XIX_SAM: required-interface=IF_WFS_Schluessel_Fahrberecht
      RP_IF_WH_Frontwaschen_XIX_SAM: required-interface=IF_WH_Frontwaschen
      RP_IF_WH_Heckintervall_XIX_SAM: required-interface=IF_WH_Heckintervall
      RP_IF_WH_Heckwaschen_XIX_SAM: required-interface=IF_WH_Heckwaschen
      RP_IF_WH_Intervall_XIX_SAM: required-interface=IF_WH_Intervall
      RP_IF_WH_Intervallstufen_XIX_SAM: required-interface=IF_WH_Intervallstufen
      RP_IF_WH_MFA_Fehler_XIX_SAM: required-interface=IF_WH_MFA_Fehler
      RP_IF_WH_Tipwischen_XIX_SAM: required-interface=IF_WH_Tipwischen
      RP_IF_WH_Wischer_Fehler_XIX_SAM: required-interface=IF_WH_Wischer_Fehler
      RP_IF_WH_WischerStufe1_invers_XIX_SAM: required-interface=IF_WH_WischerStufe1_invers
      RP_IF_WH_WischerStufe1_XIX_SAM: required-interface=IF_WH_WischerStufe1
      RP_IF_WH_WischerStufe2_invers_XIX_SAM: required-interface=IF_WH_WischerStufe2_invers
      RP_IF_WH_WischerStufe2_XIX_SAM: required-interface=IF_WH_WischerStufe2
      RP_IF_Wischer1_Error_XIX_SAM: required-interface=IF_Wischer1_Error
      RP_IF_Wischer1_ErrorGueltigkeit_XIX_SAM: required-interface=IF_Wischer1_ErrorGueltigkeit
      RP_IF_Wischer1_Ueberlast_XIX_SAM: required-interface=IF_Wischer1_Ueberlast
      RP_IF_Wischer2_Error_XIX_SAM: required-interface=IF_Wischer2_Error
      RP_IF_Wischer2_ErrorGueltigkeit_XIX_SAM: required-interface=IF_Wischer2_ErrorGueltigkeit
      RP_IF_Wischer2_Ueberlast_XIX_SAM: required-interface=IF_Wischer2_Ueberlast
      RP_IF_Wischer_aktiv_XIX_SAM: required-interface=IF_Wischer_aktiv
      RP_IF_Wischer_Parklage_XIX_SAM: required-interface=IF_Wischer_Parklage
      RP_IF_Wischer_ResponseError_XIX_SAM: required-interface=IF_Wischer_ResponseError
      RP_IF_Wischer_Servicestellung_XIX_SAM: required-interface=IF_Wischer_Servicestellung
      RP_IF_Wischer_Wendelage_XIX_SAM: required-interface=IF_Wischer_Wendelage
      RP_IF_Wischzykluszaehler_XIX_SAM: required-interface=IF_Wischzykluszaehler
      RP_IF_WWS2_aktiv_XIX_SAM: required-interface=IF_WWS2_aktiv
      RP_IF_WWS2_Error_XIX_SAM: required-interface=IF_WWS2_Error
      RP_IF_WWS2_ErrorGueltigkeit_XIX_SAM: required-interface=IF_WWS2_ErrorGueltigkeit
      RP_IF_WWS2_Parklage_XIX_SAM: required-interface=IF_WWS2_Parklage
      RP_IF_WWS2_Position_Wischerarm_XIX_SAM: required-interface=IF_WWS2_Position_Wischerarm
      RP_IF_WWS2_ResponseError_XIX_SAM: required-interface=IF_WWS2_ResponseError
      RP_IF_WWS2_Servicestellung_XIX_SAM: required-interface=IF_WWS2_Servicestellung
      RP_IF_WWS2_Ueberlast_XIX_SAM: required-interface=IF_WWS2_Ueberlast
      RP_IF_WWS2_Wendelage_XIX_SAM: required-interface=IF_WWS2_Wendelage
      RP_IF_WWS_DebugData_XIX_SAM: required-interface=IF_WWS_DebugData
      RP_IF_WWS_Position_Wischerarm_XIX_SAM: required-interface=IF_WWS_Position_Wischerarm
      RP_IF_WWS_Produktionsmodus_Status_XIX_SAM: required-interface=IF_WWS_Produktionsmodus_Status
      RP_IF_WWS_Wischgeschwindigkeit_XIX_SAM: required-interface=IF_WWS_Wischgeschwindigkeit
      RP_IF_ZAS_Kl_15_XIX_SAM: required-interface=IF_ZAS_Kl_15
      RP_IF_ZAS_Kl_S_XIX_SAM: required-interface=IF_ZAS_Kl_S
      RP_IF_ZFH_HBFS_AutoHoch_XIX_SAM: required-interface=IF_ZFH_HBFS_AutoHoch
      RP_IF_ZFH_HBFS_AutoTief_XIX_SAM: required-interface=IF_ZFH_HBFS_AutoTief
      RP_IF_ZFH_HBFS_ManHoch_XIX_SAM: required-interface=IF_ZFH_HBFS_ManHoch
      RP_IF_ZFH_HBFS_ManTief_XIX_SAM: required-interface=IF_ZFH_HBFS_ManTief
      RP_IF_ZFH_HFS_AutoHoch_XIX_SAM: required-interface=IF_ZFH_HFS_AutoHoch
      RP_IF_ZFH_HFS_AutoTief_XIX_SAM: required-interface=IF_ZFH_HFS_AutoTief
      RP_IF_ZFH_HFS_ManHoch_XIX_SAM: required-interface=IF_ZFH_HFS_ManHoch
      RP_IF_ZFH_HFS_ManTief_XIX_SAM: required-interface=IF_ZFH_HFS_ManTief
      RP_IF_ZFH_zentral_auf_XIX_SAM: required-interface=IF_ZFH_zentral_auf
      RP_IF_ZFH_zentral_zu_XIX_SAM: required-interface=IF_ZFH_zentral_zu
      RP_IF_ZV_04_BZ_XIX_SAM: required-interface=IF_ZV_04_BZ
      RP_IF_ZV_04_CRC_XIX_SAM: required-interface=IF_ZV_04_CRC
      RP_IF_ZV_Anf_Challenge_Auth_XIX_SAM: required-interface=IF_ZV_Anf_Challenge_Auth
      RP_IF_ZV_auf_BT_XIX_SAM: required-interface=IF_ZV_auf_BT
      RP_IF_ZV_auf_FT_XIX_SAM: required-interface=IF_ZV_auf_FT
      RP_IF_ZV_auf_Funk_XIX_SAM: required-interface=IF_ZV_auf_Funk
      RP_IF_ZV_auf_Kessy_XIX_SAM: required-interface=IF_ZV_auf_Kessy
      RP_IF_ZV_Bedienstelle_auf_XIX_SAM: required-interface=IF_ZV_Bedienstelle_auf
      RP_IF_ZV_BT_offen_XIX_SAM: required-interface=IF_ZV_BT_offen
      RP_IF_ZV_DWA_Einfachhorn_Anf_XIX_SAM: required-interface=IF_ZV_DWA_Einfachhorn_Anf
      RP_IF_ZV_DWA_Einfachhorn_Takt_XIX_SAM: required-interface=IF_ZV_DWA_Einfachhorn_Takt
      RP_IF_ZV_Einfachhorn_Anf_XIX_SAM: required-interface=IF_ZV_Einfachhorn_Anf
      RP_IF_ZV_Einfachhorn_Takt_XIX_SAM: required-interface=IF_ZV_Einfachhorn_Takt
      RP_IF_ZV_FT_offen_XIX_SAM: required-interface=IF_ZV_FT_offen
      RP_IF_ZV_gesafet_extern_ist_XIX_SAM: required-interface=IF_ZV_gesafet_extern_ist
      RP_IF_ZV_gesafet_extern_soll_XIX_SAM: required-interface=IF_ZV_gesafet_extern_soll
      RP_IF_ZV_HBFS_entriegeln_Auth_XIX_SAM: required-interface=IF_ZV_HBFS_entriegeln_Auth
      RP_IF_ZV_HBFS_entriegeln_XIX_SAM: required-interface=IF_ZV_HBFS_entriegeln
      RP_IF_ZV_HBFS_entsafen_Auth_XIX_SAM: required-interface=IF_ZV_HBFS_entsafen_Auth
      RP_IF_ZV_HBFS_offen_XIX_SAM: required-interface=IF_ZV_HBFS_offen
      RP_IF_ZV_HBFS_verriegeln_XIX_SAM: required-interface=IF_ZV_HBFS_verriegeln
      RP_IF_ZV_HD_offen_XIX_SAM: required-interface=IF_ZV_HD_offen
      RP_IF_ZV_Heckeinzelentriegelung_XIX_SAM: required-interface=IF_ZV_Heckeinzelentriegelung
      RP_IF_ZV_HFS_entriegeln_Auth_XIX_SAM: required-interface=IF_ZV_HFS_entriegeln_Auth
      RP_IF_ZV_HFS_entriegeln_XIX_SAM: required-interface=IF_ZV_HFS_entriegeln
      RP_IF_ZV_HFS_entsafen_Auth_XIX_SAM: required-interface=IF_ZV_HFS_entsafen_Auth
      RP_IF_ZV_HFS_offen_XIX_SAM: required-interface=IF_ZV_HFS_offen
      RP_IF_ZV_HFS_verriegeln_XIX_SAM: required-interface=IF_ZV_HFS_verriegeln
      RP_IF_ZV_Hupe_Anf_XIX_SAM: required-interface=IF_ZV_Hupe_Anf
      RP_IF_ZV_Hupe_Takt_XIX_SAM: required-interface=IF_ZV_Hupe_Takt
      RP_IF_ZV_HW_Motor_Lock_HK_Auth_XIX_SAM: required-interface=IF_ZV_HW_Motor_Lock_HK_Auth
      RP_IF_ZV_HW_Motor_Lock_HK_XIX_SAM: required-interface=IF_ZV_HW_Motor_Lock_HK
      RP_IF_ZV_HW_Motor_Safe_Hinten_XIX_SAM: required-interface=IF_ZV_HW_Motor_Safe_Hinten
      RP_IF_ZV_ist_Zustand_verfuegbar_XIX_SAM: required-interface=IF_ZV_ist_Zustand_verfuegbar
      RP_IF_ZV_Laderaumabd_elektr_aktiviert_XIX_SAM: required-interface=IF_ZV_Laderaumabd_elektr_aktiviert
      RP_IF_ZV_Schluessel_Zugang_XIX_SAM: required-interface=IF_ZV_Schluessel_Zugang
      RP_IF_ZV_Status_Cargolock_XIX_SAM: required-interface=IF_ZV_Status_Cargolock
      RP_IF_ZV_STSG_HBFS_Anf_XIX_SAM: required-interface=IF_ZV_STSG_HBFS_Anf
      RP_IF_ZV_STSG_HFS_Anf_XIX_SAM: required-interface=IF_ZV_STSG_HFS_Anf
      RP_IF_ZV_verriegelt_extern_ist_XIX_SAM: required-interface=IF_ZV_verriegelt_extern_ist
      RP_IF_ZV_verriegelt_extern_soll_XIX_SAM: required-interface=IF_ZV_verriegelt_extern_soll
      RP_IF_ZV_verriegelt_intern_ist_XIX_SAM: required-interface=IF_ZV_verriegelt_intern_ist
      RP_IF_ZV_verriegelt_intern_soll_XIX_SAM: required-interface=IF_ZV_verriegelt_intern_soll
      RP_IF_ZV_zentral_entsafen_XIX_SAM: required-interface=IF_ZV_zentral_entsafen
      RP_IF_ZV_zentral_safen_XIX_SAM: required-interface=IF_ZV_zentral_safen
      RP_IF_ZV_zu_Funk_XIX_SAM: required-interface=IF_ZV_zu_Funk
      RP_IF_ZV_zu_Kessy_XIX_SAM: required-interface=IF_ZV_zu_Kessy
    13 x component:
      ABL_XIX_SAM: type=ABL_XIX_SAM
      Basis_Klima_XIX_SAM: type=Basis_Klima_XIX_SAM
      Dimmung_XIX_SAM: type=Dimmung_XIX_SAM
      Druckpunktmassage_fuer_Beifahrersitz_Lehnenmassage_SAM_XIX_DPMBFSLM_XIX_SAM: type=Druckpunktmassage_fuer_Beifahrersitz_Lehnenmassage_SAM_XIX_DPMBFSLM_XIX_SAM
      Druckpunktmassage_fuer_Fahrersitz_Lehnenmassage_SAM_XIX_DPMFSLM_XIX_SAM: type=Druckpunktmassage_fuer_Fahrersitz_Lehnenmassage_SAM_XIX_DPMFSLM_XIX_SAM
      Grundumfang_XIX_SAM: type=Grundumfang_XIX_SAM
      LWR_Auto_XIX_SAM: type=LWR_Auto_XIX_SAM
      SC_447_FoD_Slave_4_XIX_Softwareblock_XIX_SAM: type=SC_447_FoD_Slave_4_XIX_Softwareblock_XIX_SAM
      SC_708_IuALicht_MEB_XIX_Softwareblock_XIX_SAM: type=SC_708_IuALicht_MEB_XIX_Softwareblock_XIX_SAM
      SC_789_ExAmb_MEB_XIX_Softwareblock_XIX_SAM: type=SC_789_ExAmb_MEB_XIX_Softwareblock_XIX_SAM
      VIP_XIX_SAM: type=VIP_XIX_SAM
      VKMS_XIX_SAM: type=VKMS_XIX_SAM
      ZV_XIX_SAM: type=ZV_XIX_SAM
    delegate Grundumfang_XIX_SAM.RP_IF_AAG_Anhaenger_erkannt_XIX_Grundumfang_XIX_SAM <-> outer port RP_IF_AAG_Anhaenger_erkannt_XIX_SAM
    delegate VIP_XIX_SAM.RP_IF_AAG_Anhaenger_erkannt_XIX_VIP_XIX_SAM <-> outer port RP_IF_AAG_Anhaenger_erkannt_XIX_SAM
    delegate Grundumfang_XIX_SAM.RP_IF_AAG_ORUData_XIX_Grundumfang_XIX_SAM <-> outer port RP_IF_AAG_ORUData_XIX_SAM
    delegate Grundumfang_XIX_SAM.RP_IF_AAG_ORUDataIndex_XIX_Grundumfang_XIX_SAM <-> outer port RP_IF_AAG_ORUDataIndex_XIX_SAM
    delegate Druckpunktmassage_fuer_Fahrersitz_Lehnenmassage_SAM_XIX_DPMFSLM_XIX_SAM.RP_IF_AB_Belegung_VB_XIX_Druckpunktmassage_fuer_Fahrersitz_Lehnenmassage_SAM_XIX_DPMFSLM_XIX_SAM <-> outer port RP_IF_AB_Belegung_VB_XIX_SAM
    delegate Grundumfang_XIX_SAM.RP_IF_AB_Belegung_VB_XIX_Grundumfang_XIX_SAM <-> outer port RP_IF_AB_Belegung_VB_XIX_SAM
    delegate Grundumfang_XIX_SAM.RP_IF_AB_Crash_Int_XIX_Grundumfang_XIX_SAM <-> outer port RP_IF_AB_Crash_Int_XIX_SAM
    delegate Grundumfang_XIX_SAM.RP_IF_AB_Deaktivierung_HV_XIX_Grundumfang_XIX_SAM <-> outer port RP_IF_AB_Deaktivierung_HV_XIX_SAM
    delegate Grundumfang_XIX_SAM.RP_IF_AB_Front_Crash_XIX_Grundumfang_XIX_SAM <-> outer port RP_IF_AB_Front_Crash_XIX_SAM
    delegate Druckpunktmassage_fuer_Beifahrersitz_Lehnenmassage_SAM_XIX_DPMBFSLM_XIX_SAM.RP_IF_AB_Gurtschloss_BF_XIX_Druckpunktmassage_fuer_Beifahrersitz_Lehnenmassage_SAM_XIX_DPMBFSLM_XIX_SAM <-> outer port RP_IF_AB_Gurtschloss_BF_XIX_SAM  # _XIX_Grundumfang_XIX_Airbag_XIX_Druckpunktmassage_fuer_Beifahrersitz_Lehnenmassage_SAM_XIX_DPMBFSLM_XIX_SAM_XIX_AB_Gurtschloss_BF
    delegate Grundumfang_XIX_SAM.RP_IF_AB_Gurtschloss_BF_XIX_Grundumfang_XIX_SAM <-> outer port RP_IF_AB_Gurtschloss_BF_XIX_SAM
    delegate Druckpunktmassage_fuer_Fahrersitz_Lehnenmassage_SAM_XIX_DPMFSLM_XIX_SAM.RP_IF_AB_Gurtschloss_FA_XIX_Druckpunktmassage_fuer_Fahrersitz_Lehnenmassage_SAM_XIX_DPMFSLM_XIX_SAM <-> outer port RP_IF_AB_Gurtschloss_FA_XIX_SAM
    delegate Grundumfang_XIX_SAM.RP_IF_AB_Gurtschloss_FA_XIX_Grundumfang_XIX_SAM <-> outer port RP_IF_AB_Gurtschloss_FA_XIX_SAM
    delegate Grundumfang_XIX_SAM.RP_IF_AB_Heck_Crash_XIX_Grundumfang_XIX_SAM <-> outer port RP_IF_AB_Heck_Crash_XIX_SAM
    delegate Grundumfang_XIX_SAM.RP_IF_AB_Rollover_Crash_XIX_Grundumfang_XIX_SAM <-> outer port RP_IF_AB_Rollover_Crash_XIX_SAM
    delegate Grundumfang_XIX_SAM.RP_IF_AB_SB_Crash_XIX_Grundumfang_XIX_SAM <-> outer port RP_IF_AB_SB_Crash_XIX_SAM
    delegate Grundumfang_XIX_SAM.RP_IF_AB_SF_Crash_XIX_Grundumfang_XIX_SAM <-> outer port RP_IF_AB_SF_Crash_XIX_SAM
    delegate Grundumfang_XIX_SAM.RP_IF_ADecu1_01_BZ_XIX_Grundumfang_XIX_SAM <-> outer port RP_IF_ADecu1_01_BZ_XIX_SAM
    delegate Grundumfang_XIX_SAM.RP_IF_ADecu1_01_CRC_XIX_Grundumfang_XIX_SAM <-> outer port RP_IF_ADecu1_01_CRC_XIX_SAM
    delegate Grundumfang_XIX_SAM.RP_IF_ADecu1_ORUData_XIX_Grundumfang_XIX_SAM <-> outer port RP_IF_ADecu1_ORUData_XIX_SAM
    delegate Grundumfang_XIX_SAM.RP_IF_ADecu1_ORUDataIndex_XIX_Grundumfang_XIX_SAM <-> outer port RP_IF_ADecu1_ORUDataIndex_XIX_SAM
    delegate Grundumfang_XIX_SAM.RP_IF_ADecu2_01_BZ_XIX_Grundumfang_XIX_SAM <-> outer port RP_IF_ADecu2_01_BZ_XIX_SAM
    delegate Grundumfang_XIX_SAM.RP_IF_ADecu2_01_CRC_XIX_Grundumfang_XIX_SAM <-> outer port RP_IF_ADecu2_01_CRC_XIX_SAM
    delegate Grundumfang_XIX_SAM.RP_IF_ADecu2_ORUData_XIX_Grundumfang_XIX_SAM <-> outer port RP_IF_ADecu2_ORUData_XIX_SAM
    delegate Grundumfang_XIX_SAM.RP_IF_ADecu2_ORUDataIndex_XIX_Grundumfang_XIX_SAM <-> outer port RP_IF_ADecu2_ORUDataIndex_XIX_SAM
    delegate ZV_XIX_SAM.RP_IF_Airbag_01_BZ_XIX_ZV_XIX_SAM <-> outer port RP_IF_Airbag_01_BZ_XIX_SAM
    delegate ZV_XIX_SAM.RP_IF_Airbag_01_CRC_XIX_ZV_XIX_SAM <-> outer port RP_IF_Airbag_01_CRC_XIX_SAM
    delegate Grundumfang_XIX_SAM.RP_IF_Airbag_02_BZ_XIX_Grundumfang_XIX_SAM <-> outer port RP_IF_Airbag_02_BZ_XIX_SAM
    delegate Grundumfang_XIX_SAM.RP_IF_Airbag_02_CRC_XIX_Grundumfang_XIX_SAM <-> outer port RP_IF_Airbag_02_CRC_XIX_SAM
    delegate Grundumfang_XIX_SAM.RP_IF_Airbag_ORUData_XIX_Grundumfang_XIX_SAM <-> outer port RP_IF_Airbag_ORUData_XIX_SAM
    delegate Grundumfang_XIX_SAM.RP_IF_Airbag_ORUDataIndex_XIX_Grundumfang_XIX_SAM <-> outer port RP_IF_Airbag_ORUDataIndex_XIX_SAM
    delegate SC_708_IuALicht_MEB_XIX_Softwareblock_XIX_SAM.RP_IF_ASW_Warnung_aktiv_BFS_XIX_SC_708_IuALicht_MEB_XIX_Softwareblock_XIX_SAM <-> outer port RP_IF_ASW_Warnung_aktiv_BFS_XIX_SAM
    delegate SC_708_IuALicht_MEB_XIX_Softwareblock_XIX_SAM.RP_IF_ASW_Warnung_aktiv_FS_XIX_SC_708_IuALicht_MEB_XIX_Softwareblock_XIX_SAM <-> outer port RP_IF_ASW_Warnung_aktiv_FS_XIX_SAM
    delegate SC_708_IuALicht_MEB_XIX_Softwareblock_XIX_SAM.RP_IF_ASW_Warnung_aktiv_HBFS_XIX_SC_708_IuALicht_MEB_XIX_Softwareblock_XIX_SAM <-> outer port RP_IF_ASW_Warnung_aktiv_HBFS_XIX_SAM
    delegate SC_708_IuALicht_MEB_XIX_Softwareblock_XIX_SAM.RP_IF_ASW_Warnung_aktiv_HFS_XIX_SC_708_IuALicht_MEB_XIX_Softwareblock_XIX_SAM <-> outer port RP_IF_ASW_Warnung_aktiv_HFS_XIX_SAM
    delegate Grundumfang_XIX_SAM.RP_IF_BAPs_Data_Byte_{1..6}_XIX_Grundumfang_XIX_SAM <-> outer port RP_IF_BAPs_Data_Byte_{1..6}_XIX_SAM
    delegate Grundumfang_XIX_SAM.RP_IF_BAPs_FCT_ID_XIX_Grundumfang_XIX_SAM <-> outer port RP_IF_BAPs_FCT_ID_XIX_SAM
    delegate Grundumfang_XIX_SAM.RP_IF_BAPs_LSG_ID1_XIX_Grundumfang_XIX_SAM <-> outer port RP_IF_BAPs_LSG_ID1_XIX_SAM
    delegate Grundumfang_XIX_SAM.RP_IF_BAPs_LSG_ID2_XIX_Grundumfang_XIX_SAM <-> outer port RP_IF_BAPs_LSG_ID2_XIX_SAM
    delegate Grundumfang_XIX_SAM.RP_IF_BAPs_Opcode_XIX_Grundumfang_XIX_SAM <-> outer port RP_IF_BAPs_Opcode_XIX_SAM
    delegate Grundumfang_XIX_SAM.RP_IF_BAPs_Segment_XIX_Grundumfang_XIX_SAM <-> outer port RP_IF_BAPs_Segment_XIX_SAM
    delegate ABL_XIX_SAM.RP_IF_BCM1_CH_LH_aktiv_XIX_ABL_XIX_SAM <-> outer port RP_IF_BCM1_CH_LH_aktiv_XIX_SAM
    delegate ABL_XIX_SAM.RP_IF_BCM1_Nebelschluss_Fzg_Anf_XIX_ABL_XIX_SAM <-> outer port RP_IF_BCM1_Nebelschluss_Fzg_Anf_XIX_SAM
    delegate ABL_XIX_SAM.RP_IF_BCM1_Parklicht_li_Anf_XIX_ABL_XIX_SAM <-> outer port RP_IF_BCM1_Parklicht_li_Anf_XIX_SAM
    delegate Grundumfang_XIX_SAM.RP_IF_BCM1_Parklicht_li_Anf_XIX_Grundumfang_XIX_SAM <-> outer port RP_IF_BCM1_Parklicht_li_Anf_XIX_SAM
    delegate ABL_XIX_SAM.RP_IF_BCM1_Parklicht_re_Anf_XIX_ABL_XIX_SAM <-> outer port RP_IF_BCM1_Parklicht_re_Anf_XIX_SAM
    delegate Grundumfang_XIX_SAM.RP_IF_BCM1_Parklicht_re_Anf_XIX_Grundumfang_XIX_SAM <-> outer port RP_IF_BCM1_Parklicht_re_Anf_XIX_SAM
    delegate ABL_XIX_SAM.RP_IF_BCM1_Schlusslicht_Anf_XIX_ABL_XIX_SAM <-> outer port RP_IF_BCM1_Schlusslicht_Anf_XIX_SAM
    delegate ABL_XIX_SAM.RP_IF_BCM1_Standlicht_Anf_XIX_ABL_XIX_SAM <-> outer port RP_IF_BCM1_Standlicht_Anf_XIX_SAM
    delegate Grundumfang_XIX_SAM.RP_IF_BCM1_Standlicht_Anf_XIX_Grundumfang_XIX_SAM <-> outer port RP_IF_BCM1_Standlicht_Anf_XIX_SAM
    delegate ABL_XIX_SAM.RP_IF_BCM1_Umfeldleuchten_Anf_XIX_ABL_XIX_SAM <-> outer port RP_IF_BCM1_Umfeldleuchten_Anf_XIX_SAM
    delegate Grundumfang_XIX_SAM.RP_IF_BCM1_Umfeldleuchten_Anf_XIX_Grundumfang_XIX_SAM <-> outer port RP_IF_BCM1_Umfeldleuchten_Anf_XIX_SAM
    delegate Grundumfang_XIX_SAM.RP_IF_BCM_FH_Freigabe_XIX_Grundumfang_XIX_SAM <-> outer port RP_IF_BCM_FH_Freigabe_XIX_SAM
    delegate Grundumfang_XIX_SAM.RP_IF_BCM_Komfortfkt_Freigabe_XIX_Grundumfang_XIX_SAM <-> outer port RP_IF_BCM_Komfortfkt_Freigabe_XIX_SAM
    delegate ABL_XIX_SAM.RP_IF_BCM_Rueckfahrlicht_Anf_XIX_ABL_XIX_SAM <-> outer port RP_IF_BCM_Rueckfahrlicht_Anf_XIX_SAM
    delegate Grundumfang_XIX_SAM.RP_IF_Bel_DiETa_Mode_XIX_Grundumfang_XIX_SAM <-> outer port RP_IF_Bel_DiETa_Mode_XIX_SAM
    delegate Grundumfang_XIX_SAM.RP_IF_Bel_DiETa_Warnblinken_XIX_Grundumfang_XIX_SAM <-> outer port RP_IF_Bel_DiETa_Warnblinken_XIX_SAM
    delegate Druckpunktmassage_fuer_Beifahrersitz_Lehnenmassage_SAM_XIX_DPMBFSLM_XIX_SAM.RP_IF_BFS_MMB_glob_stop_XIX_Druckpunktmassage_fuer_Beifahrersitz_Lehnenmassage_SAM_XIX_DPMBFSLM_XIX_SAM <-> outer port RP_IF_BFS_MMB_glob_stop_XIX_SAM  # _XIX_Grundumfang_XIX_SitzMemo_BFS_XIX_Druckpunktmassage_fuer_Beifahrersitz_Lehnenmassage_SAM_XIX_DPMBFSLM_XIX_SAM_XIX_BFS_MMB_glob_stop
    delegate Druckpunktmassage_fuer_Fahrersitz_Lehnenmassage_SAM_XIX_DPMFSLM_XIX_SAM.RP_IF_BFS_MMB_glob_stop_XIX_Druckpunktmassage_fuer_Fahrersitz_Lehnenmassage_SAM_XIX_DPMFSLM_XIX_SAM <-> outer port RP_IF_BFS_MMB_glob_stop_XIX_SAM  # _XIX_Grundumfang_XIX_SitzMemo_BFS_XIX_Druckpunktmassage_fuer_Fahrersitz_Lehnenmassage_SAM_XIX_DPMFSLM_XIX_SAM_XIX_BFS_MMB_glob_stop
    delegate Grundumfang_XIX_SAM.RP_IF_BFS_MMB_glob_stop_XIX_Grundumfang_XIX_SAM <-> outer port RP_IF_BFS_MMB_glob_stop_XIX_SAM
    delegate Druckpunktmassage_fuer_Beifahrersitz_Lehnenmassage_SAM_XIX_DPMBFSLM_XIX_SAM.RP_IF_BFS_MMB_storage_XIX_Druckpunktmassage_fuer_Beifahrersitz_Lehnenmassage_SAM_XIX_DPMBFSLM_XIX_SAM <-> outer port RP_IF_BFS_MMB_storage_XIX_SAM  # _XIX_Grundumfang_XIX_SitzMemo_BFS_XIX_Druckpunktmassage_fuer_Beifahrersitz_Lehnenmassage_SAM_XIX_DPMBFSLM_XIX_SAM_XIX_BFS_MMB_storage
    delegate Druckpunktmassage_fuer_Fahrersitz_Lehnenmassage_SAM_XIX_DPMFSLM_XIX_SAM.RP_IF_BFS_MMB_storage_XIX_Druckpunktmassage_fuer_Fahrersitz_Lehnenmassage_SAM_XIX_DPMFSLM_XIX_SAM <-> outer port RP_IF_BFS_MMB_storage_XIX_SAM  # _XIX_Grundumfang_XIX_SitzMemo_BFS_XIX_Druckpunktmassage_fuer_Fahrersitz_Lehnenmassage_SAM_XIX_DPMFSLM_XIX_SAM_XIX_BFS_MMB_storage
    delegate Grundumfang_XIX_SAM.RP_IF_BFS_MMB_storage_XIX_Grundumfang_XIX_SAM <-> outer port RP_IF_BFS_MMB_storage_XIX_SAM
    delegate Druckpunktmassage_fuer_Beifahrersitz_Lehnenmassage_SAM_XIX_DPMBFSLM_XIX_SAM.RP_IF_BFS_MMB_tast_XIX_Druckpunktmassage_fuer_Beifahrersitz_Lehnenmassage_SAM_XIX_DPMBFSLM_XIX_SAM <-> outer port RP_IF_BFS_MMB_tast_XIX_SAM  # _XIX_Grundumfang_XIX_SitzMemo_BFS_XIX_Druckpunktmassage_fuer_Beifahrersitz_Lehnenmassage_SAM_XIX_DPMBFSLM_XIX_SAM_XIX_BFS_MMB_tast
    delegate Druckpunktmassage_fuer_Fahrersitz_Lehnenmassage_SAM_XIX_DPMFSLM_XIX_SAM.RP_IF_BFS_MMB_tast_XIX_Druckpunktmassage_fuer_Fahrersitz_Lehnenmassage_SAM_XIX_DPMFSLM_XIX_SAM <-> outer port RP_IF_BFS_MMB_tast_XIX_SAM
    delegate Grundumfang_XIX_SAM.RP_IF_BFS_MMB_tast_XIX_Grundumfang_XIX_SAM <-> outer port RP_IF_BFS_MMB_tast_XIX_SAM
    delegate Druckpunktmassage_fuer_Beifahrersitz_Lehnenmassage_SAM_XIX_DPMBFSLM_XIX_SAM.RP_IF_BFS_MMB_tipp_XIX_Druckpunktmassage_fuer_Beifahrersitz_Lehnenmassage_SAM_XIX_DPMBFSLM_XIX_SAM <-> outer port RP_IF_BFS_MMB_tipp_XIX_SAM  # _XIX_Grundumfang_XIX_SitzMemo_BFS_XIX_Druckpunktmassage_fuer_Beifahrersitz_Lehnenmassage_SAM_XIX_DPMBFSLM_XIX_SAM_XIX_BFS_MMB_tipp
    delegate Druckpunktmassage_fuer_Fahrersitz_Lehnenmassage_SAM_XIX_DPMFSLM_XIX_SAM.RP_IF_BFS_MMB_tipp_XIX_Druckpunktmassage_fuer_Fahrersitz_Lehnenmassage_SAM_XIX_DPMFSLM_XIX_SAM <-> outer port RP_IF_BFS_MMB_tipp_XIX_SAM
    delegate Grundumfang_XIX_SAM.RP_IF_BFS_MMB_tipp_XIX_Grundumfang_XIX_SAM <-> outer port RP_IF_BFS_MMB_tipp_XIX_SAM
    delegate ABL_XIX_SAM.RP_IF_BH_Blinker_Fehler_XIX_ABL_XIX_SAM <-> outer port RP_IF_BH_Blinker_Fehler_XIX_SAM
    delegate Grundumfang_XIX_SAM.RP_IF_BH_Blinker_Fehler_XIX_Grundumfang_XIX_SAM <-> outer port RP_IF_BH_Blinker_Fehler_XIX_SAM
    delegate ABL_XIX_SAM.RP_IF_BH_Blinker_li_invers_XIX_ABL_XIX_SAM <-> outer port RP_IF_BH_Blinker_li_invers_XIX_SAM
    delegate Grundumfang_XIX_SAM.RP_IF_BH_Blinker_li_invers_XIX_Grundumfang_XIX_SAM <-> outer port RP_IF_BH_Blinker_li_invers_XIX_SAM
    delegate Grundumfang_XIX_SAM.RP_IF_BH_Blinker_li_XIX_Grundumfang_XIX_SAM <-> outer port RP_IF_BH_Blinker_li_XIX_SAM
    delegate ABL_XIX_SAM.RP_IF_BH_Blinker_li_XIX_ABL_XIX_SAM <-> outer port RP_IF_BH_Blinker_li_XIX_SAM
    delegate ABL_XIX_SAM.RP_IF_BH_Blinker_re_invers_XIX_ABL_XIX_SAM <-> outer port RP_IF_BH_Blinker_re_invers_XIX_SAM
    delegate Grundumfang_XIX_SAM.RP_IF_BH_Blinker_re_invers_XIX_Grundumfang_XIX_SAM <-> outer port RP_IF_BH_Blinker_re_invers_XIX_SAM
    delegate Grundumfang_XIX_SAM.RP_IF_BH_Blinker_re_XIX_Grundumfang_XIX_SAM <-> outer port RP_IF_BH_Blinker_re_XIX_SAM
    delegate ABL_XIX_SAM.RP_IF_BH_Blinker_re_XIX_ABL_XIX_SAM <-> outer port RP_IF_BH_Blinker_re_XIX_SAM
    delegate Grundumfang_XIX_SAM.RP_IF_BH_Fernlicht_XIX_Grundumfang_XIX_SAM <-> outer port RP_IF_BH_Fernlicht_XIX_SAM
    delegate ABL_XIX_SAM.RP_IF_BH_Fernlicht_XIX_ABL_XIX_SAM <-> outer port RP_IF_BH_Fernlicht_XIX_SAM
    delegate Grundumfang_XIX_SAM.RP_IF_BH_Lichthupe_XIX_Grundumfang_XIX_SAM <-> outer port RP_IF_BH_Lichthupe_XIX_SAM
    delegate ABL_XIX_SAM.RP_IF_BH_Lichthupe_XIX_ABL_XIX_SAM <-> outer port RP_IF_BH_Lichthupe_XIX_SAM
    delegate ABL_XIX_SAM.RP_IF_BM_Warnblinken_XIX_ABL_XIX_SAM <-> outer port RP_IF_BM_Warnblinken_XIX_SAM
    delegate Grundumfang_XIX_SAM.RP_IF_BM_Warnblinken_XIX_Grundumfang_XIX_SAM <-> outer port RP_IF_BM_Warnblinken_XIX_SAM
    delegate ABL_XIX_SAM.RP_IF_BM_WBT_Beleuchtung_XIX_ABL_XIX_SAM <-> outer port RP_IF_BM_WBT_Beleuchtung_XIX_SAM
    delegate Grundumfang_XIX_SAM.RP_IF_BM_WBT_Beleuchtung_XIX_Grundumfang_XIX_SAM <-> outer port RP_IF_BM_WBT_Beleuchtung_XIX_SAM
    delegate ABL_XIX_SAM.RP_IF_BM_ZV_auf_XIX_ABL_XIX_SAM <-> outer port RP_IF_BM_ZV_auf_XIX_SAM
    delegate Grundumfang_XIX_SAM.RP_IF_BM_ZV_auf_XIX_Grundumfang_XIX_SAM <-> outer port RP_IF_BM_ZV_auf_XIX_SAM
    delegate ABL_XIX_SAM.RP_IF_BM_ZV_zu_XIX_ABL_XIX_SAM <-> outer port RP_IF_BM_ZV_zu_XIX_SAM
    delegate Grundumfang_XIX_SAM.RP_IF_BM_ZV_zu_XIX_Grundumfang_XIX_SAM <-> outer port RP_IF_BM_ZV_zu_XIX_SAM
    delegate Grundumfang_XIX_SAM.RP_IF_BMCe_ORUData_XIX_Grundumfang_XIX_SAM <-> outer port RP_IF_BMCe_ORUData_XIX_SAM
    delegate Grundumfang_XIX_SAM.RP_IF_BMCe_ORUDataIndex_XIX_Grundumfang_XIX_SAM <-> outer port RP_IF_BMCe_ORUDataIndex_XIX_SAM
    delegate Grundumfang_XIX_SAM.RP_IF_BMS_KundenWarnung_XIX_Grundumfang_XIX_SAM <-> outer port RP_IF_BMS_KundenWarnung_XIX_SAM
    delegate Grundumfang_XIX_SAM.RP_IF_BT_FH_Bew_hoch_XIX_Grundumfang_XIX_SAM <-> outer port RP_IF_BT_FH_Bew_hoch_XIX_SAM
    delegate Grundumfang_XIX_SAM.RP_IF_BT_FH_Bew_tief_XIX_Grundumfang_XIX_SAM <-> outer port RP_IF_BT_FH_Bew_tief_XIX_SAM
    delegate Grundumfang_XIX_SAM.RP_IF_BT_Oben_Block_erw_XIX_Grundumfang_XIX_SAM <-> outer port RP_IF_BT_Oben_Block_erw_XIX_SAM
    delegate Grundumfang_XIX_SAM.RP_IF_BT_Sp_Blk_def_XIX_Grundumfang_XIX_SAM <-> outer port RP_IF_BT_Sp_Blk_def_XIX_SAM
    delegate Grundumfang_XIX_SAM.RP_IF_BT_Tuer_geoeffnet_XIX_Grundumfang_XIX_SAM <-> outer port RP_IF_BT_Tuer_geoeffnet_XIX_SAM
    delegate Grundumfang_XIX_SAM.RP_IF_BT_Unten_Block_erw_XIX_Grundumfang_XIX_SAM <-> outer port RP_IF_BT_Unten_Block_erw_XIX_SAM
    delegate Grundumfang_XIX_SAM.RP_IF_CHA_Fahrer_Umschaltung_XIX_Grundumfang_XIX_SAM <-> outer port RP_IF_CHA_Fahrer_Umschaltung_XIX_SAM
    delegate Grundumfang_XIX_SAM.RP_IF_CHA_Ziel_FahrPr_AMB_XIX_Grundumfang_XIX_SAM <-> outer port RP_IF_CHA_Ziel_FahrPr_AMB_XIX_SAM
    delegate SC_708_IuALicht_MEB_XIX_Softwareblock_XIX_SAM.RP_IF_CHA_Ziel_FahrPr_AMB_XIX_SC_708_IuALicht_MEB_XIX_Softwareblock_XIX_SAM <-> outer port RP_IF_CHA_Ziel_FahrPr_AMB_XIX_SAM
    delegate Grundumfang_XIX_SAM.RP_IF_CPDFct_FlashAndHonk_XIX_Grundumfang_XIX_SAM <-> outer port RP_IF_CPDFct_FlashAndHonk_XIX_SAM
    delegate Grundumfang_XIX_SAM.RP_IF_DCDC_HR_ORUData_XIX_Grundumfang_XIX_SAM <-> outer port RP_IF_DCDC_HR_ORUData_XIX_SAM
    delegate Grundumfang_XIX_SAM.RP_IF_DCDC_HR_ORUDataIndex_XIX_Grundumfang_XIX_SAM <-> outer port RP_IF_DCDC_HR_ORUDataIndex_XIX_SAM
    delegate Grundumfang_XIX_SAM.RP_IF_DCDC_NV_ORUDataIndex_XIX_Grundumfang_XIX_SAM <-> outer port RP_IF_DCDC_NV_ORUDataIndex_XIX_SAM
    delegate Grundumfang_XIX_SAM.RP_IF_DCDC_ORUData_XIX_Grundumfang_XIX_SAM <-> outer port RP_IF_DCDC_ORUData_XIX_SAM
    delegate Grundumfang_XIX_SAM.RP_IF_DGN_Verlernzaehler_XIX_Grundumfang_XIX_SAM <-> outer port RP_IF_DGN_Verlernzaehler_XIX_SAM  # _XIX_SC_738_ClassicAUTOSARBasicSoftwareICAS1Gateway_XIX_Softwareblock_XIX_ICAS1_X_Gateway_XIX_Grundumfang_XIX_SAM_XIX_DGN_Verlernzaehler
    delegate Dimmung_XIX_SAM.RP_IF_DI_KL_58xd_XIX_Dimmung_XIX_SAM <-> outer port RP_IF_DI_KL_58xd_XIX_SAM
    delegate Grundumfang_XIX_SAM.RP_IF_DI_KL_58xd_XIX_Grundumfang_XIX_SAM <-> outer port RP_IF_DI_KL_58xd_XIX_SAM
    delegate Dimmung_XIX_SAM.RP_IF_DI_KL_58xs_XIX_Dimmung_XIX_SAM <-> outer port RP_IF_DI_KL_58xs_XIX_SAM
    delegate Grundumfang_XIX_SAM.RP_IF_DI_KL_58xs_XIX_Grundumfang_XIX_SAM <-> outer port RP_IF_DI_KL_58xs_XIX_SAM
    delegate SC_708_IuALicht_MEB_XIX_Softwareblock_XIX_SAM.RP_IF_DI_KL_58xs_XIX_SC_708_IuALicht_MEB_XIX_Softwareblock_XIX_SAM <-> outer port RP_IF_DI_KL_58xs_XIX_SAM
    delegate Dimmung_XIX_SAM.RP_IF_DI_KL_58xt_XIX_Dimmung_XIX_SAM <-> outer port RP_IF_DI_KL_58xt_XIX_SAM
    delegate Grundumfang_XIX_SAM.RP_IF_DI_KL_58xt_XIX_Grundumfang_XIX_SAM <-> outer port RP_IF_DI_KL_58xt_XIX_SAM
    delegate Grundumfang_XIX_SAM.RP_IF_DiETa_Car_XIX_Grundumfang_XIX_SAM <-> outer port RP_IF_DiETa_Car_XIX_SAM
    delegate Grundumfang_XIX_SAM.RP_IF_DiETa_Defrost_Taste_XIX_Grundumfang_XIX_SAM <-> outer port RP_IF_DiETa_Defrost_Taste_XIX_SAM
    delegate Grundumfang_XIX_SAM.RP_IF_DiETa_FAS_Stufe_XIX_Grundumfang_XIX_SAM <-> outer port RP_IF_DiETa_FAS_Stufe_XIX_SAM
    delegate Grundumfang_XIX_SAM.RP_IF_DiETa_FSH_Taste_XIX_Grundumfang_XIX_SAM <-> outer port RP_IF_DiETa_FSH_Taste_XIX_SAM
    delegate Grundumfang_XIX_SAM.RP_IF_DiETa_HSH_Taste_XIX_Grundumfang_XIX_SAM <-> outer port RP_IF_DiETa_HSH_Taste_XIX_SAM
    delegate Grundumfang_XIX_SAM.RP_IF_DiETa_Klima_XIX_Grundumfang_XIX_SAM <-> outer port RP_IF_DiETa_Klima_XIX_SAM
    delegate Grundumfang_XIX_SAM.RP_IF_DiETa_Lock_Unlock_Taste_XIX_Grundumfang_XIX_SAM <-> outer port RP_IF_DiETa_Lock_Unlock_Taste_XIX_SAM
    delegate Grundumfang_XIX_SAM.RP_IF_DiETa_Mode_XIX_Grundumfang_XIX_SAM <-> outer port RP_IF_DiETa_Mode_XIX_SAM
    delegate Grundumfang_XIX_SAM.RP_IF_DiETa_Parken_XIX_Grundumfang_XIX_SAM <-> outer port RP_IF_DiETa_Parken_XIX_SAM
    delegate ABL_XIX_SAM.RP_IF_DiETa_ResponseError_XIX_ABL_XIX_SAM <-> outer port RP_IF_DiETa_ResponseError_XIX_SAM
    delegate Grundumfang_XIX_SAM.RP_IF_DiETa_ResponseError_XIX_Grundumfang_XIX_SAM <-> outer port RP_IF_DiETa_ResponseError_XIX_SAM
    delegate ABL_XIX_SAM.RP_IF_DiETa_Status_XIX_ABL_XIX_SAM <-> outer port RP_IF_DiETa_Status_XIX_SAM
    delegate Grundumfang_XIX_SAM.RP_IF_DiETa_Status_XIX_Grundumfang_XIX_SAM <-> outer port RP_IF_DiETa_Status_XIX_SAM
    delegate ABL_XIX_SAM.RP_IF_DiETa_Warnblink_Taste_XIX_ABL_XIX_SAM <-> outer port RP_IF_DiETa_Warnblink_Taste_XIX_SAM
    delegate Grundumfang_XIX_SAM.RP_IF_DLI_Ambex_RefStatus_XIX_Grundumfang_XIX_SAM <-> outer port RP_IF_DLI_Ambex_RefStatus_XIX_SAM
    delegate Grundumfang_XIX_SAM.RP_IF_DRB1_01_BZ_XIX_Grundumfang_XIX_SAM <-> outer port RP_IF_DRB1_01_BZ_XIX_SAM
    delegate Grundumfang_XIX_SAM.RP_IF_DRB1_01_CRC_XIX_Grundumfang_XIX_SAM <-> outer port RP_IF_DRB1_01_CRC_XIX_SAM
    delegate Grundumfang_XIX_SAM.RP_IF_DRB1_ORUData_XIX_Grundumfang_XIX_SAM <-> outer port RP_IF_DRB1_ORUData_XIX_SAM
    delegate Grundumfang_XIX_SAM.RP_IF_DRB1_ORUDataIndex_XIX_Grundumfang_XIX_SAM <-> outer port RP_IF_DRB1_ORUDataIndex_XIX_SAM
    delegate Grundumfang_XIX_SAM.RP_IF_DRB2_01_BZ_XIX_Grundumfang_XIX_SAM <-> outer port RP_IF_DRB2_01_BZ_XIX_SAM
    delegate Grundumfang_XIX_SAM.RP_IF_DRB2_01_CRC_XIX_Grundumfang_XIX_SAM <-> outer port RP_IF_DRB2_01_CRC_XIX_SAM
    delegate Grundumfang_XIX_SAM.RP_IF_DRB2_ORUData_XIX_Grundumfang_XIX_SAM <-> outer port RP_IF_DRB2_ORUData_XIX_SAM
    delegate Grundumfang_XIX_SAM.RP_IF_DRB2_ORUDataIndex_XIX_Grundumfang_XIX_SAM <-> outer port RP_IF_DRB2_ORUDataIndex_XIX_SAM
    delegate Grundumfang_XIX_SAM.RP_IF_EA_Fahrzeughupe_Anf_XIX_Grundumfang_XIX_SAM <-> outer port RP_IF_EA_Fahrzeughupe_Anf_XIX_SAM
    delegate Grundumfang_XIX_SAM.RP_IF_EA_Innenraumlicht_Anf_XIX_Grundumfang_XIX_SAM <-> outer port RP_IF_EA_Innenraumlicht_Anf_XIX_SAM
    delegate Grundumfang_XIX_SAM.RP_IF_EBKV_2Box_ORUDataIndex_XIX_Grundumfang_XIX_SAM <-> outer port RP_IF_EBKV_2Box_ORUDataIndex_XIX_SAM
    delegate Grundumfang_XIX_SAM.RP_IF_EBKV_ORUData_XIX_Grundumfang_XIX_SAM <-> outer port RP_IF_EBKV_ORUData_XIX_SAM
    delegate Grundumfang_XIX_SAM.RP_IF_eFuse1_ORUData_XIX_Grundumfang_XIX_SAM <-> outer port RP_IF_eFuse1_ORUData_XIX_SAM
    delegate Grundumfang_XIX_SAM.RP_IF_eFuse1_ORUDataIndex_XIX_Grundumfang_XIX_SAM <-> outer port RP_IF_eFuse1_ORUDataIndex_XIX_SAM
    delegate Grundumfang_XIX_SAM.RP_IF_eFuse3_ORUData_XIX_Grundumfang_XIX_SAM <-> outer port RP_IF_eFuse3_ORUData_XIX_SAM
    delegate Grundumfang_XIX_SAM.RP_IF_eFuse3_ORUDataIndex_XIX_Grundumfang_XIX_SAM <-> outer port RP_IF_eFuse3_ORUDataIndex_XIX_SAM
    delegate Grundumfang_XIX_SAM.RP_IF_EM1_HYB_13_BZ_XIX_Grundumfang_XIX_SAM <-> outer port RP_IF_EM1_HYB_13_BZ_XIX_SAM
    delegate Grundumfang_XIX_SAM.RP_IF_EM1_HYB_13_CRC_XIX_Grundumfang_XIX_SAM <-> outer port RP_IF_EM1_HYB_13_CRC_XIX_SAM
    delegate Grundumfang_XIX_SAM.RP_IF_EM2_HYB_13_BZ_XIX_Grundumfang_XIX_SAM <-> outer port RP_IF_EM2_HYB_13_BZ_XIX_SAM
    delegate Grundumfang_XIX_SAM.RP_IF_EM2_HYB_13_CRC_XIX_Grundumfang_XIX_SAM <-> outer port RP_IF_EM2_HYB_13_CRC_XIX_SAM
    delegate Grundumfang_XIX_SAM.RP_IF_EPB_Status_02_XIX_Grundumfang_XIX_SAM <-> outer port RP_IF_EPB_Status_02_XIX_SAM
    delegate Grundumfang_XIX_SAM.RP_IF_EPH_ORUData_XIX_Grundumfang_XIX_SAM <-> outer port RP_IF_EPH_ORUData_XIX_SAM
    delegate Grundumfang_XIX_SAM.RP_IF_EPH_ORUDataIndex_XIX_Grundumfang_XIX_SAM <-> outer port RP_IF_EPH_ORUDataIndex_XIX_SAM
    delegate Grundumfang_XIX_SAM.RP_IF_eRWK_AD_oeffnen_Anf_XIX_Grundumfang_XIX_SAM <-> outer port RP_IF_eRWK_AD_oeffnen_Anf_XIX_SAM
    delegate Grundumfang_XIX_SAM.RP_IF_eRWK_AD_schliessen_Anf_XIX_Grundumfang_XIX_SAM <-> outer port RP_IF_eRWK_AD_schliessen_Anf_XIX_SAM
    delegate Grundumfang_XIX_SAM.RP_IF_ESC_Bremsfluessigkeits_Sensor_XIX_Grundumfang_XIX_SAM <-> outer port RP_IF_ESC_Bremsfluessigkeits_Sensor_XIX_SAM
    delegate Grundumfang_XIX_SAM.RP_IF_ESC_ORUData_XIX_Grundumfang_XIX_SAM <-> outer port RP_IF_ESC_ORUData_XIX_SAM
    delegate Grundumfang_XIX_SAM.RP_IF_ESC_ORUDataIndex_XIX_Grundumfang_XIX_SAM <-> outer port RP_IF_ESC_ORUDataIndex_XIX_SAM
    delegate Grundumfang_XIX_SAM.RP_IF_ESC_v_Signal_Qualifier_High_Low_XIX_Grundumfang_XIX_SAM <-> outer port RP_IF_ESC_v_Signal_Qualifier_High_Low_XIX_SAM
    delegate Grundumfang_XIX_SAM.RP_IF_ESP_21_BZ_XIX_Grundumfang_XIX_SAM <-> outer port RP_IF_ESP_21_BZ_XIX_SAM
    delegate Grundumfang_XIX_SAM.RP_IF_ESP_21_CRC_XIX_Grundumfang_XIX_SAM <-> outer port RP_IF_ESP_21_CRC_XIX_SAM
    delegate Grundumfang_XIX_SAM.RP_IF_ESP_Laengsbeschl_XIX_Grundumfang_XIX_SAM <-> outer port RP_IF_ESP_Laengsbeschl_XIX_SAM
    delegate Grundumfang_XIX_SAM.RP_IF_ESP_m_Raddrehz_XIX_Grundumfang_XIX_SAM <-> outer port RP_IF_ESP_m_Raddrehz_XIX_SAM
    delegate Grundumfang_XIX_SAM.RP_IF_ESP_QBit_v_Signal_XIX_Grundumfang_XIX_SAM <-> outer port RP_IF_ESP_QBit_v_Signal_XIX_SAM
    delegate Grundumfang_XIX_SAM.RP_IF_ESP_Querbeschleunigung_XIX_Grundumfang_XIX_SAM <-> outer port RP_IF_ESP_Querbeschleunigung_XIX_SAM
    delegate Grundumfang_XIX_SAM.RP_IF_ESP_Status_Bremsentemp_02_XIX_Grundumfang_XIX_SAM <-> outer port RP_IF_ESP_Status_Bremsentemp_02_XIX_SAM
    delegate Grundumfang_XIX_SAM.RP_IF_ESP_v_Signal_XIX_Grundumfang_XIX_SAM <-> outer port RP_IF_ESP_v_Signal_XIX_SAM
    delegate VIP_XIX_SAM.RP_IF_ESP_v_Signal_XIX_VIP_XIX_SAM <-> outer port RP_IF_ESP_v_Signal_XIX_SAM
    delegate Grundumfang_XIX_SAM.RP_IF_Fahrerdisplay_Kombi_ORUData_XIX_Grundumfang_XIX_SAM <-> outer port RP_IF_Fahrerdisplay_Kombi_ORUData_XIX_SAM
    delegate Grundumfang_XIX_SAM.RP_IF_Fahrerdisplay_Kombi_ORUDataIndex_XIX_Grundumfang_XIX_SAM <-> outer port RP_IF_Fahrerdisplay_Kombi_ORUDataIndex_XIX_SAM
    delegate Grundumfang_XIX_SAM.RP_IF_FAS_Taster_Fehler_XIX_Grundumfang_XIX_SAM <-> outer port RP_IF_FAS_Taster_Fehler_XIX_SAM
    delegate Grundumfang_XIX_SAM.RP_IF_FAS_Taster_XIX_Grundumfang_XIX_SAM <-> outer port RP_IF_FAS_Taster_XIX_SAM
    delegate Grundumfang_XIX_SAM.RP_IF_FASFrontradar_ORUData_XIX_Grundumfang_XIX_SAM <-> outer port RP_IF_FASFrontradar_ORUData_XIX_SAM
    delegate Grundumfang_XIX_SAM.RP_IF_FASFrontradar_ORUDataIndex_XIX_Grundumfang_XIX_SAM <-> outer port RP_IF_FASFrontradar_ORUDataIndex_XIX_SAM
    delegate Grundumfang_XIX_SAM.RP_IF_FFB_HDF_Taste_XIX_Grundumfang_XIX_SAM <-> outer port RP_IF_FFB_HDF_Taste_XIX_SAM
    delegate Grundumfang_XIX_SAM.RP_IF_FH_HBFS_hoch_XIX_Grundumfang_XIX_SAM <-> outer port RP_IF_FH_HBFS_hoch_XIX_SAM
    delegate Grundumfang_XIX_SAM.RP_IF_FH_HBFS_tief_XIX_Grundumfang_XIX_SAM <-> outer port RP_IF_FH_HBFS_tief_XIX_SAM
    delegate Grundumfang_XIX_SAM.RP_IF_FH_HFS_hoch_XIX_Grundumfang_XIX_SAM <-> outer port RP_IF_FH_HFS_hoch_XIX_SAM
    delegate Grundumfang_XIX_SAM.RP_IF_FH_HFS_tief_XIX_Grundumfang_XIX_SAM <-> outer port RP_IF_FH_HFS_tief_XIX_SAM
    delegate Grundumfang_XIX_SAM.RP_IF_FoD_Transmission_Info_XIX_Grundumfang_XIX_SAM <-> outer port RP_IF_FoD_Transmission_Info_XIX_SAM
    delegate SC_447_FoD_Slave_4_XIX_Softwareblock_XIX_SAM.RP_IF_FoD_Transmission_Info_XIX_SC_447_FoD_Slave_4_XIX_Softwareblock_XIX_SAM <-> outer port RP_IF_FoD_Transmission_Info_XIX_SAM  # _XIX_SC_446_FoD_Distribution_Master_XIX_Softwareblock_XIX_ICAS1_X_Gateway_XIX_SC_447_FoD_Slave_4_XIX_Softwareblock_XIX_SAM_XIX_FoD_Transmission_Info
    delegate Grundumfang_XIX_SAM.RP_IF_FS_Luftfeuchte_rel_XIX_Grundumfang_XIX_SAM <-> outer port RP_IF_FS_Luftfeuchte_rel_XIX_SAM
    delegate Druckpunktmassage_fuer_Beifahrersitz_Lehnenmassage_SAM_XIX_DPMBFSLM_XIX_SAM.RP_IF_FS_MMB_glob_stop_XIX_Druckpunktmassage_fuer_Beifahrersitz_Lehnenmassage_SAM_XIX_DPMBFSLM_XIX_SAM <-> outer port RP_IF_FS_MMB_glob_stop_XIX_SAM  # _XIX_Grundumfang_XIX_SitzMemo_FS_XIX_Druckpunktmassage_fuer_Beifahrersitz_Lehnenmassage_SAM_XIX_DPMBFSLM_XIX_SAM_XIX_FS_MMB_glob_stop
    delegate Druckpunktmassage_fuer_Fahrersitz_Lehnenmassage_SAM_XIX_DPMFSLM_XIX_SAM.RP_IF_FS_MMB_glob_stop_XIX_Druckpunktmassage_fuer_Fahrersitz_Lehnenmassage_SAM_XIX_DPMFSLM_XIX_SAM <-> outer port RP_IF_FS_MMB_glob_stop_XIX_SAM  # _XIX_Grundumfang_XIX_SitzMemo_FS_XIX_Druckpunktmassage_fuer_Fahrersitz_Lehnenmassage_SAM_XIX_DPMFSLM_XIX_SAM_XIX_FS_MMB_glob_stop
    delegate Grundumfang_XIX_SAM.RP_IF_FS_MMB_glob_stop_XIX_Grundumfang_XIX_SAM <-> outer port RP_IF_FS_MMB_glob_stop_XIX_SAM
    delegate Druckpunktmassage_fuer_Beifahrersitz_Lehnenmassage_SAM_XIX_DPMBFSLM_XIX_SAM.RP_IF_FS_MMB_storage_XIX_Druckpunktmassage_fuer_Beifahrersitz_Lehnenmassage_SAM_XIX_DPMBFSLM_XIX_SAM <-> outer port RP_IF_FS_MMB_storage_XIX_SAM  # _XIX_Grundumfang_XIX_SitzMemo_FS_XIX_Druckpunktmassage_fuer_Beifahrersitz_Lehnenmassage_SAM_XIX_DPMBFSLM_XIX_SAM_XIX_FS_MMB_storage
    delegate Druckpunktmassage_fuer_Fahrersitz_Lehnenmassage_SAM_XIX_DPMFSLM_XIX_SAM.RP_IF_FS_MMB_storage_XIX_Druckpunktmassage_fuer_Fahrersitz_Lehnenmassage_SAM_XIX_DPMFSLM_XIX_SAM <-> outer port RP_IF_FS_MMB_storage_XIX_SAM
    delegate Grundumfang_XIX_SAM.RP_IF_FS_MMB_storage_XIX_Grundumfang_XIX_SAM <-> outer port RP_IF_FS_MMB_storage_XIX_SAM
    delegate Druckpunktmassage_fuer_Beifahrersitz_Lehnenmassage_SAM_XIX_DPMBFSLM_XIX_SAM.RP_IF_FS_MMB_tast_XIX_Druckpunktmassage_fuer_Beifahrersitz_Lehnenmassage_SAM_XIX_DPMBFSLM_XIX_SAM <-> outer port RP_IF_FS_MMB_tast_XIX_SAM
    delegate Druckpunktmassage_fuer_Fahrersitz_Lehnenmassage_SAM_XIX_DPMFSLM_XIX_SAM.RP_IF_FS_MMB_tast_XIX_Druckpunktmassage_fuer_Fahrersitz_Lehnenmassage_SAM_XIX_DPMFSLM_XIX_SAM <-> outer port RP_IF_FS_MMB_tast_XIX_SAM
    delegate Grundumfang_XIX_SAM.RP_IF_FS_MMB_tast_XIX_Grundumfang_XIX_SAM <-> outer port RP_IF_FS_MMB_tast_XIX_SAM
    delegate Druckpunktmassage_fuer_Beifahrersitz_Lehnenmassage_SAM_XIX_DPMBFSLM_XIX_SAM.RP_IF_FS_MMB_tipp_XIX_Druckpunktmassage_fuer_Beifahrersitz_Lehnenmassage_SAM_XIX_DPMBFSLM_XIX_SAM <-> outer port RP_IF_FS_MMB_tipp_XIX_SAM
    delegate Druckpunktmassage_fuer_Fahrersitz_Lehnenmassage_SAM_XIX_DPMFSLM_XIX_SAM.RP_IF_FS_MMB_tipp_XIX_Druckpunktmassage_fuer_Fahrersitz_Lehnenmassage_SAM_XIX_DPMFSLM_XIX_SAM <-> outer port RP_IF_FS_MMB_tipp_XIX_SAM
    delegate Grundumfang_XIX_SAM.RP_IF_FS_MMB_tipp_XIX_Grundumfang_XIX_SAM <-> outer port RP_IF_FS_MMB_tipp_XIX_SAM
    delegate Grundumfang_XIX_SAM.RP_IF_FS_ResponseError_XIX_Grundumfang_XIX_SAM <-> outer port RP_IF_FS_ResponseError_XIX_SAM
    delegate Grundumfang_XIX_SAM.RP_IF_FS_Taupunkt_XIX_Grundumfang_XIX_SAM <-> outer port RP_IF_FS_Taupunkt_XIX_SAM
    delegate Grundumfang_XIX_SAM.RP_IF_FS_Temp_Scheibe_XIX_Grundumfang_XIX_SAM <-> outer port RP_IF_FS_Temp_Scheibe_XIX_SAM
    delegate Grundumfang_XIX_SAM.RP_IF_FS_Temp_Sensor_XIX_Grundumfang_XIX_SAM <-> outer port RP_IF_FS_Temp_Sensor_XIX_SAM
    delegate Grundumfang_XIX_SAM.RP_IF_FT_FH_Bew_hoch_XIX_Grundumfang_XIX_SAM <-> outer port RP_IF_FT_FH_Bew_hoch_XIX_SAM
    delegate Grundumfang_XIX_SAM.RP_IF_FT_FH_Bew_tief_XIX_Grundumfang_XIX_SAM <-> outer port RP_IF_FT_FH_Bew_tief_XIX_SAM
    delegate Grundumfang_XIX_SAM.RP_IF_FT_Kisi_li_aktiv_XIX_Grundumfang_XIX_SAM <-> outer port RP_IF_FT_Kisi_li_aktiv_XIX_SAM
    delegate Grundumfang_XIX_SAM.RP_IF_FT_Kisi_re_aktiv_XIX_Grundumfang_XIX_SAM <-> outer port RP_IF_FT_Kisi_re_aktiv_XIX_SAM
    delegate ZV_XIX_SAM.RP_IF_FT_Kisi_Taster_li_02_XIX_ZV_XIX_SAM <-> outer port RP_IF_FT_Kisi_Taster_li_02_XIX_SAM
    delegate Grundumfang_XIX_SAM.RP_IF_FT_Kisi_Taster_li_XIX_Grundumfang_XIX_SAM <-> outer port RP_IF_FT_Kisi_Taster_li_XIX_SAM
    delegate ZV_XIX_SAM.RP_IF_FT_Kisi_Taster_re_02_XIX_ZV_XIX_SAM <-> outer port RP_IF_FT_Kisi_Taster_re_02_XIX_SAM
    delegate Grundumfang_XIX_SAM.RP_IF_FT_Kisi_Taster_re_XIX_Grundumfang_XIX_SAM <-> outer port RP_IF_FT_Kisi_Taster_re_XIX_SAM
    delegate Grundumfang_XIX_SAM.RP_IF_FT_Oben_Block_erw_XIX_Grundumfang_XIX_SAM <-> outer port RP_IF_FT_Oben_Block_erw_XIX_SAM
    delegate Grundumfang_XIX_SAM.RP_IF_FT_Sp_Blk_def_XIX_Grundumfang_XIX_SAM <-> outer port RP_IF_FT_Sp_Blk_def_XIX_SAM
    delegate Grundumfang_XIX_SAM.RP_IF_FT_Tuer_geoeffnet_XIX_Grundumfang_XIX_SAM <-> outer port RP_IF_FT_Tuer_geoeffnet_XIX_SAM
    delegate Grundumfang_XIX_SAM.RP_IF_FT_Unten_Block_erw_XIX_Grundumfang_XIX_SAM <-> outer port RP_IF_FT_Unten_Block_erw_XIX_SAM
    delegate Grundumfang_XIX_SAM.RP_IF_GE_Fahrstufe_XIX_Grundumfang_XIX_SAM <-> outer port RP_IF_GE_Fahrstufe_XIX_SAM
    delegate Grundumfang_XIX_SAM.RP_IF_HBFS_Fehler_Beleuchtung_XIX_Grundumfang_XIX_SAM <-> outer port RP_IF_HBFS_Fehler_Beleuchtung_XIX_SAM
    delegate Grundumfang_XIX_SAM.RP_IF_HBFS_Fehler_FH_Normierung_XIX_Grundumfang_XIX_SAM <-> outer port RP_IF_HBFS_Fehler_FH_Normierung_XIX_SAM
    delegate Grundumfang_XIX_SAM.RP_IF_HBFS_Fehler_FH_Schalter_XIX_Grundumfang_XIX_SAM <-> outer port RP_IF_HBFS_Fehler_FH_Schalter_XIX_SAM
    delegate Grundumfang_XIX_SAM.RP_IF_HBFS_Fehler_Hallsensor_XIX_Grundumfang_XIX_SAM <-> outer port RP_IF_HBFS_Fehler_Hallsensor_XIX_SAM
    delegate Grundumfang_XIX_SAM.RP_IF_HBFS_Fehler_Kodierdaten_XIX_Grundumfang_XIX_SAM <-> outer port RP_IF_HBFS_Fehler_Kodierdaten_XIX_SAM
    delegate Grundumfang_XIX_SAM.RP_IF_HBFS_Fehler_Parameter_XIX_Grundumfang_XIX_SAM <-> outer port RP_IF_HBFS_Fehler_Parameter_XIX_SAM
    delegate Grundumfang_XIX_SAM.RP_IF_HBFS_Fehler_SG_XIX_Grundumfang_XIX_SAM <-> outer port RP_IF_HBFS_Fehler_SG_XIX_SAM
    delegate Grundumfang_XIX_SAM.RP_IF_HBFS_FH_Bew_hoch_XIX_Grundumfang_XIX_SAM <-> outer port RP_IF_HBFS_FH_Bew_hoch_XIX_SAM
    delegate Grundumfang_XIX_SAM.RP_IF_HBFS_FH_Bew_tief_XIX_Grundumfang_XIX_SAM <-> outer port RP_IF_HBFS_FH_Bew_tief_XIX_SAM
    delegate Grundumfang_XIX_SAM.RP_IF_HBFS_FH_Block_XIX_Grundumfang_XIX_SAM <-> outer port RP_IF_HBFS_FH_Block_XIX_SAM
    delegate Grundumfang_XIX_SAM.RP_IF_HBFS_FH_Fang_XIX_Grundumfang_XIX_SAM <-> outer port RP_IF_HBFS_FH_Fang_XIX_SAM
    delegate Grundumfang_XIX_SAM.RP_IF_HBFS_FH_normiert_XIX_Grundumfang_XIX_SAM <-> outer port RP_IF_HBFS_FH_normiert_XIX_SAM
    delegate Grundumfang_XIX_SAM.RP_IF_HBFS_FH_Oeffnung_XIX_Grundumfang_XIX_SAM <-> outer port RP_IF_HBFS_FH_Oeffnung_XIX_SAM
    delegate Grundumfang_XIX_SAM.RP_IF_HBFS_FH_S_AutoHoch_XIX_Grundumfang_XIX_SAM <-> outer port RP_IF_HBFS_FH_S_AutoHoch_XIX_SAM
    delegate Grundumfang_XIX_SAM.RP_IF_HBFS_FH_S_AutoTief_XIX_Grundumfang_XIX_SAM <-> outer port RP_IF_HBFS_FH_S_AutoTief_XIX_SAM
    delegate Grundumfang_XIX_SAM.RP_IF_HBFS_FH_S_ManHoch_XIX_Grundumfang_XIX_SAM <-> outer port RP_IF_HBFS_FH_S_ManHoch_XIX_SAM
    delegate Grundumfang_XIX_SAM.RP_IF_HBFS_FH_S_ManTief_XIX_Grundumfang_XIX_SAM <-> outer port RP_IF_HBFS_FH_S_ManTief_XIX_SAM
    delegate Grundumfang_XIX_SAM.RP_IF_HBFS_FH_Thermo_XIX_Grundumfang_XIX_SAM <-> outer port RP_IF_HBFS_FH_Thermo_XIX_SAM
    delegate Grundumfang_XIX_SAM.RP_IF_HBFS_FH_Ueberspannung_XIX_Grundumfang_XIX_SAM <-> outer port RP_IF_HBFS_FH_Ueberspannung_XIX_SAM
    delegate Grundumfang_XIX_SAM.RP_IF_HBFS_FH_Unterspannung_XIX_Grundumfang_XIX_SAM <-> outer port RP_IF_HBFS_FH_Unterspannung_XIX_SAM
    delegate Grundumfang_XIX_SAM.RP_IF_HBFS_Oben_Block_erw_XIX_Grundumfang_XIX_SAM <-> outer port RP_IF_HBFS_Oben_Block_erw_XIX_SAM
    delegate Grundumfang_XIX_SAM.RP_IF_HBFS_RelaisFehler_XIX_Grundumfang_XIX_SAM <-> outer port RP_IF_HBFS_RelaisFehler_XIX_SAM
    delegate Grundumfang_XIX_SAM.RP_IF_HBFS_ResponseError_XIX_Grundumfang_XIX_SAM <-> outer port RP_IF_HBFS_ResponseError_XIX_SAM
    delegate Grundumfang_XIX_SAM.RP_IF_HBFS_SleepIndication_XIX_Grundumfang_XIX_SAM <-> outer port RP_IF_HBFS_SleepIndication_XIX_SAM
    delegate Grundumfang_XIX_SAM.RP_IF_HBFS_Status_KiSi_XIX_Grundumfang_XIX_SAM <-> outer port RP_IF_HBFS_Status_KiSi_XIX_SAM
    delegate Grundumfang_XIX_SAM.RP_IF_HBFS_Status_Routine_XIX_Grundumfang_XIX_SAM <-> outer port RP_IF_HBFS_Status_Routine_XIX_SAM
    delegate Grundumfang_XIX_SAM.RP_IF_HBFS_Status_Stellgliedtest_XIX_Grundumfang_XIX_SAM <-> outer port RP_IF_HBFS_Status_Stellgliedtest_XIX_SAM
    delegate Grundumfang_XIX_SAM.RP_IF_HBFS_TIG_betaetigt_XIX_Grundumfang_XIX_SAM <-> outer port RP_IF_HBFS_TIG_betaetigt_XIX_SAM
    delegate Grundumfang_XIX_SAM.RP_IF_HBFS_Tuer_geoeffnet_XIX_Grundumfang_XIX_SAM <-> outer port RP_IF_HBFS_Tuer_geoeffnet_XIX_SAM
    delegate Grundumfang_XIX_SAM.RP_IF_HBFS_UEKB_aktiviert_XIX_Grundumfang_XIX_SAM <-> outer port RP_IF_HBFS_UEKB_aktiviert_XIX_SAM
    delegate Grundumfang_XIX_SAM.RP_IF_HBFS_Unten_Block_erw_XIX_Grundumfang_XIX_SAM <-> outer port RP_IF_HBFS_Unten_Block_erw_XIX_SAM
    delegate Grundumfang_XIX_SAM.RP_IF_HFS_Fehler_Beleuchtung_XIX_Grundumfang_XIX_SAM <-> outer port RP_IF_HFS_Fehler_Beleuchtung_XIX_SAM
    delegate Grundumfang_XIX_SAM.RP_IF_HFS_Fehler_FH_Normierung_XIX_Grundumfang_XIX_SAM <-> outer port RP_IF_HFS_Fehler_FH_Normierung_XIX_SAM
    delegate Grundumfang_XIX_SAM.RP_IF_HFS_Fehler_FH_Schalter_XIX_Grundumfang_XIX_SAM <-> outer port RP_IF_HFS_Fehler_FH_Schalter_XIX_SAM
    delegate Grundumfang_XIX_SAM.RP_IF_HFS_Fehler_Hallsensor_XIX_Grundumfang_XIX_SAM <-> outer port RP_IF_HFS_Fehler_Hallsensor_XIX_SAM
    delegate Grundumfang_XIX_SAM.RP_IF_HFS_Fehler_Kodierdaten_XIX_Grundumfang_XIX_SAM <-> outer port RP_IF_HFS_Fehler_Kodierdaten_XIX_SAM
    delegate Grundumfang_XIX_SAM.RP_IF_HFS_Fehler_Parameter_XIX_Grundumfang_XIX_SAM <-> outer port RP_IF_HFS_Fehler_Parameter_XIX_SAM
    delegate Grundumfang_XIX_SAM.RP_IF_HFS_Fehler_SG_XIX_Grundumfang_XIX_SAM <-> outer port RP_IF_HFS_Fehler_SG_XIX_SAM
    delegate Grundumfang_XIX_SAM.RP_IF_HFS_FH_Bew_hoch_XIX_Grundumfang_XIX_SAM <-> outer port RP_IF_HFS_FH_Bew_hoch_XIX_SAM
    delegate Grundumfang_XIX_SAM.RP_IF_HFS_FH_Bew_tief_XIX_Grundumfang_XIX_SAM <-> outer port RP_IF_HFS_FH_Bew_tief_XIX_SAM
    delegate Grundumfang_XIX_SAM.RP_IF_HFS_FH_Block_XIX_Grundumfang_XIX_SAM <-> outer port RP_IF_HFS_FH_Block_XIX_SAM
    delegate Grundumfang_XIX_SAM.RP_IF_HFS_FH_Fang_XIX_Grundumfang_XIX_SAM <-> outer port RP_IF_HFS_FH_Fang_XIX_SAM
    delegate Grundumfang_XIX_SAM.RP_IF_HFS_FH_normiert_XIX_Grundumfang_XIX_SAM <-> outer port RP_IF_HFS_FH_normiert_XIX_SAM
    delegate Grundumfang_XIX_SAM.RP_IF_HFS_FH_Oeffnung_XIX_Grundumfang_XIX_SAM <-> outer port RP_IF_HFS_FH_Oeffnung_XIX_SAM
    delegate Grundumfang_XIX_SAM.RP_IF_HFS_FH_S_AutoHoch_XIX_Grundumfang_XIX_SAM <-> outer port RP_IF_HFS_FH_S_AutoHoch_XIX_SAM
    delegate Grundumfang_XIX_SAM.RP_IF_HFS_FH_S_AutoTief_XIX_Grundumfang_XIX_SAM <-> outer port RP_IF_HFS_FH_S_AutoTief_XIX_SAM
    delegate Grundumfang_XIX_SAM.RP_IF_HFS_FH_S_ManHoch_XIX_Grundumfang_XIX_SAM <-> outer port RP_IF_HFS_FH_S_ManHoch_XIX_SAM
    delegate Grundumfang_XIX_SAM.RP_IF_HFS_FH_S_ManTief_XIX_Grundumfang_XIX_SAM <-> outer port RP_IF_HFS_FH_S_ManTief_XIX_SAM
    delegate Grundumfang_XIX_SAM.RP_IF_HFS_FH_Thermo_XIX_Grundumfang_XIX_SAM <-> outer port RP_IF_HFS_FH_Thermo_XIX_SAM
    delegate Grundumfang_XIX_SAM.RP_IF_HFS_FH_Ueberspannung_XIX_Grundumfang_XIX_SAM <-> outer port RP_IF_HFS_FH_Ueberspannung_XIX_SAM
    delegate Grundumfang_XIX_SAM.RP_IF_HFS_FH_Unterspannung_XIX_Grundumfang_XIX_SAM <-> outer port RP_IF_HFS_FH_Unterspannung_XIX_SAM
    delegate Grundumfang_XIX_SAM.RP_IF_HFS_Oben_Block_erw_XIX_Grundumfang_XIX_SAM <-> outer port RP_IF_HFS_Oben_Block_erw_XIX_SAM
    delegate Grundumfang_XIX_SAM.RP_IF_HFS_RelaisFehler_XIX_Grundumfang_XIX_SAM <-> outer port RP_IF_HFS_RelaisFehler_XIX_SAM
    delegate Grundumfang_XIX_SAM.RP_IF_HFS_ResponseError_XIX_Grundumfang_XIX_SAM <-> outer port RP_IF_HFS_ResponseError_XIX_SAM
    delegate Grundumfang_XIX_SAM.RP_IF_HFS_SleepIndication_XIX_Grundumfang_XIX_SAM <-> outer port RP_IF_HFS_SleepIndication_XIX_SAM
    delegate Grundumfang_XIX_SAM.RP_IF_HFS_Status_KiSi_XIX_Grundumfang_XIX_SAM <-> outer port RP_IF_HFS_Status_KiSi_XIX_SAM
    delegate Grundumfang_XIX_SAM.RP_IF_HFS_Status_Routine_XIX_Grundumfang_XIX_SAM <-> outer port RP_IF_HFS_Status_Routine_XIX_SAM
    delegate Grundumfang_XIX_SAM.RP_IF_HFS_Status_Stellgliedtest_XIX_Grundumfang_XIX_SAM <-> outer port RP_IF_HFS_Status_Stellgliedtest_XIX_SAM
    delegate Grundumfang_XIX_SAM.RP_IF_HFS_TIG_betaetigt_XIX_Grundumfang_XIX_SAM <-> outer port RP_IF_HFS_TIG_betaetigt_XIX_SAM
    delegate Grundumfang_XIX_SAM.RP_IF_HFS_Tuer_geoeffnet_XIX_Grundumfang_XIX_SAM <-> outer port RP_IF_HFS_Tuer_geoeffnet_XIX_SAM
    delegate Grundumfang_XIX_SAM.RP_IF_HFS_UEKB_aktiviert_XIX_Grundumfang_XIX_SAM <-> outer port RP_IF_HFS_UEKB_aktiviert_XIX_SAM
    delegate Grundumfang_XIX_SAM.RP_IF_HFS_Unten_Block_erw_XIX_Grundumfang_XIX_SAM <-> outer port RP_IF_HFS_Unten_Block_erw_XIX_SAM
    delegate Grundumfang_XIX_SAM.RP_IF_HLR_LRH_Freigabe_XIX_Grundumfang_XIX_SAM <-> outer port RP_IF_HLR_LRH_Freigabe_XIX_SAM
    delegate Grundumfang_XIX_SAM.RP_IF_HMS_aktives_System_XIX_Grundumfang_XIX_SAM <-> outer port RP_IF_HMS_aktives_System_XIX_SAM
    delegate Grundumfang_XIX_SAM.RP_IF_HMS_Fehlerstatus_XIX_Grundumfang_XIX_SAM <-> outer port RP_IF_HMS_Fehlerstatus_XIX_SAM
    delegate Grundumfang_XIX_SAM.RP_IF_HMS_parken_nicht_verfuegbar_XIX_Grundumfang_XIX_SAM <-> outer port RP_IF_HMS_parken_nicht_verfuegbar_XIX_SAM
    delegate Grundumfang_XIX_SAM.RP_IF_HMS_Stillstand_XIX_Grundumfang_XIX_SAM <-> outer port RP_IF_HMS_Stillstand_XIX_SAM
    delegate Grundumfang_XIX_SAM.RP_IF_HMS_Systemstatus_XIX_Grundumfang_XIX_SAM <-> outer port RP_IF_HMS_Systemstatus_XIX_SAM
    delegate Grundumfang_XIX_SAM.RP_IF_HSH_Relais_Anf_XIX_Grundumfang_XIX_SAM <-> outer port RP_IF_HSH_Relais_Anf_XIX_SAM
    delegate Grundumfang_XIX_SAM.RP_IF_HUD_ORUData_XIX_Grundumfang_XIX_SAM <-> outer port RP_IF_HUD_ORUData_XIX_SAM
    delegate Grundumfang_XIX_SAM.RP_IF_HUD_ORUDataIndex_XIX_Grundumfang_XIX_SAM <-> outer port RP_IF_HUD_ORUDataIndex_XIX_SAM
    delegate Grundumfang_XIX_SAM.RP_IF_HVL_01_BZ_XIX_Grundumfang_XIX_SAM <-> outer port RP_IF_HVL_01_BZ_XIX_SAM
    delegate Grundumfang_XIX_SAM.RP_IF_HVL_01_CRC_XIX_Grundumfang_XIX_SAM <-> outer port RP_IF_HVL_01_CRC_XIX_SAM
    delegate Grundumfang_XIX_SAM.RP_IF_HVL_Steckerstatus_XIX_Grundumfang_XIX_SAM <-> outer port RP_IF_HVL_Steckerstatus_XIX_SAM
    delegate Grundumfang_XIX_SAM.RP_IF_HVLS_Steckerstatus_SG1_XIX_Grundumfang_XIX_SAM <-> outer port RP_IF_HVLS_Steckerstatus_SG1_XIX_SAM
    delegate Grundumfang_XIX_SAM.RP_IF_HVLS_Steckerstatus_SG2_XIX_Grundumfang_XIX_SAM <-> outer port RP_IF_HVLS_Steckerstatus_SG2_XIX_SAM
    delegate Grundumfang_XIX_SAM.RP_IF_ICAS1_X_ORUData_XIX_Grundumfang_XIX_SAM <-> outer port RP_IF_ICAS1_X_ORUData_XIX_SAM
    delegate Grundumfang_XIX_SAM.RP_IF_ICAS1_X_ORUDataIndex_XIX_Grundumfang_XIX_SAM <-> outer port RP_IF_ICAS1_X_ORUDataIndex_XIX_SAM
    delegate Grundumfang_XIX_SAM.RP_IF_ICC_eKiSi_Unterdrueck_XIX_Grundumfang_XIX_SAM <-> outer port RP_IF_ICC_eKiSi_Unterdrueck_XIX_SAM  # _XIX_SC_1488_SC_ComServFlex_HKeep_XIX_Softwareblock_XIX_ICAS1_X_SWCL_Housekeeping_XIX_Grundumfang_XIX_SAM_XIX_ICC_eKiSi_Unterdrueck
    delegate Grundumfang_XIX_SAM.RP_IF_ICC_Fernbed_ein_XIX_Grundumfang_XIX_SAM <-> outer port RP_IF_ICC_Fernbed_ein_XIX_SAM
    delegate Grundumfang_XIX_SAM.RP_IF_ICC_Innenraumbel_Unterdrueck_XIX_Grundumfang_XIX_SAM <-> outer port RP_IF_ICC_Innenraumbel_Unterdrueck_XIX_SAM  # _XIX_SC_1488_SC_ComServFlex_HKeep_XIX_Softwareblock_XIX_ICAS1_X_SWCL_Housekeeping_XIX_Grundumfang_XIX_SAM_XIX_ICC_Innenraumbel_Unterdrueck
    delegate SC_708_IuALicht_MEB_XIX_Softwareblock_XIX_SAM.RP_IF_ICC_Innenraumbel_Unterdrueck_XIX_SC_708_IuALicht_MEB_XIX_Softwareblock_XIX_SAM <-> outer port RP_IF_ICC_Innenraumbel_Unterdrueck_XIX_SAM  # _XIX_SC_1488_SC_ComServFlex_HKeep_XIX_Softwareblock_XIX_ICAS1_X_SWCL_Housekeeping_XIX_SC_708_IuALicht_MEB_XIX_Softwareblock_XIX_SAM_XIX_ICC_Innenraumbel_Unterdrueck
    delegate Grundumfang_XIX_SAM.RP_IF_KBI_Aussen_Temp_gef_XIX_Grundumfang_XIX_SAM <-> outer port RP_IF_KBI_Aussen_Temp_gef_XIX_SAM
    delegate Grundumfang_XIX_SAM.RP_IF_KBI_Kilometerstand_XIX_Grundumfang_XIX_SAM <-> outer port RP_IF_KBI_Kilometerstand_XIX_SAM
    delegate Grundumfang_XIX_SAM.RP_IF_KFG_ORUData_XIX_Grundumfang_XIX_SAM <-> outer port RP_IF_KFG_ORUData_XIX_SAM
    delegate Grundumfang_XIX_SAM.RP_IF_KFG_ORUDataIndex_XIX_Grundumfang_XIX_SAM <-> outer port RP_IF_KFG_ORUDataIndex_XIX_SAM
    delegate Grundumfang_XIX_SAM.RP_IF_KL_AL_HL_Anf_XIX_Grundumfang_XIX_SAM <-> outer port RP_IF_KL_AL_HL_Anf_XIX_SAM
    delegate Grundumfang_XIX_SAM.RP_IF_KL_AL_HR_Anf_XIX_Grundumfang_XIX_SAM <-> outer port RP_IF_KL_AL_HR_Anf_XIX_SAM
    delegate Grundumfang_XIX_SAM.RP_IF_KL_AL_VL_Anf_XIX_Grundumfang_XIX_SAM <-> outer port RP_IF_KL_AL_VL_Anf_XIX_SAM
    delegate Grundumfang_XIX_SAM.RP_IF_KL_AL_VR_Anf_XIX_Grundumfang_XIX_SAM <-> outer port RP_IF_KL_AL_VR_Anf_XIX_SAM
    delegate Grundumfang_XIX_SAM.RP_IF_KL_Defrost_LED_XIX_Grundumfang_XIX_SAM <-> outer port RP_IF_KL_Defrost_LED_XIX_SAM
    delegate Grundumfang_XIX_SAM.RP_IF_KL_FSH_LED_XIX_Grundumfang_XIX_SAM <-> outer port RP_IF_KL_FSH_LED_XIX_SAM
    delegate Grundumfang_XIX_SAM.RP_IF_KL_HSH_LED_XIX_Grundumfang_XIX_SAM <-> outer port RP_IF_KL_HSH_LED_XIX_SAM
    delegate Grundumfang_XIX_SAM.RP_IF_KL_LRH_Stufe_XIX_Grundumfang_XIX_SAM <-> outer port RP_IF_KL_LRH_Stufe_XIX_SAM
    delegate Grundumfang_XIX_SAM.RP_IF_KL_LRH_Taster_XIX_Grundumfang_XIX_SAM <-> outer port RP_IF_KL_LRH_Taster_XIX_SAM
    delegate Grundumfang_XIX_SAM.RP_IF_KL_SIL_Soll_li_XIX_Grundumfang_XIX_SAM <-> outer port RP_IF_KL_SIL_Soll_li_XIX_SAM
    delegate Grundumfang_XIX_SAM.RP_IF_KL_SIL_Soll_re_XIX_Grundumfang_XIX_SAM <-> outer port RP_IF_KL_SIL_Soll_re_XIX_SAM
    delegate Grundumfang_XIX_SAM.RP_IF_Klemmen_Status_01_BZ_XIX_Grundumfang_XIX_SAM <-> outer port RP_IF_Klemmen_Status_01_BZ_XIX_SAM
    delegate Grundumfang_XIX_SAM.RP_IF_Klemmen_Status_01_CRC_XIX_Grundumfang_XIX_SAM <-> outer port RP_IF_Klemmen_Status_01_CRC_XIX_SAM
    delegate Grundumfang_XIX_SAM.RP_IF_Klemmen_Steuerung_01_BZ_XIX_Grundumfang_XIX_SAM <-> outer port RP_IF_Klemmen_Steuerung_01_BZ_XIX_SAM
    delegate Grundumfang_XIX_SAM.RP_IF_Klemmen_Steuerung_01_CRC_XIX_Grundumfang_XIX_SAM <-> outer port RP_IF_Klemmen_Steuerung_01_CRC_XIX_SAM
    delegate Grundumfang_XIX_SAM.RP_IF_KST_Anf_Klemme_15_Auth_XIX_Grundumfang_XIX_SAM <-> outer port RP_IF_KST_Anf_Klemme_15_Auth_XIX_SAM
    delegate Grundumfang_XIX_SAM.RP_IF_KST_Anf_Klemme_S_XIX_Grundumfang_XIX_SAM <-> outer port RP_IF_KST_Anf_Klemme_S_XIX_SAM
    delegate Grundumfang_XIX_SAM.RP_IF_KST_KL15LockStatus_XIX_Grundumfang_XIX_SAM <-> outer port RP_IF_KST_KL15LockStatus_XIX_SAM
    delegate Grundumfang_XIX_SAM.RP_IF_KST_Sonderzustand_Anforderung_XIX_Grundumfang_XIX_SAM <-> outer port RP_IF_KST_Sonderzustand_Anforderung_XIX_SAM
    delegate Grundumfang_XIX_SAM.RP_IF_KST_Sonderzustand_Status_XIX_Grundumfang_XIX_SAM <-> outer port RP_IF_KST_Sonderzustand_Status_XIX_SAM
    delegate Grundumfang_XIX_SAM.RP_IF_KY_Ambex_Entfernung_Delta_IDG_{01..08}_XIX_Grundumfang_XIX_SAM <-> outer port RP_IF_KY_Ambex_Entfernung_Delta_IDG_{01..08}_XIX_SAM
    delegate Grundumfang_XIX_SAM.RP_IF_KY_Ambex_Entfernung_IDG_{01..08}_XIX_Grundumfang_XIX_SAM <-> outer port RP_IF_KY_Ambex_Entfernung_IDG_{01..08}_XIX_SAM
    delegate Grundumfang_XIX_SAM.RP_IF_KY_Ambex_Richtung_Delta_IDG_{01..08}_XIX_Grundumfang_XIX_SAM <-> outer port RP_IF_KY_Ambex_Richtung_Delta_IDG_{01..08}_XIX_SAM
    delegate Grundumfang_XIX_SAM.RP_IF_KY_Ambex_Richtung_IDG_{01..08}_XIX_Grundumfang_XIX_SAM <-> outer port RP_IF_KY_Ambex_Richtung_IDG_{01..08}_XIX_SAM
    delegate Grundumfang_XIX_SAM.RP_IF_LE1_ORUData_XIX_Grundumfang_XIX_SAM <-> outer port RP_IF_LE1_ORUData_XIX_SAM
    delegate Grundumfang_XIX_SAM.RP_IF_LE1_ORUDataIndex_XIX_Grundumfang_XIX_SAM <-> outer port RP_IF_LE1_ORUDataIndex_XIX_SAM
    delegate Grundumfang_XIX_SAM.RP_IF_LE1_TorqueLockStatus_XIX_Grundumfang_XIX_SAM <-> outer port RP_IF_LE1_TorqueLockStatus_XIX_SAM
    delegate Grundumfang_XIX_SAM.RP_IF_LE2_ORUData_XIX_Grundumfang_XIX_SAM <-> outer port RP_IF_LE2_ORUData_XIX_SAM
    delegate Grundumfang_XIX_SAM.RP_IF_LE2_ORUDataIndex_XIX_Grundumfang_XIX_SAM <-> outer port RP_IF_LE2_ORUDataIndex_XIX_SAM
    delegate Grundumfang_XIX_SAM.RP_IF_LE2_TorqueLockStatus_XIX_Grundumfang_XIX_SAM <-> outer port RP_IF_LE2_TorqueLockStatus_XIX_SAM
    delegate Grundumfang_XIX_SAM.RP_IF_Lenkhilfe_EPS_ORUData_XIX_Grundumfang_XIX_SAM <-> outer port RP_IF_Lenkhilfe_EPS_ORUData_XIX_SAM
    delegate Grundumfang_XIX_SAM.RP_IF_Lenkhilfe_EPS_ORUDataIndex_XIX_Grundumfang_XIX_SAM <-> outer port RP_IF_Lenkhilfe_EPS_ORUDataIndex_XIX_SAM
    delegate Grundumfang_XIX_SAM.RP_IF_Leselicht_hi_li_LED_defekt_XIX_Grundumfang_XIX_SAM <-> outer port RP_IF_Leselicht_hi_li_LED_defekt_XIX_SAM
    delegate Grundumfang_XIX_SAM.RP_IF_Leselicht_hi_li_SR3_LED_defekt_XIX_Grundumfang_XIX_SAM <-> outer port RP_IF_Leselicht_hi_li_SR3_LED_defekt_XIX_SAM
    delegate Grundumfang_XIX_SAM.RP_IF_Leselicht_hi_li_SR3_Taste_defekt_XIX_Grundumfang_XIX_SAM <-> outer port RP_IF_Leselicht_hi_li_SR3_Taste_defekt_XIX_SAM
    delegate Grundumfang_XIX_SAM.RP_IF_Leselicht_hi_li_Taste_defekt_XIX_Grundumfang_XIX_SAM <-> outer port RP_IF_Leselicht_hi_li_Taste_defekt_XIX_SAM
    delegate Grundumfang_XIX_SAM.RP_IF_Leselicht_hi_re_LED_defekt_XIX_Grundumfang_XIX_SAM <-> outer port RP_IF_Leselicht_hi_re_LED_defekt_XIX_SAM
    delegate Grundumfang_XIX_SAM.RP_IF_Leselicht_hi_re_SR3_LED_defekt_XIX_Grundumfang_XIX_SAM <-> outer port RP_IF_Leselicht_hi_re_SR3_LED_defekt_XIX_SAM
    delegate Grundumfang_XIX_SAM.RP_IF_Leselicht_hi_re_SR3_Taste_defekt_XIX_Grundumfang_XIX_SAM <-> outer port RP_IF_Leselicht_hi_re_SR3_Taste_defekt_XIX_SAM
    delegate Grundumfang_XIX_SAM.RP_IF_Leselicht_hi_re_Taste_defekt_XIX_Grundumfang_XIX_SAM <-> outer port RP_IF_Leselicht_hi_re_Taste_defekt_XIX_SAM
    delegate Grundumfang_XIX_SAM.RP_IF_Leselicht_vo_defekt_XIX_Grundumfang_XIX_SAM <-> outer port RP_IF_Leselicht_vo_defekt_XIX_SAM
    delegate Grundumfang_XIX_SAM.RP_IF_LIM_Tasten_Innenlicht_V_def_XIX_Grundumfang_XIX_SAM <-> outer port RP_IF_LIM_Tasten_Innenlicht_V_def_XIX_SAM
    delegate Grundumfang_XIX_SAM.RP_IF_LIN_SMLS_ECU_defekt_XIX_Grundumfang_XIX_SAM <-> outer port RP_IF_LIN_SMLS_ECU_defekt_XIX_SAM
    delegate Grundumfang_XIX_SAM.RP_IF_LIN_SMLS_elektrischer_Fehler_XIX_Grundumfang_XIX_SAM <-> outer port RP_IF_LIN_SMLS_elektrischer_Fehler_XIX_SAM
    delegate Grundumfang_XIX_SAM.RP_IF_LIN_SMLS_mechanischer_Fehler_XIX_Grundumfang_XIX_SAM <-> outer port RP_IF_LIN_SMLS_mechanischer_Fehler_XIX_SAM
    delegate Grundumfang_XIX_SAM.RP_IF_LIN_SMLS_RAM_ROM_Fehler_XIX_Grundumfang_XIX_SAM <-> outer port RP_IF_LIN_SMLS_RAM_ROM_Fehler_XIX_SAM
    delegate Grundumfang_XIX_SAM.RP_IF_LIN_SMLS_ResponseError_XIX_Grundumfang_XIX_SAM <-> outer port RP_IF_LIN_SMLS_ResponseError_XIX_SAM
    delegate Grundumfang_XIX_SAM.RP_IF_LIN_SMLS_Ueberspannung_XIX_Grundumfang_XIX_SAM <-> outer port RP_IF_LIN_SMLS_Ueberspannung_XIX_SAM
    delegate Grundumfang_XIX_SAM.RP_IF_LIN_SMLS_Unterspannung_XIX_Grundumfang_XIX_SAM <-> outer port RP_IF_LIN_SMLS_Unterspannung_XIX_SAM
    delegate Grundumfang_XIX_SAM.RP_IF_LIN_SMLS_Zaehler_XIX_Grundumfang_XIX_SAM <-> outer port RP_IF_LIN_SMLS_Zaehler_XIX_SAM
    delegate Grundumfang_XIX_SAM.RP_IF_LINDa_defekt_XIX_Grundumfang_XIX_SAM <-> outer port RP_IF_LINDa_defekt_XIX_SAM
    delegate Grundumfang_XIX_SAM.RP_IF_LINDa_ResponseError_XIX_Grundumfang_XIX_SAM <-> outer port RP_IF_LINDa_ResponseError_XIX_SAM
    delegate Grundumfang_XIX_SAM.RP_IF_LINDa_S_Rollo_vo_XIX_Grundumfang_XIX_SAM <-> outer port RP_IF_LINDa_S_Rollo_vo_XIX_SAM
    delegate Grundumfang_XIX_SAM.RP_IF_LLP_L_ORUData_XIX_Grundumfang_XIX_SAM <-> outer port RP_IF_LLP_L_ORUData_XIX_SAM
    delegate Grundumfang_XIX_SAM.RP_IF_LLP_L_ORUDataIndex_XIX_Grundumfang_XIX_SAM <-> outer port RP_IF_LLP_L_ORUDataIndex_XIX_SAM
    delegate Grundumfang_XIX_SAM.RP_IF_LLP_R_ORUData_XIX_Grundumfang_XIX_SAM <-> outer port RP_IF_LLP_R_ORUData_XIX_SAM
    delegate Grundumfang_XIX_SAM.RP_IF_LLP_R_ORUDataIndex_XIX_Grundumfang_XIX_SAM <-> outer port RP_IF_LLP_R_ORUDataIndex_XIX_SAM
    delegate Grundumfang_XIX_SAM.RP_IF_LLR_LL1_Blockierung_XIX_Grundumfang_XIX_SAM <-> outer port RP_IF_LLR_LL1_Blockierung_XIX_SAM
    delegate Grundumfang_XIX_SAM.RP_IF_LLR_LL1_CodierPinError_XIX_Grundumfang_XIX_SAM <-> outer port RP_IF_LLR_LL1_CodierPinError_XIX_SAM
    delegate Grundumfang_XIX_SAM.RP_IF_LLR_LL1_Ist_Drehzahl_XIX_Grundumfang_XIX_SAM <-> outer port RP_IF_LLR_LL1_Ist_Drehzahl_XIX_SAM
    delegate Grundumfang_XIX_SAM.RP_IF_LLR_LL1_Lokalaktiv_XIX_Grundumfang_XIX_SAM <-> outer port RP_IF_LLR_LL1_Lokalaktiv_XIX_SAM
    delegate Grundumfang_XIX_SAM.RP_IF_LLR_LL1_Luefter_defekt_XIX_Grundumfang_XIX_SAM <-> outer port RP_IF_LLR_LL1_Luefter_defekt_XIX_SAM
    delegate Grundumfang_XIX_SAM.RP_IF_LLR_LL1_ResponseError_XIX_Grundumfang_XIX_SAM <-> outer port RP_IF_LLR_LL1_ResponseError_XIX_SAM
    delegate Grundumfang_XIX_SAM.RP_IF_LLR_LL1_Ueberspannung_XIX_Grundumfang_XIX_SAM <-> outer port RP_IF_LLR_LL1_Ueberspannung_XIX_SAM
    delegate Grundumfang_XIX_SAM.RP_IF_LLR_LL1_Uebertemperatur_XIX_Grundumfang_XIX_SAM <-> outer port RP_IF_LLR_LL1_Uebertemperatur_XIX_SAM
    delegate Grundumfang_XIX_SAM.RP_IF_LLR_LL1_Unterspannung_XIX_Grundumfang_XIX_SAM <-> outer port RP_IF_LLR_LL1_Unterspannung_XIX_SAM
    delegate Grundumfang_XIX_SAM.RP_IF_LLR_LS1_Blockierung_XIX_Grundumfang_XIX_SAM <-> outer port RP_IF_LLR_LS1_Blockierung_XIX_SAM
    delegate Grundumfang_XIX_SAM.RP_IF_LLR_LS1_CodierPinError_XIX_Grundumfang_XIX_SAM <-> outer port RP_IF_LLR_LS1_CodierPinError_XIX_SAM
    delegate Grundumfang_XIX_SAM.RP_IF_LLR_LS1_Ist_Drehzahl_XIX_Grundumfang_XIX_SAM <-> outer port RP_IF_LLR_LS1_Ist_Drehzahl_XIX_SAM
    delegate Grundumfang_XIX_SAM.RP_IF_LLR_LS1_Lokalaktiv_XIX_Grundumfang_XIX_SAM <-> outer port RP_IF_LLR_LS1_Lokalaktiv_XIX_SAM
    delegate Grundumfang_XIX_SAM.RP_IF_LLR_LS1_Luefter_defekt_XIX_Grundumfang_XIX_SAM <-> outer port RP_IF_LLR_LS1_Luefter_defekt_XIX_SAM
    delegate Grundumfang_XIX_SAM.RP_IF_LLR_LS1_ResponseError_XIX_Grundumfang_XIX_SAM <-> outer port RP_IF_LLR_LS1_ResponseError_XIX_SAM
    delegate Grundumfang_XIX_SAM.RP_IF_LLR_LS1_Ueberspannung_XIX_Grundumfang_XIX_SAM <-> outer port RP_IF_LLR_LS1_Ueberspannung_XIX_SAM
    delegate Grundumfang_XIX_SAM.RP_IF_LLR_LS1_Uebertemperatur_XIX_Grundumfang_XIX_SAM <-> outer port RP_IF_LLR_LS1_Uebertemperatur_XIX_SAM
    delegate Grundumfang_XIX_SAM.RP_IF_LLR_LS1_Unterspannung_XIX_Grundumfang_XIX_SAM <-> outer port RP_IF_LLR_LS1_Unterspannung_XIX_SAM
    delegate Grundumfang_XIX_SAM.RP_IF_LLR_RL1_Blockierung_XIX_Grundumfang_XIX_SAM <-> outer port RP_IF_LLR_RL1_Blockierung_XIX_SAM
    delegate Grundumfang_XIX_SAM.RP_IF_LLR_RL1_CodierPinError_XIX_Grundumfang_XIX_SAM <-> outer port RP_IF_LLR_RL1_CodierPinError_XIX_SAM
    delegate Grundumfang_XIX_SAM.RP_IF_LLR_RL1_Ist_Drehzahl_XIX_Grundumfang_XIX_SAM <-> outer port RP_IF_LLR_RL1_Ist_Drehzahl_XIX_SAM
    delegate Grundumfang_XIX_SAM.RP_IF_LLR_RL1_Lokalaktiv_XIX_Grundumfang_XIX_SAM <-> outer port RP_IF_LLR_RL1_Lokalaktiv_XIX_SAM
    delegate Grundumfang_XIX_SAM.RP_IF_LLR_RL1_Luefter_defekt_XIX_Grundumfang_XIX_SAM <-> outer port RP_IF_LLR_RL1_Luefter_defekt_XIX_SAM
    delegate Grundumfang_XIX_SAM.RP_IF_LLR_RL1_ResponseError_XIX_Grundumfang_XIX_SAM <-> outer port RP_IF_LLR_RL1_ResponseError_XIX_SAM
    delegate Grundumfang_XIX_SAM.RP_IF_LLR_RL1_Ueberspannung_XIX_Grundumfang_XIX_SAM <-> outer port RP_IF_LLR_RL1_Ueberspannung_XIX_SAM
    delegate Grundumfang_XIX_SAM.RP_IF_LLR_RL1_Uebertemperatur_XIX_Grundumfang_XIX_SAM <-> outer port RP_IF_LLR_RL1_Uebertemperatur_XIX_SAM
    delegate Grundumfang_XIX_SAM.RP_IF_LLR_RL1_Unterspannung_XIX_Grundumfang_XIX_SAM <-> outer port RP_IF_LLR_RL1_Unterspannung_XIX_SAM
    delegate Grundumfang_XIX_SAM.RP_IF_LLR_RS1_Blockierung_XIX_Grundumfang_XIX_SAM <-> outer port RP_IF_LLR_RS1_Blockierung_XIX_SAM
    delegate Grundumfang_XIX_SAM.RP_IF_LLR_RS1_CodierPinError_XIX_Grundumfang_XIX_SAM <-> outer port RP_IF_LLR_RS1_CodierPinError_XIX_SAM
    delegate Grundumfang_XIX_SAM.RP_IF_LLR_RS1_Ist_Drehzahl_XIX_Grundumfang_XIX_SAM <-> outer port RP_IF_LLR_RS1_Ist_Drehzahl_XIX_SAM
    delegate Grundumfang_XIX_SAM.RP_IF_LLR_RS1_Lokalaktiv_XIX_Grundumfang_XIX_SAM <-> outer port RP_IF_LLR_RS1_Lokalaktiv_XIX_SAM
    delegate Grundumfang_XIX_SAM.RP_IF_LLR_RS1_Luefter_defekt_XIX_Grundumfang_XIX_SAM <-> outer port RP_IF_LLR_RS1_Luefter_defekt_XIX_SAM
    delegate Grundumfang_XIX_SAM.RP_IF_LLR_RS1_ResponseError_XIX_Grundumfang_XIX_SAM <-> outer port RP_IF_LLR_RS1_ResponseError_XIX_SAM
    delegate Grundumfang_XIX_SAM.RP_IF_LLR_RS1_Ueberspannung_XIX_Grundumfang_XIX_SAM <-> outer port RP_IF_LLR_RS1_Ueberspannung_XIX_SAM
    delegate Grundumfang_XIX_SAM.RP_IF_LLR_RS1_Uebertemperatur_XIX_Grundumfang_XIX_SAM <-> outer port RP_IF_LLR_RS1_Uebertemperatur_XIX_SAM
    delegate Grundumfang_XIX_SAM.RP_IF_LLR_RS1_Unterspannung_XIX_Grundumfang_XIX_SAM <-> outer port RP_IF_LLR_RS1_Unterspannung_XIX_SAM
    delegate Grundumfang_XIX_SAM.RP_IF_LnchCtl_StReq_XIX_Grundumfang_XIX_SAM <-> outer port RP_IF_LnchCtl_StReq_XIX_SAM
    delegate Grundumfang_XIX_SAM.RP_IF_LR_HZG_Konfiguration_XIX_Grundumfang_XIX_SAM <-> outer port RP_IF_LR_HZG_Konfiguration_XIX_SAM
    delegate Grundumfang_XIX_SAM.RP_IF_LR_HZG_Taster_on_off_XIX_Grundumfang_XIX_SAM <-> outer port RP_IF_LR_HZG_Taster_on_off_XIX_SAM
    delegate Grundumfang_XIX_SAM.RP_IF_LR_HZG_Temp_Sensor_XIX_Grundumfang_XIX_SAM <-> outer port RP_IF_LR_HZG_Temp_Sensor_XIX_SAM
    delegate Grundumfang_XIX_SAM.RP_IF_LRH_aktiv_XIX_Grundumfang_XIX_SAM <-> outer port RP_IF_LRH_aktiv_XIX_SAM
    delegate Grundumfang_XIX_SAM.RP_IF_LRH_On_Off_XIX_Grundumfang_XIX_SAM <-> outer port RP_IF_LRH_On_Off_XIX_SAM
    delegate Grundumfang_XIX_SAM.RP_IF_LRH_Stellglied_aktiv_XIX_Grundumfang_XIX_SAM <-> outer port RP_IF_LRH_Stellglied_aktiv_XIX_SAM
    delegate Grundumfang_XIX_SAM.RP_IF_LRL1_ORUData_XIX_Grundumfang_XIX_SAM <-> outer port RP_IF_LRL1_ORUData_XIX_SAM
    delegate Grundumfang_XIX_SAM.RP_IF_LRL1_ORUDataIndex_XIX_Grundumfang_XIX_SAM <-> outer port RP_IF_LRL1_ORUDataIndex_XIX_SAM
    delegate Grundumfang_XIX_SAM.RP_IF_LRL2_ORUData_XIX_Grundumfang_XIX_SAM <-> outer port RP_IF_LRL2_ORUData_XIX_SAM
    delegate Grundumfang_XIX_SAM.RP_IF_LRL2_ORUDataIndex_XIX_Grundumfang_XIX_SAM <-> outer port RP_IF_LRL2_ORUDataIndex_XIX_SAM
    delegate Grundumfang_XIX_SAM.RP_IF_LRL3_ORUData_XIX_Grundumfang_XIX_SAM <-> outer port RP_IF_LRL3_ORUData_XIX_SAM
    delegate Grundumfang_XIX_SAM.RP_IF_LRL3_ORUDataIndex_XIX_Grundumfang_XIX_SAM <-> outer port RP_IF_LRL3_ORUDataIndex_XIX_SAM
    delegate Grundumfang_XIX_SAM.RP_IF_LRL_L_01_BZ_XIX_Grundumfang_XIX_SAM <-> outer port RP_IF_LRL_L_01_BZ_XIX_SAM
    delegate Grundumfang_XIX_SAM.RP_IF_LRL_L_01_CRC_XIX_Grundumfang_XIX_SAM <-> outer port RP_IF_LRL_L_01_CRC_XIX_SAM
    delegate Grundumfang_XIX_SAM.RP_IF_LRL_M_01_BZ_XIX_Grundumfang_XIX_SAM <-> outer port RP_IF_LRL_M_01_BZ_XIX_SAM
    delegate Grundumfang_XIX_SAM.RP_IF_LRL_M_01_CRC_XIX_Grundumfang_XIX_SAM <-> outer port RP_IF_LRL_M_01_CRC_XIX_SAM
    delegate Grundumfang_XIX_SAM.RP_IF_LRL_R_01_BZ_XIX_Grundumfang_XIX_SAM <-> outer port RP_IF_LRL_R_01_BZ_XIX_SAM
    delegate Grundumfang_XIX_SAM.RP_IF_LRL_R_01_CRC_XIX_Grundumfang_XIX_SAM <-> outer port RP_IF_LRL_R_01_CRC_XIX_SAM
    delegate ABL_XIX_SAM.RP_IF_LS_Dunkel_XIX_ABL_XIX_SAM <-> outer port RP_IF_LS_Dunkel_XIX_SAM
    delegate Grundumfang_XIX_SAM.RP_IF_LS_Dunkel_XIX_Grundumfang_XIX_SAM <-> outer port RP_IF_LS_Dunkel_XIX_SAM
    delegate ABL_XIX_SAM.RP_IF_LS_Error_XIX_ABL_XIX_SAM <-> outer port RP_IF_LS_Error_XIX_SAM
    delegate Grundumfang_XIX_SAM.RP_IF_LS_Error_XIX_Grundumfang_XIX_SAM <-> outer port RP_IF_LS_Error_XIX_SAM
    delegate ABL_XIX_SAM.RP_IF_LS_Helligkeit_FW_XIX_ABL_XIX_SAM <-> outer port RP_IF_LS_Helligkeit_FW_XIX_SAM
    delegate Grundumfang_XIX_SAM.RP_IF_LS_Helligkeit_FW_XIX_Grundumfang_XIX_SAM <-> outer port RP_IF_LS_Helligkeit_FW_XIX_SAM
    delegate ABL_XIX_SAM.RP_IF_LS_Helligkeit_IR_XIX_ABL_XIX_SAM <-> outer port RP_IF_LS_Helligkeit_IR_XIX_SAM
    delegate Grundumfang_XIX_SAM.RP_IF_LS_Helligkeit_IR_XIX_Grundumfang_XIX_SAM <-> outer port RP_IF_LS_Helligkeit_IR_XIX_SAM
    delegate ABL_XIX_SAM.RP_IF_LS_Licht_ein_invers_XIX_ABL_XIX_SAM <-> outer port RP_IF_LS_Licht_ein_invers_XIX_SAM
    delegate Grundumfang_XIX_SAM.RP_IF_LS_Licht_ein_invers_XIX_Grundumfang_XIX_SAM <-> outer port RP_IF_LS_Licht_ein_invers_XIX_SAM
    delegate ABL_XIX_SAM.RP_IF_LS_Licht_ein_XIX_ABL_XIX_SAM <-> outer port RP_IF_LS_Licht_ein_XIX_SAM
    delegate Grundumfang_XIX_SAM.RP_IF_LS_Licht_ein_XIX_Grundumfang_XIX_SAM <-> outer port RP_IF_LS_Licht_ein_XIX_SAM
    delegate ABL_XIX_SAM.RP_IF_LS_TFL_mit_SL_ein_XIX_ABL_XIX_SAM <-> outer port RP_IF_LS_TFL_mit_SL_ein_XIX_SAM
    delegate Grundumfang_XIX_SAM.RP_IF_LS_TFL_mit_SL_ein_XIX_Grundumfang_XIX_SAM <-> outer port RP_IF_LS_TFL_mit_SL_ein_XIX_SAM
    delegate Grundumfang_XIX_SAM.RP_IF_LSS_Tastencode_XIX_Grundumfang_XIX_SAM <-> outer port RP_IF_LSS_Tastencode_XIX_SAM
    delegate Grundumfang_XIX_SAM.RP_IF_LTM_ResponseError_XIX_Grundumfang_XIX_SAM <-> outer port RP_IF_LTM_ResponseError_XIX_SAM
    delegate Grundumfang_XIX_SAM.RP_IF_LTM_StatusLichttastenmodul_XIX_Grundumfang_XIX_SAM <-> outer port RP_IF_LTM_StatusLichttastenmodul_XIX_SAM
    delegate Grundumfang_XIX_SAM.RP_IF_LV_Abblendlicht_Anzeige_XIX_Grundumfang_XIX_SAM <-> outer port RP_IF_LV_Abblendlicht_Anzeige_XIX_SAM
    delegate Grundumfang_XIX_SAM.RP_IF_LWR_SollDC_XIX_Grundumfang_XIX_SAM <-> outer port RP_IF_LWR_SollDC_XIX_SAM
    delegate Grundumfang_XIX_SAM.RP_IF_MaaSBladeMyc_ORUData_XIX_Grundumfang_XIX_SAM <-> outer port RP_IF_MaaSBladeMyc_ORUData_XIX_SAM
    delegate Grundumfang_XIX_SAM.RP_IF_MaaSBladeMyc_ORUDataIndex_XIX_Grundumfang_XIX_SAM <-> outer port RP_IF_MaaSBladeMyc_ORUDataIndex_XIX_SAM
    delegate Grundumfang_XIX_SAM.RP_IF_MainBlade_ORUData_XIX_Grundumfang_XIX_SAM <-> outer port RP_IF_MainBlade_ORUData_XIX_SAM
    delegate Grundumfang_XIX_SAM.RP_IF_MainBlade_ORUDataIndex_XIX_Grundumfang_XIX_SAM <-> outer port RP_IF_MainBlade_ORUDataIndex_XIX_SAM
    delegate Grundumfang_XIX_SAM.RP_IF_MF_DCDC_Istmodus_XIX_Grundumfang_XIX_SAM <-> outer port RP_IF_MF_DCDC_Istmodus_XIX_SAM
    delegate Grundumfang_XIX_SAM.RP_IF_MF_Fahrlicht_XIX_Grundumfang_XIX_SAM <-> outer port RP_IF_MF_Fahrlicht_XIX_SAM
    delegate Grundumfang_XIX_SAM.RP_IF_MF_Fernbed_ein_XIX_Grundumfang_XIX_SAM <-> outer port RP_IF_MF_Fernbed_ein_XIX_SAM
    delegate Grundumfang_XIX_SAM.RP_IF_MF_Frontintervall_XIX_Grundumfang_XIX_SAM <-> outer port RP_IF_MF_Frontintervall_XIX_SAM
    delegate Grundumfang_XIX_SAM.RP_IF_MF_Frontwaschen_XIX_Grundumfang_XIX_SAM <-> outer port RP_IF_MF_Frontwaschen_XIX_SAM
    delegate Grundumfang_XIX_SAM.RP_IF_MF_Fussraumbel_XIX_Grundumfang_XIX_SAM <-> outer port RP_IF_MF_Fussraumbel_XIX_SAM
    delegate Grundumfang_XIX_SAM.RP_IF_MF_Heckintervall_XIX_Grundumfang_XIX_SAM <-> outer port RP_IF_MF_Heckintervall_XIX_SAM
    delegate Grundumfang_XIX_SAM.RP_IF_MF_Heckwaschen_XIX_Grundumfang_XIX_SAM <-> outer port RP_IF_MF_Heckwaschen_XIX_SAM
    delegate Grundumfang_XIX_SAM.RP_IF_MF_Innenraumbel_Unterdrueck_XIX_Grundumfang_XIX_SAM <-> outer port RP_IF_MF_Innenraumbel_Unterdrueck_XIX_SAM
    delegate Grundumfang_XIX_SAM.RP_IF_MF_Innenraumbel_XIX_Grundumfang_XIX_SAM <-> outer port RP_IF_MF_Innenraumbel_XIX_SAM
    delegate Grundumfang_XIX_SAM.RP_IF_MF_Motorweiterlauf_XIX_Grundumfang_XIX_SAM <-> outer port RP_IF_MF_Motorweiterlauf_XIX_SAM
    delegate Grundumfang_XIX_SAM.RP_IF_MF_Signalhorn_XIX_Grundumfang_XIX_SAM <-> outer port RP_IF_MF_Signalhorn_XIX_SAM
    delegate Grundumfang_XIX_SAM.RP_IF_MF_Tippwischen_XIX_Grundumfang_XIX_SAM <-> outer port RP_IF_MF_Tippwischen_XIX_SAM
    delegate Grundumfang_XIX_SAM.RP_IF_MF_Variante_XIX_Grundumfang_XIX_SAM <-> outer port RP_IF_MF_Variante_XIX_SAM
    delegate Grundumfang_XIX_SAM.RP_IF_MF_Wischerstufe_1_XIX_Grundumfang_XIX_SAM <-> outer port RP_IF_MF_Wischerstufe_1_XIX_SAM
    delegate Grundumfang_XIX_SAM.RP_IF_MF_Wischerstufe_2_XIX_Grundumfang_XIX_SAM <-> outer port RP_IF_MF_Wischerstufe_2_XIX_SAM
    delegate Grundumfang_XIX_SAM.RP_IF_MFG_01_BZ_XIX_Grundumfang_XIX_SAM <-> outer port RP_IF_MFG_01_BZ_XIX_SAM
    delegate Grundumfang_XIX_SAM.RP_IF_MFG_01_CRC_XIX_Grundumfang_XIX_SAM <-> outer port RP_IF_MFG_01_CRC_XIX_SAM
